VERSION ""

NS_ :

BS_:

BU_: ECM
VAL_TABLE_ EngAutoStrtEnVal 3 "Not Available" 2 "Error" 1 "On" 0 "Off" ;
VAL_TABLE_ OperatorInducementSeverity 7 "Not Available / Not Supported" 6 "Reserved" 5 "Inducement Level 5" 4 "Inducement Level 4" 3 "Inducement Level 3" 2 "Inducement Level 2" 1 "Inducement Level 1" 0 "No Inducement Active" ;
VAL_TABLE_ DEFTankLowlevelLamp 7 "not available" 6 "reserved for SAE assignment" 5 "reserved for SAE assignment" 4 "On – fast blink (1 HZ)" 3 "reserved for SAE assignment" 2 "reserved for SAE assignment" 1 "On – solid" 0 "Off" ;
VAL_TABLE_ MonitorFaultStatus 1 "Fault Condition present" 0 "Fault condition Absent" ;
VAL_TABLE_ MonitorEntryStatus 1 "Monitor Entry Conditions met" 0 "Monitor Entry Not Met" ;
VAL_TABLE_ Vt_YesNo_2bit 3 "Not Available" 2 "Error" 1 "Yes" 0 "No" ;
VAL_TABLE_ Vt_ProgShiftDis 3 "Take no action" 2 "Reserved" 1 "Progressive shift is disabled" 0 "Progressive shift not disabled" ;
VAL_TABLE_ Vt_EngMomOvrSpdEn 3 "Take no action" 2 "Reserved" 1 "Moment. eng. overspeed enabled" 0 "Moment. eng. overspeed disabled" ;
VAL_TABLE_ Vt_SPN_0911 255 "Component ID not available" 254 "Error" 253 "No action to be taken" 252 "Reset all components" 251 "Reserved" 250 "Reserved" 249 "Manufacturer specific" 248 "Manufacturer specific" 247 "Manufacturer specific" 246 "Manufacturer specific" 245 "Manufacturer specific" 244 "Manufacturer specific" 243 "Manufacturer specific" 242 "Manufacturer specific" 241 "Manufacturer specific" 240 "Manufacturer specific" 239 "Not defined" 238 "Not defined" 237 "Not defined" 236 "Not defined" 235 "Not defined" 234 "Not defined" 233 "Not defined" 232 "Not defined" 231 "Not defined" 230 "Not defined" 229 "Not defined" 228 "Not defined" 227 "Not defined" 226 "Not defined" 225 "Not defined" 224 "Not defined" 223 "Not defined" 222 "Not defined" 221 "Not defined" 220 "Not defined" 219 "Not defined" 218 "Not defined" 217 "Not defined" 216 "Not defined" 215 "Not defined" 214 "Not defined" 213 "Not defined" 212 "Not defined" 211 "Not defined" 210 "Not defined" 209 "Not defined" 208 "Not defined" 207 "Not defined" 206 "Not defined" 205 "Not defined" 204 "Not defined" 203 "Not defined" 202 "Not defined" 201 "Not defined" 200 "Not defined" 199 "Not defined" 198 "Not defined" 197 "Not defined" 196 "Not defined" 195 "Not defined" 194 "Not defined" 193 "Not defined" 192 "Not defined" 191 "Not defined" 190 "Not defined" 189 "Not defined" 188 "Not defined" 187 "Not defined" 186 "Not defined" 185 "Not defined" 184 "Not defined" 183 "Not defined" 182 "Not defined" 181 "Not defined" 180 "Not defined" 179 "Not defined" 178 "Not defined" 177 "Not defined" 176 "Not defined" 175 "Not defined" 174 "Not defined" 173 "Not defined" 172 "Not defined" 171 "Not defined" 170 "Not defined" 169 "Not defined" 168 "Not defined" 167 "Not defined" 166 "Not defined" 165 "Not defined" 164 "Not defined" 163 "Not defined" 162 "Not defined" 161 "Not defined" 160 "Not defined" 159 "Not defined" 158 "Not defined" 157 "Not defined" 156 "Not defined" 155 "Not defined" 154 "Not defined" 153 "Not defined" 152 "Not defined" 151 "Not defined" 150 "Not defined" 149 "Not defined" 148 "Not defined" 147 "Not defined" 146 "Not defined" 145 "Not defined" 144 "Not defined" 143 "Not defined" 142 "Not defined" 141 "Not defined" 140 "Not defined" 139 "Not defined" 138 "Not defined" 137 "Not defined" 136 "Not defined" 135 "Not defined" 134 "Not defined" 133 "Not defined" 132 "Not defined" 131 "Not defined" 130 "Not defined" 129 "Not defined" 128 "Not defined" 127 "Not defined" 126 "Not defined" 125 "Not defined" 124 "Not defined" 123 "Not defined" 122 "Not defined" 121 "Not defined" 120 "Not defined" 119 "Not defined" 118 "Not defined" 117 "Not defined" 116 "Not defined" 115 "Not defined" 114 "Not defined" 113 "Not defined" 112 "Not defined" 111 "Not defined" 110 "Not defined" 109 "Not defined" 108 "Not defined" 107 "Not defined" 106 "Not defined" 105 "Not defined" 104 "Not defined" 103 "Not defined" 102 "Not defined" 101 "Not defined" 100 "Not defined" 99 "Not defined" 98 "Not defined" 97 "Not defined" 96 "Not defined" 95 "Not defined" 94 "Not defined" 93 "Not defined" 92 "Not defined" 91 "Not defined" 90 "Not defined" 89 "Not defined" 88 "Not defined" 87 "Not defined" 86 "Not defined" 85 "Not defined" 84 "Not defined" 83 "Not defined" 82 "Not defined" 81 "Not defined" 80 "Not defined" 79 "Not defined" 78 "Not defined" 77 "Not defined" 76 "Not defined" 75 "Not defined" 74 "Not defined" 73 "Not defined" 72 "Not defined" 71 "Not defined" 70 "Not defined" 69 "Not defined" 68 "Not defined" 67 "Not defined" 66 "Not defined" 65 "Not defined" 64 "Not defined" 63 "Driver card #2" 62 "Driver card #1" 61 "Tachograph" 60 "Not defined" 59 "Not defined" 58 "Not defined" 57 "Not defined" 56 "Not defined" 55 "Not defined" 54 "Not defined" 53 "Not defined" 52 "Not defined" 51 "Engine fuel filter" 50 "Engine oil filter" 49 "Engine air filter" 48 "Tires" 47 "Not defined" 46 "Not defined" 45 "Not defined" 44 "Not defined" 43 "Rear axle oil" 42 "Front axle oil" 41 "Not defined" 40 "Intermediate transmission oil" 39 "Trans oil filter transmission #1" 38 "Trans oil transmission #2" 37 "Trans oil transmission #1" 36 "Not defined" 35 "Steering oil" 34 "Not defined" 33 "Engine oil engine #2" 32 "Engine oil engine #1" 31 "Engine coolant filter change" 30 "Engine coolant change" 29 "Not defined" 28 "Not defined" 27 "Not defined" 26 "Not defined" 25 "Not defined" 24 "Not defined" 23 "Not defined" 22 "Not defined" 21 "Check vehicle speed limiter" 20 "Check exhaust gas" 19 "Check trip recorder" 18 "In-between check" 17 "Brake system special check" 16 "Reg. gen. check for entire veh." 15 "Brake lining: general" 14 "Brake lining; right rear axle #3" 13 "Brake lining; left rear axle #3" 12 "Brake lining; right rear axle #2" 11 "Brake lining; left rear axle #2" 10 "Not defined" 9 "Not defined" 8 "Not defined" 7 "Not defined" 6 "Not defined" 5 "Clutch lining" 4 "Brake lining; right rear axle" 3 "Brake lining; left rear axle" 2 "Brake lining; right front axle" 1 "Brake lining; left front axle" 0 "Service check for entire vehicle" ;
VAL_TABLE_ AFT_Heater_Control 3 "Heater off" 2 "Preheat 1" 1 "Preheat 2" 0 "Automatic" ;
VAL_TABLE_ ASCiiPROD1 122 "z" 121 "y" 120 "x" 119 "w" 118 "v" 117 "u" 116 "t" 115 "s" 114 "r" 113 "q" 112 "p" 111 "o" 110 "n" 109 "m" 108 "l" 107 "k" 106 "j" 105 "i" 104 "h" 103 "g" 102 "f" 101 "e" 100 "d" 99 "c" 98 "b" 97 "a" 42 "*" 90 "Z" 89 "Y" 88 "X" 87 "W" 86 "V" 85 "U" 84 "T" 83 "S" 82 "R" 81 "Q" 80 "P" 79 "O" 78 "N" 77 "M" 76 "L" 75 "K" 74 "J" 73 "I" 72 "H" 71 "G" 70 "F" 69 "E" 68 "D" 67 "C" 66 "B" 65 "A" 57 "9" 56 "8" 55 "7" 54 "6" 53 "5" 52 "4" 51 "3" 50 "2" 49 "1" 48 "0" ;
VAL_TABLE_ SPN7121 2 "Exhaust Pressure Control" 1 "Torque Control" 0 "Brake Disabled" ;
VAL_TABLE_ SPN7334 1 "active" 0 "inactive" ;
VAL_TABLE_ SPN7022 3 "not available" 2 "error" 1 "active" 0 "inactive" ;
VAL_TABLE_ RetarderInhibitEBSSwitchStatus 2 "Error" 1 "Active" 0 "Inactive" ;
VAL_TABLE_ Disable_Enable_Error 3 "Not available" 2 "Error" 1 "Enabled" 0 "Disabled" ;
VAL_TABLE_ ResultStatusOfPressBuild 2 "MinimumTime Expired" 1 "Maximum Time Expired" 0 "Pressure Reached Within Time" ;
VAL_TABLE_ EGRcancleRequest 1 "EGR Off" 0 "EGR On" ;
VAL_TABLE_ LowIdleControlParamSet 1 "AutoTransLowIdleControl" 0 "ManualTransLowIdleControl" ;
VAL_TABLE_ IntermedSpeedContParamSet 5 "Speed Govenor" 4 "Transmission Override Control" 3 "High PTO" 2 "Medium PTO" 1 "Base PTO" 0 "default" ;
VAL_TABLE_ CurrentWorkingModeOfEngineSpeed 2 "Crank Sig Missing or Not Plaus" 1 "Cams Sig Missing or Not Plaus" 0 "Both Sensors Working Correctly" ;
VAL_TABLE_ Flag 1 "Fault" 0 "No Fault" ;
VAL_TABLE_ DiagnosticTestAssignments_ETR 64 "Cancel Current Test" ;
VAL_TABLE_ Override_control_mode 3 "Not used" 2 "Pressure Control" 1 "Torque control" 0 "Override disabled" ;
VAL_TABLE_ ParticulateTrapActive_Inhibit 3 "not available" 2 "reserved for SAE assignment" 1 "inhibited" 0 "not inhibited" ;
VAL_TABLE_ ParticulateTrapStatus 7 "not available" 6 "reserved for SAE assignment" 5 "reserved for SAE assignment" 4 "reserved for SAE assignment" 3 "Regen needed highest level" 2 "Regen needed moderate level" 1 "Regen needed lowest level" 0 "Regeneration not needed" ;
VAL_TABLE_ PartTrActiveRegenStatus 3 "not available" 2 "RegenNeeded_AutoRegenImminent" 1 "active" 0 "not active" ;
VAL_TABLE_ PartTrPassiveRegenStatus 3 "not available" 2 "reserved for SAE assignment" 1 "active" 0 "not active" ;
VAL_TABLE_ ExhSysHiTempLampCommand 7 "not available" 6 "reserved for SAE assignment" 5 "reserved for SAE assignment" 4 "On fast blink 1Hz" 3 "reserved for SAE assignment" 2 "reserved for SAE assignment" 1 "On Solid" 0 "Off" ;
VAL_TABLE_ PartTrAutoActRegenInitiatConfig 3 "not available" 2 "reserved for SAE assignment" 1 "Enabled" 0 "Not Enabled" ;
VAL_TABLE_ TransDriveEngaged 3 "NotAvailable" 2 "Error" 1 "DriveIsEngaged" 0 "DriveNotEngaged" ;
VAL_TABLE_ OverrideControlMode 3 "not defined error" 2 "Speed control" 1 "Torque control" 0 "Override disabled" ;
VAL_TABLE_ ReturnCodePPprogMode 16 "EngineOperatingModeNotNoStrtMode" 15 "DataBlockTooLongToTransmit" 14 "InvalidPasswordLevelProvided" 13 "ParameterHasNoAssociatedTatFiled" 12 "Reserved" 11 "InvalidParamtersWereRequested" 10 "LengthOfDataProvidedTooLong_Shrt" 9 "DataBlockTooLongToTransmitNotPro" 8 "ProgrammingModeTimeout" 7 "CannotWRITEaReadOnlyField" 6 "CannotREADaWriteOnlyField" 5 "CalibrationMemoryFailure" 4 "VehicleMoving" 3 "EngineRunninge" 2 "ProprietaryPasswordNotMatch" 1 "CustomerPasswordNotMatch" 0 "ProgramCommandSuccessful" ;
VAL_TABLE_ ReturnCodesEIMprogram 20 "Prog messg pack receiv out seque" 19 "reserved for future use" 18 "Flash ROM segment not erased" 17 "TP data crc mismatch" 16 "Eng Op Mode not in No_Start" 15 "reserved for future use" 14 "reserved for future use" 13 "Improper command sequence" 12 "reserved for future use" 11 "Invalid parameters" 10 "Length of data 2 long or invalid" 9 "Multiple faults detected" 8 "Programming mode timeout" 7 "reserved for future use" 6 "Invalid strat or cal ROMchecksum" 5 "Flash programming failure" 4 "Vehicle moving" 3 "Engine running" 2 "Transp param password not match" 1 "Undefined request command" 0 "Programming command successful" ;
VAL_TABLE_ DiagnosticTestAssignments 82 "High Pressure Service Test" 72 "DFSOV Leak Test" 71 "Injector Leak Test" 70 "Doser Flow Test" 66 "Test of Cylinder Cut Out Test" 65 "Test of Cylinder Cut Out Test" 64 "Test of Cylinder Cut Out Test" 57 "Test of Cylinder Cut Out Test" 56 "Test of Cylinder Cut Out Test" 55 "Test of Cylinder Cut Out Test" 54 "Run Up Test" 18 "Compression Test" 52 "Actuator Test" ;
VAL_TABLE_ EGRactive 3 "not available not installed" 2 "EGR system not valid" 1 "EGR valve oopen" 0 "EGR valve closed" ;
VAL_TABLE_ Hex2ASCii 90 "Z" 89 "Y" 88 "X" 87 "W" 86 "V" 85 "U" 84 "T" 83 "S" 82 "R" 81 "Q" 80 "P" 79 "O" 78 "N" 77 "M" 76 "L" 75 "K" 74 "J" 73 "I" 72 "H" 71 "G" 70 "F" 69 "E" 68 "D" 67 "C" 66 "B" 65 "A" 57 "9" 56 "8" 55 "7" 54 "6" 53 "5" 52 "4" 51 "3" 50 "2" 49 "1" 48 "0" ;
VAL_TABLE_ NoRequest_RequestActive 1 "Request Active" 0 "No Request" ;
VAL_TABLE_ Acitve_NotActive2 1 "Not Active" 0 "Active" ;
VAL_TABLE_ StateOfTerminal15 1 "ON" 0 "OFF" ;
VAL_TABLE_ EDCmode 7 "shutoff" 6 "EDC in standalone mode" 5 "Afterrun" 4 "Normal STRT_S_AFTER_DUC" 2 "Normal STRT_S_DURING_DUC" 1 "Normal STRT_S_BEFORE_DUC" ;
VAL_TABLE_ Active_NotActive 1 "Active" 0 "Not Active" ;
VAL_TABLE_ EDCStatus 3 "Invalid Operating Mode" 2 "Invalid Operating Mode" 1 "Invalid Operating Mode" 0 "EDC Ok" ;
VAL_TABLE_ HCIMFlags 1 "Fault" 0 "No Fault" ;
VAL_TABLE_ ATConfigurationID 15 "TBD" 14 "TBD" 13 "TBD" 12 "TBD" 11 "TBD" 10 "TBD" 9 "TBD" 8 "TBD" 7 "TBD" 6 "TBD" 5 "TBD" 4 "TBD" 3 "TBD" 2 "TBD" 1 "TBD" 0 "TBD" ;
VAL_TABLE_ ShutdownRequest 3 "NA" 2 "Error" 1 "True" 0 "False" ;
VAL_TABLE_ OperatingModes 31 "ITEC Reserved" 30 "ITEC Reserved" 29 "ITEC Reserved" 28 "ITEC Reserved" 27 "ITEC Reserved" 26 "ITEC Reserved" 25 "ITEC Reserved" 24 "ForceRegen" 23 "ITEC Reserved" 22 "ITEC Reserved" 21 "RegenUnavail" 20 "Oxid Boost" 19 "DeSoot" 18 "NOx Boost" 17 "Normal" 16 "ITEC Reserved" ;
VAL_TABLE_ unused_16_ones 65535 "Correct Message Structure" ;
VAL_TABLE_ PanelBacklightDimmer 15 "100%" 14 "95%" 13 "89%" 12 "83%" 11 "77%" 10 "71%" 9 "65%" 8 "59%" 7 "53%" 6 "47%" 5 "41%" 4 "35%" 3 "29%" 2 "23%" 1 "15%" 0 "OFF" ;
VAL_TABLE_ DigitalInput 1 "On" 0 "Off" ;
VAL_TABLE_ RightSideOptionalSwitch 3 "Error" 2 "Up Position" 1 "Down Position" 0 "Center Position" ;
VAL_TABLE_ LeftSideOptionalSwitch 1 "Switch Depressed" 0 "Not Depressed" ;
VAL_TABLE_ Header 2 "Command Message" ;
VAL_TABLE_ Alarm 7 "Repetative One Short Beep" 6 "One Time Three Long Beeps" 5 "One Time Ten Short Beeps " 4 "One Time Five Short Beeps" 3 "One Time Short Beep" 2 "One Time Long Beep" 1 "Continuous Single Tone" 0 "Off" ;
VAL_TABLE_ DoorSwitch 1 "Doors Open" 0 "Doors Closed" ;
VAL_TABLE_ DiagnosticRequest 1 "Diagnostic Mode Active" 0 "Diagnostic Mode Inactive" ;
VAL_TABLE_ Accessory 1 "Accessory On" 0 "Accessory Off" ;
VAL_TABLE_ SwitchedIgnition 1 "Ignition On" 0 "Ignition Off" ;
VAL_TABLE_ PTOhours 1 "Engaged" 0 "Not Engaged" ;
VAL_TABLE_ PanelLightRequest 1 "Request" 0 "Not Request" ;
VAL_TABLE_ TextMessage 1 "ON" 0 "OFF" ;
VAL_TABLE_ SmokeMapSelectionID 3 "Request not avail from EIM" 2 "Smoke map 2" 1 "Smoke map 1" 0 "Smoke map 0" ;
VAL_TABLE_ VehicleStop 1 "Vehicle stop" 0 "No vehicle stop" ;
VAL_TABLE_ EDCstandAloneModeRequest 3 "as 01+ failure memory entry" 2 "as 01+ failure memory entry" 1 "EDC stand alone, ignore EIM" 0 "Normal EDC mode, specs by EIM" ;
VAL_TABLE_ EngineStopRequest 3 "not valid, as 00, FailMemEntry" 2 "not valid, as 00, FailMemEntry" 1 "Engine Stop Request" 0 "Normal mode, no stop request" ;
VAL_TABLE_ EngineStartRequest 3 "not valid, as 00, FailMemEntry" 2 "Emergency Start Request" 1 "Normal start request" 0 "Normal Mode, no start request" ;
VAL_TABLE_ LowIdleControllerIDparamSet 3 "invalid, use ID 0, FailMemEntry" 2 "Param set 2 for LICO" 1 "Param set 1 for LICO" 0 "Param set 0 (deafult) for LICO" ;
VAL_TABLE_ DrivelineEngagedInformation 3 "Request not avail from FFR-EIM" 2 "Error!!!!" 1 "Driveline Engaged" 0 "Driveline Disengaged" ;
VAL_TABLE_ MasterSlaveBankShutOff 3 "Request not avail from FFR-EIM" 2 "Error!!" 1 "Bank Shutoff Disabled" 0 "Bank Shutoff Enabled" ;
VAL_TABLE_ RampOffSwitch 3 "not valid, as 00, FailMemEntry" 2 "not valid, as 00, FailMemEntry" 1 "rampoff, setpoint applied direct" 0 "EDC ramp transition active" ;
VAL_TABLE_ StatusOfEngineBraking 3 "not valid, set 00, FailMemEntry" 2 "not valid, set 00, FailMemEntry" 1 "MBR active" 0 "MBR not active" ;
VAL_TABLE_ IDparamSet4HighIdleController 7 "invalid, use ID 0, FailMemEntry" 6 "invalid, use ID 0, FailMemEntry" 5 "Param set 5 for HICO" 4 "Param set 4 for HICO" 3 "Param set 3 for HICO" 2 "Param set 2 for HICO" 1 "Param set 1 for HICO" 0 "Param set 0 (default) for HICO" ;
VAL_TABLE_ IDparamForIntrmdtSpdCntrllr 7 "Param set 7 for ISCT" 6 "Param set 6 for ISCT" 5 "Param set 5 for ISCT" 4 "Param set 4 for ISCT" 3 "Param set 3 for ISCT" 2 "Param set 2 for ISCT" 1 "Param set 1 for ISCT" 0 "Param set 0 (default) for ISCT" ;
VAL_TABLE_ momentaryEngineOverspeedEnable 3 "invalid, meos disabled + failmem" 2 "invalid, meos disabled + failmem" 1 "meos enabled" 0 "meos disabled" ;
VAL_TABLE_ HCIM_fault_flag 1 "Fault" 0 "No fault" ;

BO_ 2365440512 EEC14: 8 Vector__XXX
 SG_ FuelType : 56|8@1+ (1,0) [0|255] "" Vector__XXX

BO_ 2560818944 DM32: 40 Vector__XXX
 SG_ DTC_Total_PrevActive_Time_5 : 296|16@1+ (0.2,0) [0|13107] "hr" Vector__XXX
 SG_ DTC_Total_Active_Time_5 : 280|16@1+ (0.2,0) [0|13107] "hr" Vector__XXX
 SG_ DTC_Time_Until_Derate_5 : 312|8@1+ (0.25,0) [0|63.75] "hr" Vector__XXX
 SG_ DTC_Total_PrevActive_Time_4 : 232|16@1+ (0.2,0) [0|13107] "hr" Vector__XXX
 SG_ DTC_Total_Active_Time_4 : 216|16@1+ (0.2,0) [0|13107] "hr" Vector__XXX
 SG_ DTC_Time_Until_Derate_4 : 248|8@1+ (0.25,0) [0|63.75] "hr" Vector__XXX
 SG_ DTC_Total_PrevActive_Time_3 : 168|16@1+ (0.2,0) [0|13107] "hr" Vector__XXX
 SG_ DTC_Total_Active_Time_3 : 152|16@1+ (0.2,0) [0|13107] "hr" Vector__XXX
 SG_ DTC_Time_Until_Derate_3 : 184|8@1+ (0.25,0) [0|63.75] "hr" Vector__XXX
 SG_ DTC_Total_PrevActive_Time_2 : 104|16@1+ (0.2,0) [0|13107] "hr" Vector__XXX
 SG_ DTC_Total_Active_Time_2 : 88|16@1+ (0.2,0) [0|13107] "hr" Vector__XXX
 SG_ DTC_Time_Until_Derate_2 : 120|8@1+ (0.25,0) [0|63.75] "hr" Vector__XXX
 SG_ DTC_Total_PrevActive_Time_1 : 40|16@1+ (0.2,0) [0|13107] "hr" Vector__XXX
 SG_ DTC_Total_Active_Time_1 : 24|16@1+ (0.2,0) [0|13107] "hr" Vector__XXX
 SG_ DTC_Time_Until_Derate_1 : 56|8@1+ (0.25,0) [0|63.75] "hr" Vector__XXX
 SG_ SPN5 : 256|16@1+ (1,0) [0|65536] "" Vector__XXX
 SG_ SPN4 : 192|16@1+ (1,0) [0|65536] "" Vector__XXX
 SG_ SPN3 : 128|16@1+ (1,0) [0|65536] "" Vector__XXX
 SG_ SPN2 : 64|16@1+ (1,0) [0|65536] "" Vector__XXX
 SG_ FailureModeIdentifier1 : 16|5@1+ (1,0) [0|0] "" Vector__XXX
 SG_ SPN1 : 0|16@1+ (1,0) [0|65536] "" Vector__XXX
 SG_ FailureModeIdentifier2 : 80|5@1+ (1,0) [0|0] "" Vector__XXX
 SG_ SPN5High : 277|3@1+ (1,0) [0|7] "" Vector__XXX
 SG_ SPN4High : 213|3@1+ (1,0) [0|7] "" Vector__XXX
 SG_ SPN3High : 149|3@1+ (1,0) [0|7] "" Vector__XXX
 SG_ SPN2High : 85|3@1+ (1,0) [0|7] "" Vector__XXX
 SG_ SPN1High : 21|3@1+ (1,0) [0|7] "" Vector__XXX

BO_ 2633926400 IT6: 8 Vector__XXX
 SG_ EngActualIgnTiming : 48|16@1- (0.0078125,-200) [-200|301.99] "Deg" Vector__XXX

BO_ 2365484270 TCO1: 8 Vector__XXX
 SG_ TachographVehicleSpeed : 48|16@1+ (0.00390625,0) [0|250.996] "km/h" Vector__XXX

BO_ 2566892544 EDR4: 8 Vector__XXX

BO_ 2566892288 EDR3: 8 Vector__XXX

BO_ 2566892032 EDR2: 8 Vector__XXX

BO_ 2566891776 EDR1: 8 Vector__XXX

BO_ 2566831399 FD_s39: 8 Vector__XXX
 SG_ FanSpeed_Rx : 16|16@1+ (0.125,0) [0|8031.875] "rpm" Vector__XXX

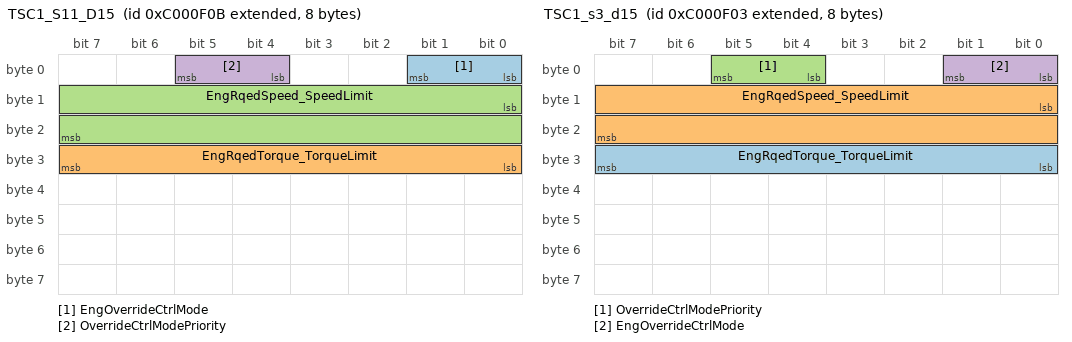
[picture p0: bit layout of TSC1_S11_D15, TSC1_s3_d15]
BO_ 2348814091 TSC1_S11_D15: 8 Vector__XXX
 SG_ EngOverrideCtrlMode : 0|2@1+ (1,0) [0|3] "" Vector__XXX
 SG_ EngRqedTorque_TorqueLimit : 24|8@1+ (1,-125) [-125|125] "%" Vector__XXX
 SG_ EngRqedSpeed_SpeedLimit : 8|16@1+ (0.125,0) [0|8031.875] "rpm" Vector__XXX
 SG_ OverrideCtrlModePriority : 4|2@1+ (1,0) [0|3] "" Vector__XXX

BO_ 2348814083 TSC1_s3_d15: 8 Vector__XXX
 SG_ EngRqedTorque_TorqueLimit : 24|8@1+ (1,-125) [-125|125] "%" Vector__XXX
 SG_ EngRqedSpeed_SpeedLimit : 8|16@1+ (0.125,0) [0|8031.875] "rpm" Vector__XXX
 SG_ OverrideCtrlModePriority : 4|2@1+ (1,0) [0|3] "" Vector__XXX
 SG_ EngOverrideCtrlMode : 0|2@1+ (1,0) [0|3] "" Vector__XXX

BO_ 2566820864 EAC: 8 Vector__XXX
 SG_ EngExRangeCoolantPres : 24|8@1+ (4,0) [0|1020] "kPa" Vector__XXX

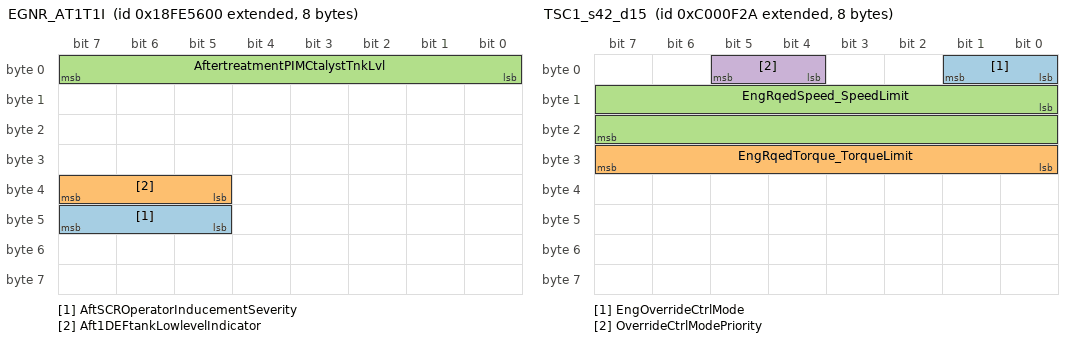
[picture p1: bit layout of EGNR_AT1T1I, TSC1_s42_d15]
BO_ 2566804992 EGNR_AT1T1I: 8 Vector__XXX
 SG_ AftSCROperatorInducementSeverity : 45|3@1- (1,0) [0|7] "" Vector__XXX
 SG_ Aft1DEFtankLowlevelIndicator : 37|3@1- (1,0) [0|7] "" Vector__XXX
 SG_ AftertreatmentPIMCtalystTnkLvl : 0|8@1+ (0.4,0) [0|100] "%" Vector__XXX

BO_ 2564816899 CM1_s03: 8 Vector__XXX
 SG_ Req_Pct_Fan_Speed_Trans : 0|8@1+ (0.4,0) [0|100] "%" Vector__XXX

BO_ 2633974265 PROP_RESET: 8 Vector__XXX
 SG_ PropResetInfo : 0|8@1+ (1,0) [0|255] "" Vector__XXX

BO_ 2364539392 ETC1_s0: 8 Vector__XXX
 SG_ TransOutputShaftSpeed_Tx : 8|16@1+ (0.125,0) [0|8031.875] "rpm" Vector__XXX

BO_ 2348814122 TSC1_s42_d15: 8 Vector__XXX
 SG_ EngOverrideCtrlMode : 0|2@1+ (1,0) [0|3] "" Vector__XXX
 SG_ EngRqedTorque_TorqueLimit : 24|8@1+ (1,-125) [-125|125] "%" Vector__XXX
 SG_ EngRqedSpeed_SpeedLimit : 8|16@1+ (0.125,0) [0|8031.875] "rpm" Vector__XXX
 SG_ OverrideCtrlModePriority : 4|2@1+ (1,0) [0|3] "" Vector__XXX

BO_ 2566803754 ACC2_s42: 8 Vector__XXX
 SG_ ReqACCDistMode : 5|3@1+ (1,0) [0|7] "" Vector__XXX

BO_ 2564882176 CM1_s0: 8 Vector__XXX
 SG_ Req_Pct_Fan_Speed_ECM : 0|8@1+ (0.4,0) [0|100] "%" Vector__XXX

BO_ 2631859961 RESET_s249: 8 Vector__XXX
 SG_ EST_Trip_Reset : 2|2@1+ (1,0) [0|3] "" Vector__XXX

BO_ 2561081377 AUXIO2_s33: 8 Vector__XXX
 SG_ GovSelSwitch : 4|2@1+ (1,0) [0|3] "" Vector__XXX
 SG_ DataLogSwitch : 6|2@1+ (1,0) [0|3] "" Vector__XXX

BO_ 2566844683 CCVS_s11: 8 Vector__XXX
 SG_ WheelBasedVehicleSpeed : 8|16@1+ (0.00390625,0) [0|250.996] "km/h" Vector__XXX

BO_ 2566844714 CCVS_s42: 8 Vector__XXX
 SG_ CruiseCtrlResumeSwitch : 36|2@1+ (1,0) [0|3] "" Vector__XXX
 SG_ CruiseCtrlPauseSwitch : 4|2@1+ (1,0) [0|3] "" Vector__XXX

BO_ 2566847009 BRAKES: 8 Vector__XXX
 SG_ Brake_Primary_Pressure : 8|8@1+ (4,0) [0|1020] "kPa" Vector__XXX

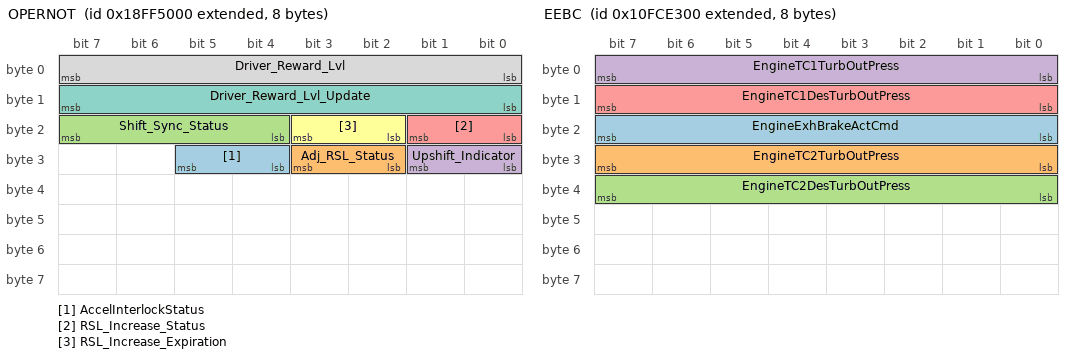
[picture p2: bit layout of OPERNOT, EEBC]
BO_ 2566868992 OPERNOT: 8 Vector__XXX
 SG_ AccelInterlockStatus : 28|2@1+ (1,0) [0|3] "" Vector__XXX
 SG_ Adj_RSL_Status : 26|2@1+ (1,0) [0|3] "" Vector__XXX
 SG_ Shift_Sync_Status : 20|4@1+ (1,0) [0|15] "" Vector__XXX
 SG_ Upshift_Indicator : 24|2@1+ (1,0) [0|3] "" Vector__XXX
 SG_ RSL_Increase_Status : 16|2@1+ (1,0) [0|3] "" Vector__XXX
 SG_ RSL_Increase_Expiration : 18|2@1+ (1,0) [0|3] "" Vector__XXX
 SG_ Driver_Reward_Lvl_Update : 8|8@1+ (1,0) [0|255] "" Vector__XXX
 SG_ Driver_Reward_Lvl : 0|8@1+ (1,0) [0|255] "" Vector__XXX

BO_ 2432498944 EEC9: 8 Vector__XXX
 SG_ EngCmdFuelRailPress : 32|16@1+ (0.00390625,0) [0|251] "MPa" Vector__XXX

BO_ 2565865470 PROMODE1_sxx: 8 Vector__XXX
 SG_ OpModeReq : 0|32@1+ (1,0) [0|4294967295] "" Vector__XXX

BO_ 2565865216 PROMODE1_s0: 8 Vector__XXX
 SG_ OpModeCur : 32|32@1+ (1,0) [0|4294967295] "" Vector__XXX

BO_ 2633936896 TTI2: 20 Vector__XXX
 SG_ TripEngRunTime : 64|32@1+ (0.05,0) [0|214748364.75] "hr" Vector__XXX
 SG_ TripIdleTime : 96|32@1+ (0.05,0) [0|214748364.75] "hr" Vector__XXX

BO_ 2633939200 LTFI: 22 Vector__XXX
 SG_ TripPTOStaFuelUsed : 64|32@1+ (0.5,0) [0|2147483647.5] "L" Vector__XXX
 SG_ TripPTOMovingFuelUsed : 32|32@1+ (0.5,0) [0|2147483647.5] "L" Vector__XXX
 SG_ TripIdleFuelUsed : 96|32@1+ (0.5,0) [0|2147483647.5] "L" Vector__XXX

BO_ 2432520704 ECCVC: 8 Vector__XXX
 SG_ EngAuxCoolerSupValve2 : 32|8@1+ (0.4,0) [0|102] "%" Vector__XXX
 SG_ EngAuxCoolerSupValve1 : 24|8@1+ (0.4,0) [0|102] "%" Vector__XXX

BO_ 2432492288 EEBC: 8 Vector__XXX
 SG_ EngineExhBrakeActCmd : 16|8@1+ (0.4,0) [0|102] "%" Vector__XXX
 SG_ EngineTC2TurbOutPress : 24|8@1+ (2,0) [0|510] "kPa" Vector__XXX
 SG_ EngineTC2DesTurbOutPress : 32|8@1+ (2,0) [0|510] "kPa" Vector__XXX
 SG_ EngineTC1TurbOutPress : 0|8@1+ (2,0) [0|510] "kPa" Vector__XXX
 SG_ EngineTC1DesTurbOutPress : 8|8@1+ (2,0) [0|510] "kPa" Vector__XXX

BO_ 2633927680 AAI: 8 Vector__XXX
 SG_ Relative_Humidity : 48|8@1+ (0.4,0) [0|102] "%" Vector__XXX

BO_ 2566861857 EWE_s33: 8 Vector__XXX
 SG_ EngineWarmupEnable : 16|2@1+ (1,0) [0|3] "" Vector__XXX

BO_ 2566848256 WIF: 8 Vector__XXX
 SG_ WIF : 0|2@1+ (1,0) [0|3] "" Vector__XXX

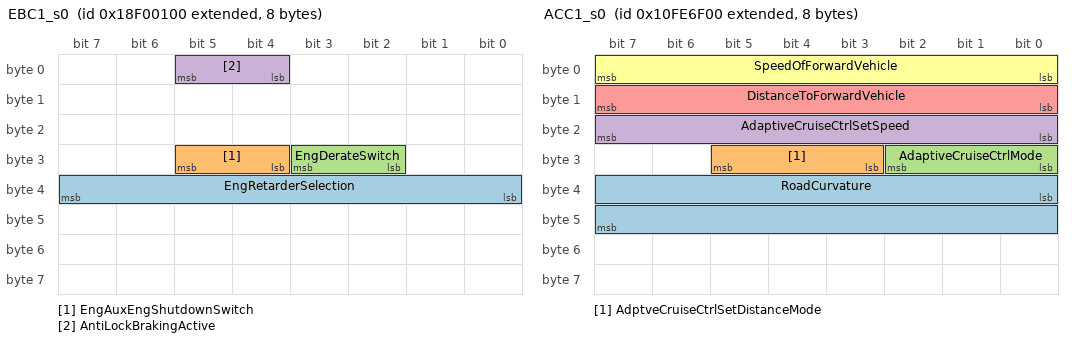
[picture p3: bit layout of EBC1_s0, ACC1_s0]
BO_ 2565865728 EBC1_s0: 8 Vector__XXX
 SG_ EngRetarderSelection : 32|8@1+ (0.4,0) [0|100] "%" Vector__XXX
 SG_ EngAuxEngShutdownSwitch : 28|2@1+ (1,0) [0|3] "" Vector__XXX
 SG_ EngDerateSwitch : 26|2@1+ (1,0) [0|3] "" Vector__XXX
 SG_ AntiLockBrakingActive : 4|2@1+ (1,0) [0|3] "" Vector__XXX

BO_ 2566854656 AETP: 8 Vector__XXX
 SG_ ActualEngineTorque : 0|8@1+ (30,0) [0|7500] "N.m" Vector__XXX

BO_ 2432593664 ACC1_s0: 8 Vector__XXX
 SG_ RoadCurvature : 32|16@1+ (0.0078125,-250) [-250|251.992] "1/km" Vector__XXX
 SG_ AdptveCruiseCtrlSetDistanceMode : 27|3@1+ (1,0) [0|7] "" Vector__XXX
 SG_ AdaptiveCruiseCtrlMode : 24|3@1+ (1,0) [0|7] "" Vector__XXX
 SG_ AdaptiveCruiseCtrlSetSpeed : 16|8@1+ (1,0) [0|250] "km/h" Vector__XXX
 SG_ DistanceToForwardVehicle : 8|8@1+ (1,0) [0|250] "m" Vector__XXX
 SG_ SpeedOfForwardVehicle : 0|8@1+ (1,0) [0|250] "km/h" Vector__XXX

BO_ 2364539681 EEC2_s21: 8 Vector__XXX
 SG_ RemoteAccelPedalPos : 24|8@1+ (0.4,0) [0|100] "%" Vector__XXX

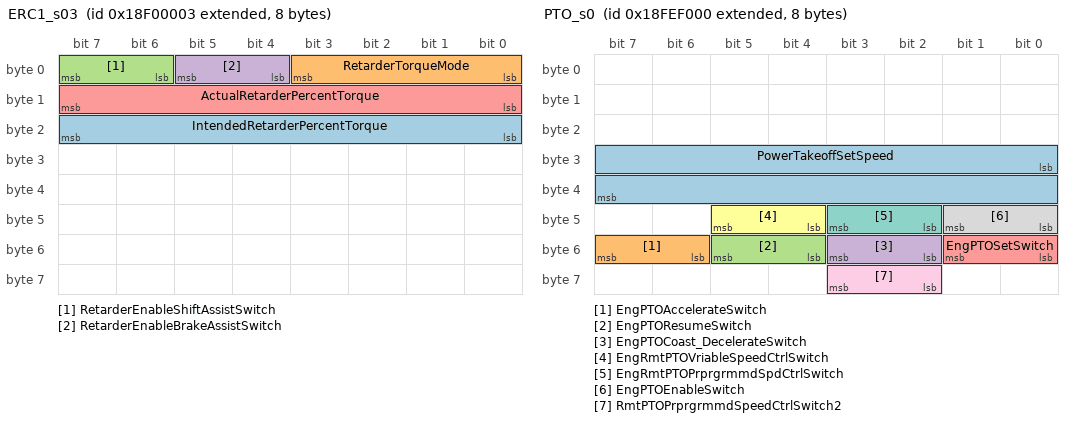
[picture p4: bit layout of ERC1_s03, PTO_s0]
BO_ 2565865475 ERC1_s03: 8 Vector__XXX
 SG_ IntendedRetarderPercentTorque : 16|8@1- (1,-125) [-125|125] "" Vector__XXX
 SG_ RetarderTorqueMode : 0|4@1- (1,0) [0|15] "" Vector__XXX
 SG_ RetarderEnableShiftAssistSwitch : 6|2@1+ (1,0) [0|3] "" Vector__XXX
 SG_ RetarderEnableBrakeAssistSwitch : 4|2@1+ (1,0) [0|3] "" Vector__XXX
 SG_ ActualRetarderPercentTorque : 8|8@1+ (1,-125) [-125|125] "%" Vector__XXX

BO_ 2566844416 PTO_s0: 8 Vector__XXX
 SG_ PowerTakeoffSetSpeed : 24|16@1+ (0.125,0) [0|8031.875] "rpm" Vector__XXX
 SG_ EngPTOAccelerateSwitch : 54|2@1+ (1,0) [0|3] "" Vector__XXX
 SG_ EngPTOResumeSwitch : 52|2@1+ (1,0) [0|3] "" Vector__XXX
 SG_ EngPTOCoast_DecelerateSwitch : 50|2@1+ (1,0) [0|3] "" Vector__XXX
 SG_ EngPTOSetSwitch : 48|2@1+ (1,0) [0|3] "" Vector__XXX
 SG_ EngRmtPTOVriableSpeedCtrlSwitch : 44|2@1+ (1,0) [0|3] "" Vector__XXX
 SG_ EngRmtPTOPrprgrmmdSpdCtrlSwitch : 42|2@1+ (1,0) [0|3] "" Vector__XXX
 SG_ EngPTOEnableSwitch : 40|2@1+ (1,0) [0|3] "" Vector__XXX
 SG_ RmtPTOPrprgrmmdSpeedCtrlSwitch2 : 58|2@1+ (1,0) [0|3] "" Vector__XXX

BO_ 2633935104 EO1: 8 Vector__XXX
 SG_ DesiredExhaustO2 : 16|16@1+ (0.0025,0) [0|160.6375] "%" Vector__XXX

BO_ 2566743296 AT1FC2: 8 Vector__XXX
 SG_ AT1HCDoserInFuelTemp : 40|8@1+ (1,-40) [-40|210] "°C" Vector__XXX
 SG_ Aftertreatment1FuelPress2 : 0|16@1+ (0.1,0) [0|6425.5] "kPa" Vector__XXX

BO_ 2566725632 A1DOC: 8 Vector__XXX
 SG_ Aftertreatment1DOCOutTemp : 16|16@1- (0.03125,-273) [-273|1734.96875] "deg C" Vector__XXX
 SG_ Aftertreatment1DOCInTemp : 0|16@1- (0.03125,-273) [-273|1734.96875] "deg C" Vector__XXX

BO_ 2633925376 IT2: 8 Vector__XXX
 SG_ EngCylinderIgnTiming6 : 16|16@1- (0.0078125,-200) [-200|301.99] "Deg" Vector__XXX
 SG_ EngCylinderIgnTiming5 : 0|16@1- (0.0078125,-200) [-200|301.99] "Deg" Vector__XXX

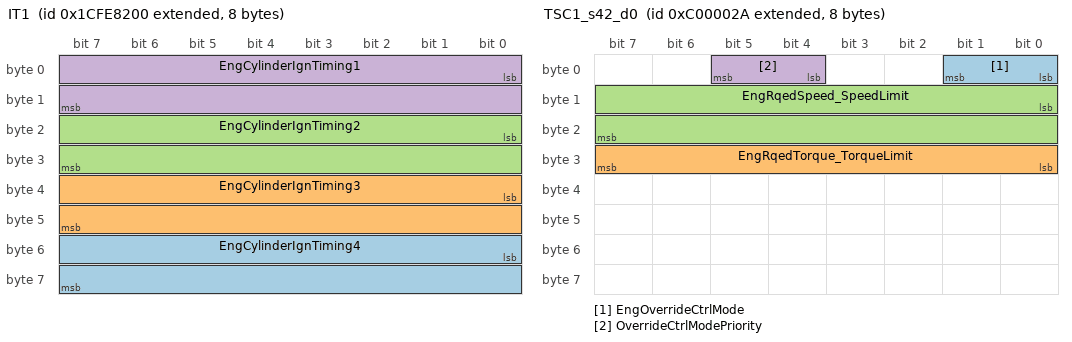
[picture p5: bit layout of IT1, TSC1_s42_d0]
BO_ 2633925120 IT1: 8 Vector__XXX
 SG_ EngCylinderIgnTiming4 : 48|16@1- (0.0078125,-200) [-200|301.99] "Deg" Vector__XXX
 SG_ EngCylinderIgnTiming3 : 32|16@1- (0.0078125,-200) [-200|301.99] "Deg" Vector__XXX
 SG_ EngCylinderIgnTiming2 : 16|16@1- (0.0078125,-200) [-200|301.99] "Deg" Vector__XXX
 SG_ EngCylinderIgnTiming1 : 0|16@1- (0.0078125,-200) [-200|301.99] "Deg" Vector__XXX

BO_ 2566886649 RQST_STR_S249_dall: 8 Vector__XXX
 SG_ Test_ID : 0|8@1- (1,0) [0|255] "" Vector__XXX

BO_ 2348810282 TSC1_s42_d0: 8 Vector__XXX
 SG_ EngOverrideCtrlMode : 0|2@1+ (1,0) [0|3] "" Vector__XXX
 SG_ EngRqedTorque_TorqueLimit : 24|8@1+ (1,-125) [-125|125] "%" Vector__XXX
 SG_ EngRqedSpeed_SpeedLimit : 8|16@1+ (0.125,0) [0|8031.875] "rpm" Vector__XXX
 SG_ OverrideCtrlModePriority : 4|2@1+ (1,0) [0|3] "" Vector__XXX

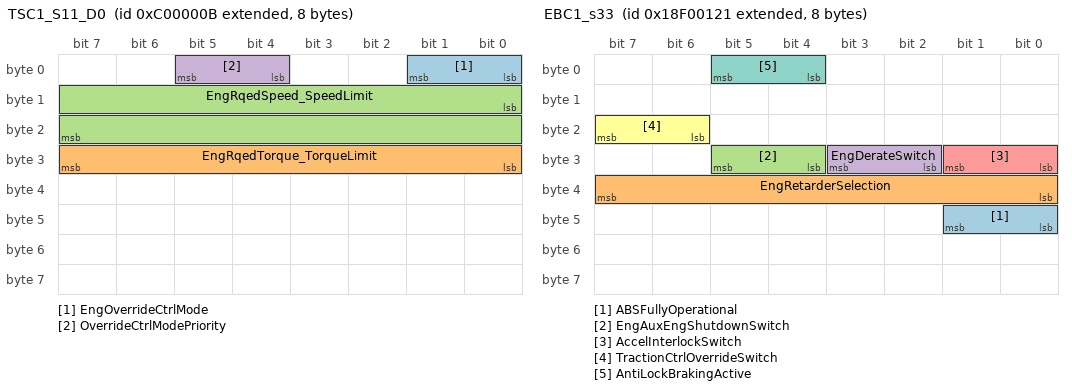
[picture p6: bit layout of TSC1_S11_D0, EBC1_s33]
BO_ 2348810251 TSC1_S11_D0: 8 Vector__XXX
 SG_ EngOverrideCtrlMode : 0|2@1+ (1,0) [0|3] "" Vector__XXX
 SG_ EngRqedTorque_TorqueLimit : 24|8@1+ (1,-125) [-125|125] "%" Vector__XXX
 SG_ EngRqedSpeed_SpeedLimit : 8|16@1+ (0.125,0) [0|8031.875] "rpm" Vector__XXX
 SG_ OverrideCtrlModePriority : 4|2@1+ (1,0) [0|3] "" Vector__XXX

BO_ 2565603105 TPDT_s33: 8 Vector__XXX
 SG_ SequenceNumber : 0|8@1+ (1,0) [0|252] "" Vector__XXX

BO_ 2565668641 TPCM_s33_dall: 8 Vector__XXX
 SG_ TotalNumberOfPacketsEoMA m19 : 24|8@1+ (1,0) [0|255] "" Vector__XXX
 SG_ TotalMessageSizeEoMA m19 : 8|16@1+ (1,0) [0|64255] "counts" Vector__XXX
 SG_ TotalMessageSizeBAM m32 : 8|16@1+ (1,0) [0|64255] "counts" Vector__XXX
 SG_ TotalNumberOfPacketsBAM m32 : 24|8@1+ (1,0) [0|255] "" Vector__XXX
 SG_ ConnectionAbortReason m255 : 8|8@1+ (1,0) [0|255] "" Vector__XXX
 SG_ NextPacketNumberToBeSent m17 : 16|8@1+ (1,0) [0|255] "" Vector__XXX
 SG_ NumberOfPacketsThatCanBeSent m17 : 8|8@1+ (1,0) [0|255] "" Vector__XXX
 SG_ PGNumber : 40|24@1+ (1,0) [0|16777200] "" Vector__XXX
 SG_ MaximumNumberOfPackets m16 : 32|8@1+ (1,0) [0|255] "" Vector__XXX
 SG_ TotalNumberOfPackets m16 : 24|8@1+ (1,0) [0|255] "" Vector__XXX
 SG_ TotalMessageSize m16 : 8|16@1+ (1,0) [0|64255] "counts" Vector__XXX
 SG_ ControlByte M : 0|8@1+ (1,0) [0|255] "" Vector__XXX

BO_ 2565611799 TPCM_s23_d33: 8 Vector__XXX
 SG_ TotalNumberOfPacketsEoMA m19 : 24|8@1+ (1,0) [0|255] "" Vector__XXX
 SG_ TotalMessageSizeEoMA m19 : 8|16@1+ (1,0) [0|64255] "counts" Vector__XXX
 SG_ TotalMessageSizeBAM m32 : 8|16@1+ (1,0) [0|64255] "counts" Vector__XXX
 SG_ TotalNumberOfPacketsBAM m32 : 24|8@1+ (1,0) [0|255] "" Vector__XXX
 SG_ ConnectionAbortReason m255 : 8|8@1+ (1,0) [0|255] "" Vector__XXX
 SG_ NextPacketNumberToBeSent m17 : 16|8@1+ (1,0) [0|255] "" Vector__XXX
 SG_ NumberOfPacketsThatCanBeSent m17 : 8|8@1+ (1,0) [0|255] "" Vector__XXX
 SG_ PGNumber : 40|24@1+ (1,0) [0|16777200] "" Vector__XXX
 SG_ MaximumNumberOfPackets m16 : 32|8@1+ (1,0) [0|255] "" Vector__XXX
 SG_ TotalNumberOfPackets m16 : 24|8@1+ (1,0) [0|255] "" Vector__XXX
 SG_ TotalMessageSize m16 : 8|16@1+ (1,0) [0|64255] "counts" Vector__XXX
 SG_ ControlByte M : 0|8@1+ (1,0) [0|255] "" Vector__XXX

BO_ 2565603351 TPCM_s23_d0: 8 Vector__XXX
 SG_ TotalNumberOfPacketsEoMA m19 : 24|8@1+ (1,0) [0|255] "" Vector__XXX
 SG_ TotalMessageSizeEoMA m19 : 8|16@1+ (1,0) [0|64255] "counts" Vector__XXX
 SG_ TotalMessageSizeBAM m32 : 8|16@1+ (1,0) [0|64255] "counts" Vector__XXX
 SG_ TotalNumberOfPacketsBAM m32 : 24|8@1+ (1,0) [0|255] "" Vector__XXX
 SG_ ConnectionAbortReason m255 : 8|8@1+ (1,0) [0|255] "" Vector__XXX
 SG_ NextPacketNumberToBeSent m17 : 16|8@1+ (1,0) [0|255] "" Vector__XXX
 SG_ NumberOfPacketsThatCanBeSent m17 : 8|8@1+ (1,0) [0|255] "" Vector__XXX
 SG_ PGNumber : 40|24@1+ (1,0) [0|16777200] "" Vector__XXX
 SG_ MaximumNumberOfPackets m16 : 32|8@1+ (1,0) [0|255] "" Vector__XXX
 SG_ TotalNumberOfPackets m16 : 24|8@1+ (1,0) [0|255] "" Vector__XXX
 SG_ TotalMessageSize m16 : 8|16@1+ (1,0) [0|64255] "counts" Vector__XXX
 SG_ ControlByte M : 0|8@1+ (1,0) [0|255] "" Vector__XXX

BO_ 2565668631 TPCM_s23: 8 Vector__XXX
 SG_ TotalNumberOfPacketsEoMA m19 : 24|8@1+ (1,0) [0|255] "" Vector__XXX
 SG_ TotalMessageSizeEoMA m19 : 8|16@1+ (1,0) [0|64255] "counts" Vector__XXX
 SG_ TotalMessageSizeBAM m32 : 8|16@1+ (1,0) [0|64255] "counts" Vector__XXX
 SG_ TotalNumberOfPacketsBAM m32 : 24|8@1+ (1,0) [0|255] "" Vector__XXX
 SG_ ConnectionAbortReason m255 : 8|8@1+ (1,0) [0|255] "" Vector__XXX
 SG_ NextPacketNumberToBeSent m17 : 16|8@1+ (1,0) [0|255] "" Vector__XXX
 SG_ NumberOfPacketsThatCanBeSent m17 : 8|8@1+ (1,0) [0|255] "" Vector__XXX
 SG_ PGNumber : 40|24@1+ (1,0) [0|16777200] "" Vector__XXX
 SG_ MaximumNumberOfPackets m16 : 32|8@1+ (1,0) [0|255] "" Vector__XXX
 SG_ TotalNumberOfPackets m16 : 24|8@1+ (1,0) [0|255] "" Vector__XXX
 SG_ TotalMessageSize m16 : 8|16@1+ (1,0) [0|64255] "counts" Vector__XXX
 SG_ ControlByte M : 0|8@1+ (1,0) [0|255] "" Vector__XXX

BO_ 2565479447 RQST_d28: 3 Vector__XXX
 SG_ ParameterGroupNumber : 0|24@1+ (1,0) [0|16777215] "" Vector__XXX

BO_ 2566841600 HOURS: 8 Vector__XXX
 SG_ EngTotalRevolutions : 32|32@1+ (1000,0) [0|4.211081215E+012] "r" Vector__XXX
 SG_ EngTotalHoursOfOperation : 0|32@1+ (0.05,0) [0|210554060.75] "hr" Vector__XXX

BO_ 2565865761 EBC1_s33: 8 Vector__XXX
 SG_ ABSFullyOperational : 40|2@1+ (1,0) [0|3] "" Vector__XXX
 SG_ EngRetarderSelection : 32|8@1+ (0.4,0) [0|100] "%" Vector__XXX
 SG_ EngAuxEngShutdownSwitch : 28|2@1+ (1,0) [0|3] "" Vector__XXX
 SG_ EngDerateSwitch : 26|2@1+ (1,0) [0|3] "" Vector__XXX
 SG_ AccelInterlockSwitch : 24|2@1+ (1,0) [0|3] "" Vector__XXX
 SG_ TractionCtrlOverrideSwitch : 22|2@1+ (1,0) [0|3] "" Vector__XXX
 SG_ AntiLockBrakingActive : 4|2@1+ (1,0) [0|3] "" Vector__XXX

BO_ 2566834977 DM2_s33: 22 Vector__XXX
 SG_ FailureModeIdentifier5 : 160|5@1+ (1,0) [0|0] "" Vector__XXX
 SG_ FailureModeIdentifier4 : 128|5@1+ (1,0) [0|0] "" Vector__XXX
 SG_ FailureModeIdentifier3 : 96|5@1+ (1,0) [0|0] "" Vector__XXX
 SG_ FailureModeIdentifier2 : 64|5@1+ (1,0) [0|0] "" Vector__XXX
 SG_ FailureModeIdentifier1 : 32|5@1+ (1,0) [0|0] "" Vector__XXX
 SG_ FlashRedStopLamp : 12|2@1+ (1,0) [0|3] "" Vector__XXX
 SG_ FlashProtectLamp : 8|2@1+ (1,0) [0|3] "" Vector__XXX
 SG_ FlashMalfuncIndicatorLamp : 14|2@1+ (1,0) [0|3] "" Vector__XXX
 SG_ FlashAmberWarningLamp : 10|2@1+ (1,0) [0|3] "" Vector__XXX
 SG_ SPN5 : 144|16@1+ (1,0) [0|65536] "" Vector__XXX
 SG_ SPN4 : 112|16@1+ (1,0) [0|65536] "" Vector__XXX
 SG_ SPN3 : 80|16@1+ (1,0) [0|65536] "" Vector__XXX
 SG_ SPN2 : 48|16@1+ (1,0) [0|65536] "" Vector__XXX
 SG_ SPN1 : 16|16@1+ (1,0) [0|65536] "" Vector__XXX
 SG_ RedStopLampStatus : 4|2@1+ (1,0) [0|3] "" Vector__XXX
 SG_ ProtectLampStatus : 0|2@1+ (1,0) [0|3] "" Vector__XXX
 SG_ AmberWarningLampStatus : 2|2@1+ (1,0) [0|3] "" Vector__XXX
 SG_ MalfunctionIndicatorLampStatus : 6|2@1+ (1,0) [0|3] "" Vector__XXX
 SG_ OccurenceCount1 : 40|7@1+ (1,0) [0|126] "" Vector__XXX
 SG_ SPNConversionMethod1 : 47|1@1+ (1,0) [0|1] "" Vector__XXX
 SG_ SPNConversionMethod5 : 175|1@1+ (1,0) [0|1] "" Vector__XXX
 SG_ SPNConversionMethod4 : 143|1@1+ (1,0) [0|1] "" Vector__XXX
 SG_ SPNConversionMethod3 : 111|1@1+ (1,0) [0|1] "" Vector__XXX
 SG_ SPNConversionMethod2 : 79|1@1+ (1,0) [0|1] "" Vector__XXX
 SG_ OccurenceCount5 : 168|7@1+ (1,0) [0|126] "" Vector__XXX
 SG_ OccurenceCount4 : 136|7@1+ (1,0) [0|126] "" Vector__XXX
 SG_ OccurenceCount3 : 104|7@1+ (1,0) [0|126] "" Vector__XXX
 SG_ OccurenceCount2 : 72|7@1+ (1,0) [0|126] "" Vector__XXX
 SG_ SPN5High : 165|3@1+ (1,0) [0|7] "" Vector__XXX
 SG_ SPN4High : 133|3@1+ (1,0) [0|7] "" Vector__XXX
 SG_ SPN3High : 101|3@1+ (1,0) [0|7] "" Vector__XXX
 SG_ SPN2High : 69|3@1+ (1,0) [0|7] "" Vector__XXX
 SG_ SPN1High : 37|3@1+ (1,0) [0|7] "" Vector__XXX

BO_ 2566834967 DM2_s23: 22 Vector__XXX
 SG_ FailureModeIdentifier5 : 160|5@1+ (1,0) [0|0] "" Vector__XXX
 SG_ FailureModeIdentifier4 : 128|5@1+ (1,0) [0|0] "" Vector__XXX
 SG_ FailureModeIdentifier3 : 96|5@1+ (1,0) [0|0] "" Vector__XXX
 SG_ FailureModeIdentifier2 : 64|5@1+ (1,0) [0|0] "" Vector__XXX
 SG_ FailureModeIdentifier1 : 32|5@1+ (1,0) [0|0] "" Vector__XXX
 SG_ FlashRedStopLamp : 12|2@1+ (1,0) [0|3] "" Vector__XXX
 SG_ FlashProtectLamp : 8|2@1+ (1,0) [0|3] "" Vector__XXX
 SG_ FlashMalfuncIndicatorLamp : 14|2@1+ (1,0) [0|3] "" Vector__XXX
 SG_ FlashAmberWarningLamp : 10|2@1+ (1,0) [0|3] "" Vector__XXX
 SG_ SPN5 : 144|16@1+ (1,0) [0|65536] "" Vector__XXX
 SG_ SPN4 : 112|16@1+ (1,0) [0|65536] "" Vector__XXX
 SG_ SPN3 : 80|16@1+ (1,0) [0|65536] "" Vector__XXX
 SG_ SPN2 : 48|16@1+ (1,0) [0|65536] "" Vector__XXX
 SG_ SPN1 : 16|16@1+ (1,0) [0|65536] "" Vector__XXX
 SG_ RedStopLampStatus : 4|2@1+ (1,0) [0|3] "" Vector__XXX
 SG_ ProtectLampStatus : 0|2@1+ (1,0) [0|3] "" Vector__XXX
 SG_ AmberWarningLampStatus : 2|2@1+ (1,0) [0|3] "" Vector__XXX
 SG_ MalfunctionIndicatorLampStatus : 6|2@1+ (1,0) [0|3] "" Vector__XXX
 SG_ OccurenceCount1 : 40|7@1+ (1,0) [0|126] "" Vector__XXX
 SG_ SPNConversionMethod1 : 47|1@1+ (1,0) [0|1] "" Vector__XXX
 SG_ SPNConversionMethod5 : 175|1@1+ (1,0) [0|1] "" Vector__XXX
 SG_ SPNConversionMethod4 : 143|1@1+ (1,0) [0|1] "" Vector__XXX
 SG_ SPNConversionMethod3 : 111|1@1+ (1,0) [0|1] "" Vector__XXX
 SG_ SPNConversionMethod2 : 79|1@1+ (1,0) [0|1] "" Vector__XXX
 SG_ OccurenceCount5 : 168|7@1+ (1,0) [0|126] "" Vector__XXX
 SG_ OccurenceCount4 : 136|7@1+ (1,0) [0|126] "" Vector__XXX
 SG_ OccurenceCount3 : 104|7@1+ (1,0) [0|126] "" Vector__XXX
 SG_ OccurenceCount2 : 72|7@1+ (1,0) [0|126] "" Vector__XXX
 SG_ SPN5High : 165|3@1+ (1,0) [0|7] "" Vector__XXX
 SG_ SPN4High : 133|3@1+ (1,0) [0|7] "" Vector__XXX
 SG_ SPN3High : 101|3@1+ (1,0) [0|7] "" Vector__XXX
 SG_ SPN2High : 69|3@1+ (1,0) [0|7] "" Vector__XXX
 SG_ SPN1High : 37|3@1+ (1,0) [0|7] "" Vector__XXX

BO_ 2566834721 DM1_s33: 22 Vector__XXX
 SG_ FailureModeIdentifier5 : 160|5@1+ (1,0) [0|0] "" Vector__XXX
 SG_ FailureModeIdentifier4 : 128|5@1+ (1,0) [0|0] "" Vector__XXX
 SG_ FailureModeIdentifier3 : 96|5@1+ (1,0) [0|0] "" Vector__XXX
 SG_ FailureModeIdentifier2 : 64|5@1+ (1,0) [0|0] "" Vector__XXX
 SG_ FailureModeIdentifier1 : 32|5@1+ (1,0) [0|0] "" Vector__XXX
 SG_ SPN5 : 144|16@1+ (1,0) [0|65536] "" Vector__XXX
 SG_ SPN4 : 112|16@1+ (1,0) [0|65536] "" Vector__XXX
 SG_ SPN3 : 80|16@1+ (1,0) [0|65536] "" Vector__XXX
 SG_ SPN2 : 48|16@1+ (1,0) [0|65536] "" Vector__XXX
 SG_ SPN1 : 16|16@1+ (1,0) [0|65536] "" Vector__XXX
 SG_ RedStopLampStatus : 4|2@1+ (1,0) [0|3] "" Vector__XXX
 SG_ ProtectLampStatus : 0|2@1+ (1,0) [0|3] "" Vector__XXX
 SG_ AmberWarningLampStatus : 2|2@1+ (1,0) [0|3] "" Vector__XXX
 SG_ MalfunctionIndicatorLampStatus : 6|2@1+ (1,0) [0|3] "" Vector__XXX
 SG_ FlashRedStopLamp : 12|2@1+ (1,0) [0|3] "" Vector__XXX
 SG_ FlashProtectLamp : 8|2@1+ (1,0) [0|3] "" Vector__XXX
 SG_ FlashMalfuncIndicatorLamp : 14|2@1+ (1,0) [0|3] "" Vector__XXX
 SG_ FlashAmberWarningLamp : 10|2@1+ (1,0) [0|3] "" Vector__XXX
 SG_ OccurenceCount1 : 40|7@1+ (1,0) [0|126] "" Vector__XXX
 SG_ SPNConversionMethod1 : 47|1@1+ (1,0) [0|1] "" Vector__XXX
 SG_ SPNConversionMethod5 : 175|1@1+ (1,0) [0|1] "" Vector__XXX
 SG_ SPNConversionMethod4 : 143|1@1+ (1,0) [0|1] "" Vector__XXX
 SG_ SPNConversionMethod3 : 111|1@1+ (1,0) [0|1] "" Vector__XXX
 SG_ SPNConversionMethod2 : 79|1@1+ (1,0) [0|1] "" Vector__XXX
 SG_ OccurenceCount5 : 168|7@1+ (1,0) [0|126] "" Vector__XXX
 SG_ OccurenceCount4 : 136|7@1+ (1,0) [0|126] "" Vector__XXX
 SG_ OccurenceCount3 : 104|7@1+ (1,0) [0|126] "" Vector__XXX
 SG_ OccurenceCount2 : 72|7@1+ (1,0) [0|126] "" Vector__XXX
 SG_ SPN5High : 165|3@1+ (1,0) [0|7] "" Vector__XXX
 SG_ SPN4High : 133|3@1+ (1,0) [0|7] "" Vector__XXX
 SG_ SPN3High : 101|3@1+ (1,0) [0|7] "" Vector__XXX
 SG_ SPN2High : 69|3@1+ (1,0) [0|7] "" Vector__XXX
 SG_ SPN1High : 37|3@1+ (1,0) [0|7] "" Vector__XXX

CM_ BO_ 2365440512 "Electronic Engine Controller 14";
CM_ BO_ 2560818944 "Regulated Exhaust Emission Level Exceedance";
CM_ SG_ 2560818944 DTC_Total_PrevActive_Time_5 "The number of hours the NOx malfunction has been confirmed and previously active.";
CM_ SG_ 2560818944 DTC_Total_Active_Time_5 "The total number of hours the DTCx has been confirmed and active.";
CM_ SG_ 2560818944 DTC_Time_Until_Derate_5 "The total number of hours the malfunction has until the OBD required derate will occur.";
CM_ SG_ 2560818944 DTC_Total_PrevActive_Time_4 "The number of hours the NOx malfunction has been confirmed and previously active.";
CM_ SG_ 2560818944 DTC_Total_Active_Time_4 "The total number of hours the DTCx has been confirmed and active.";
CM_ SG_ 2560818944 DTC_Time_Until_Derate_4 "The total number of hours the malfunction has until the OBD required derate will occur.";
CM_ SG_ 2560818944 DTC_Total_PrevActive_Time_3 "The number of hours the NOx malfunction has been confirmed and previously active.";
CM_ SG_ 2560818944 DTC_Total_Active_Time_3 "The total number of hours the DTCx has been confirmed and active.";
CM_ SG_ 2560818944 DTC_Time_Until_Derate_3 "The total number of hours the malfunction has until the OBD required derate will occur.";
CM_ SG_ 2560818944 DTC_Total_PrevActive_Time_2 "The number of hours the NOx malfunction has been confirmed and previously active.";
CM_ SG_ 2560818944 DTC_Total_Active_Time_2 "The total number of hours the DTCx has been confirmed and active.";
CM_ SG_ 2560818944 DTC_Time_Until_Derate_2 "The total number of hours the malfunction has until the OBD required derate will occur.";
CM_ SG_ 2560818944 DTC_Total_PrevActive_Time_1 "The number of hours the NOx malfunction has been confirmed and previously active.";
CM_ SG_ 2560818944 DTC_Total_Active_Time_1 "The total number of hours the DTCx has been confirmed and active.";
CM_ SG_ 2560818944 DTC_Time_Until_Derate_1 "The total number of hours the malfunction has until the OBD required derate will occur.";
CM_ SG_ 2560818944 SPN5 "SPN #5 (Conversion Version 4)";
CM_ SG_ 2560818944 SPN4 "SPN #4 (Conversion Version 4)";
CM_ SG_ 2560818944 SPN3 "SPN #3 (Conversion Version 4)";
CM_ SG_ 2560818944 SPN2 "SPN #2 (Conversion Version 4)";
CM_ SG_ 2560818944 FailureModeIdentifier1 "The FMI defines the type of failure detected in the subsystem identified by an SPN.";
CM_ SG_ 2560818944 SPN1 "SPN #1 (Conversion Version 4)";
CM_ SG_ 2560818944 FailureModeIdentifier2 "The FMI defines the type of failure detected in the subsystem identified by an SPN.";
CM_ SG_ 2560818944 SPN5High "SPN #5 (Conversion Version 4)";
CM_ SG_ 2560818944 SPN4High "SPN #4 (Conversion Version 4)";
CM_ SG_ 2560818944 SPN3High "SPN #3 (Conversion Version 4)";
CM_ SG_ 2560818944 SPN2High "SPN #2 (Conversion Version 4)";
CM_ SG_ 2560818944 SPN1High "SPN #1 (Conversion Version 4)";
CM_ BO_ 2633926400 "Ignition Timing 6";
CM_ SG_ 2633926400 EngActualIgnTiming "The actual ignition timing at the current engine conditions.";
CM_ BO_ 2365484270 "
";
CM_ SG_ 2365484270 TachographVehicleSpeed "Speed of the vehicle as registered by the tachograph.";
CM_ BO_ 2566892544 "Event Data Recorder 4";
CM_ BO_ 2566892288 "Event Data Recorder 3";
CM_ BO_ 2566892032 "Event Data Recorder 2";
CM_ BO_ 2566891776 "Event Data Recorder 1";
CM_ BO_ 2566831399 "Fan Drive
";
CM_ SG_ 2566831399 FanSpeed_Rx "The speed of the fan associated with engine coolant system.";
CM_ BO_ 2348814091 "Torque/Speed Control 1
added the message newly to include the sa and da in the db version 2";
CM_ SG_ 2348814091 EngRqedTorque_TorqueLimit "Parameter provided to the engine or retarder in the torque/speed control message for controlling or limiting the output torque.";
CM_ SG_ 2348814091 EngRqedSpeed_SpeedLimit "Parameter provided to the engine from external sources in the torque/speed control message.";
CM_ BO_ 2348814083 "Torque/Speed Control 1";
CM_ SG_ 2348814083 EngRqedTorque_TorqueLimit "Parameter provided to the engine or retarder in the torque/speed control message for controlling or limiting the output torque.";
CM_ SG_ 2348814083 EngRqedSpeed_SpeedLimit "Parameter provided to the engine from external sources in the torque/speed control message.";
CM_ BO_ 2566820864 "Engine Auxiliary Coolant";
CM_ SG_ 2566820864 EngExRangeCoolantPres "Engine extended range coolant pressure.";
CM_ BO_ 2566804992 "Electronic Engine Controller 1";
CM_ SG_ 2566804992 AftertreatmentPIMCtalystTnkLvl "SPN 1761 Aftertreatment 1 SCR Catalyst Tank Level A special catalyst uses a chemical reagent to reach legal requirement for NOX emissions. This parameter indicates the
level within the catalyst tank.

0 % = Empty
100% = Full";
CM_ BO_ 2564816899 "Cab Message 1";
CM_ BO_ 2633974265 "Proprietary reset message - sent when needed.";
CM_ BO_ 2364539392 "Electronic Transmission Controller 1";
CM_ SG_ 2364539392 TransOutputShaftSpeed_Tx "Calculated speed of the transmission output shaft.";
CM_ BO_ 2348814122 "Torque/Speed Control 1
added the message with a new sa/da in the db version2";
CM_ SG_ 2348814122 EngRqedTorque_TorqueLimit "Parameter provided to the engine or retarder in the torque/speed control message for controlling or limiting the output torque.";
CM_ SG_ 2348814122 EngRqedSpeed_SpeedLimit "Parameter provided to the engine from external sources in the torque/speed control message.";
CM_ BO_ 2566803754 "The operator requested characteristics for the ACC systems operation.
";
CM_ SG_ 2566803754 ReqACCDistMode "The Requested Distance Control Mode to the ACC system from the operators interface.";
CM_ BO_ 2564882176 "Cab Message 1";
CM_ BO_ 2631859961 "Reset sent by service tool";
CM_ SG_ 2631859961 EST_Trip_Reset "Command signal used to reset proprietary parameters associated with a trip but not defined within J1939-71.
";
CM_ BO_ 2561081377 "Auxiliary Input/Output Status 1
";
CM_ SG_ 2561081377 GovSelSwitch "SPN 3841: Auxiliary I/O channel being used for governor selection switch.
";
CM_ SG_ 2561081377 DataLogSwitch "SPN 3840: Auxiliary I/O channel being used for data logger switch.
";
CM_ BO_ 2566844683 "Cruise Control/Vehicle Speed
";
CM_ SG_ 2566844683 WheelBasedVehicleSpeed "Speed of the vehicle as calculated from wheel or tailshaft speed.";
CM_ BO_ 2566844714 "Cruise Control/Vehicle Speed";
CM_ SG_ 2566844714 CruiseCtrlResumeSwitch "Switch signal of the cruise control activator which indicates that the activator is in the position “resume.";
CM_ SG_ 2566844714 CruiseCtrlPauseSwitch "Switch signal which indicates the position of the Cruise Control Pause Switch used on Remote Cruise Control applications.";
CM_ SG_ 2566847009 Brake_Primary_Pressure "Gage pressure in primary side of air brake system.";
CM_ BO_ 2566868992 "Proprietary operator notification message
";
CM_ BO_ 2432498944 "Engine Related Parameters 
";
CM_ SG_ 2432498944 EngCmdFuelRailPress "Provides the commanded set point value for the engine fuel rail pressure.";
CM_ BO_ 2565865470 "Proprietary mode message
";
CM_ SG_ 2565865470 OpModeReq "Requested operating mode.";
CM_ BO_ 2565865216 "Proprietary mode message
";
CM_ SG_ 2565865216 OpModeCur "Current operating mode.";
CM_ SG_ 2633936896 TripEngRunTime "Total time accumulated while the engine speed is greater than zero since the last trip reset.";
CM_ SG_ 2633936896 TripIdleTime "Total idle time accumulated since the last trip reset.";
CM_ BO_ 2633939200 "Trip Fuel Information (Liquid)";
CM_ SG_ 2633939200 TripPTOStaFuelUsed "Total fuel consumed since the last trip reset with PTO active and vehicle stationary.";
CM_ SG_ 2633939200 TripPTOMovingFuelUsed "Total fuel consumed since the last trip reset with PTO active and vehicle moving.";
CM_ SG_ 2633939200 TripIdleFuelUsed "Total idle fuel consumed since the last trip reset.";
CM_ BO_ 2432520704 "Transmit status information from the Master ECU to an electronic thermostat";
CM_ SG_ 2432520704 EngAuxCoolerSupValve2 "Engine auxiliary cooler supply valve 2 control command";
CM_ SG_ 2432520704 EngAuxCoolerSupValve1 "Engine auxiliary cooler supply valve 1 control command";
CM_ BO_ 2432492288 "Engine Exhaust Brake Control";
CM_ SG_ 2432492288 EngineExhBrakeActCmd "Exhaust brake actuator control command";
CM_ SG_ 2432492288 EngineTC2TurbOutPress "Gage pressure at the turbine 2 outlet";
CM_ SG_ 2432492288 EngineTC2DesTurbOutPress "Desired gage pressure at the turbine 2 outlet";
CM_ SG_ 2432492288 EngineTC1TurbOutPress "Gage pressure at the turbine 1 outlet";
CM_ SG_ 2432492288 EngineTC1DesTurbOutPress "Desired gage pressure at the turbine 1 outlet";
CM_ BO_ 2633927680 "Auxiliary Analog Information";
CM_ SG_ 2633927680 Relative_Humidity "Measures humidity of combustion air prior to entry into turbocharger.";
CM_ BO_ 2566861857 "Engine Warmup Enable
Proprietary message from dash controller; only specified in DRD
";
CM_ SG_ 2566861857 EngineWarmupEnable "Engine warmup enable.";
CM_ BO_ 2566848256 "Water in Fuel Indicator
";
CM_ BO_ 2565865728 "Electronic Brake Controller 1";
CM_ SG_ 2565865728 EngAuxEngShutdownSwitch "Switch signal which requests that all engine fueling stop.";
CM_ SG_ 2565865728 EngDerateSwitch "Switch signal used to activate the torque limiting feature of the engine.";
CM_ SG_ 2565865728 AntiLockBrakingActive "State signal which indicates that the ABS is active.";
CM_ BO_ 2566854656 "Actual engine torque proprietary message used for emssions testing";
CM_ BO_ 2432593664 "Adaptive Cruise Control";
CM_ SG_ 2432593664 RoadCurvature "Estimated value of the current road curvature for use by the adaptive cruise control system.";
CM_ SG_ 2432593664 AdptveCruiseCtrlSetDistanceMode "Selected distance mode for adaptive cruise control.";
CM_ SG_ 2432593664 AdaptiveCruiseCtrlMode "This parameter is used to indicate the current state, or mode, of operation by the Adaptive Cruise Control (ACC) device.";
CM_ SG_ 2432593664 AdaptiveCruiseCtrlSetSpeed "Value of the desired (chosen) velocity of the adaptive cruise control system.";
CM_ SG_ 2432593664 DistanceToForwardVehicle "Distance to the preceding vehicle situated within 250 m in the same lane and moving in the same direction.";
CM_ SG_ 2432593664 SpeedOfForwardVehicle "Absolute velocity of the preceding vehicle situated within 250 m in the same lane and moving in the same direction.";
CM_ BO_ 2364539681 "Electronic Engine Controller 2";
CM_ BO_ 2565865475 "Electronic Retarder Controller 1";
CM_ SG_ 2565865475 RetarderTorqueMode "State signal which indicates which retarder torque mode is currently generating,limiting or controlling the torque.
New message added the db ver1";
CM_ SG_ 2565865475 RetarderEnableShiftAssistSwitch "Newly added to the db ver1
";
CM_ SG_ 2565865475 RetarderEnableBrakeAssistSwitch "00 Retarder Brake Assist Disabled
01 Retarder Brake Assist Enabled
10 Error
11 Not Available.";
CM_ SG_ 2565865475 ActualRetarderPercentTorque "Actual braking torque of the retarder as a percent of retarder configuration reference torque SPN 556.";
CM_ BO_ 2566844416 "Power Takeoff Information";
CM_ SG_ 2566844416 PowerTakeoffSetSpeed "Rotational Velocity selected by operator for device used to transmit engine power to auxillary equipment.
Newly added to the db version1";
CM_ SG_ 2566844416 EngPTOAccelerateSwitch "Switch signal of the PTO control activator which indicates that the activator is in the position \"accelerate\".";
CM_ SG_ 2566844416 EngPTOResumeSwitch "Switch signal of the PTO control activator which indicates that the activator is in the position \"resume\".";
CM_ SG_ 2566844416 EngPTOCoast_DecelerateSwitch "Switch signal of the PTO control activator which indicates that the activator is in the position \"coast/decelerate\".";
CM_ SG_ 2566844416 EngPTOSetSwitch "Switch signal of the PTO control activator which indicates that the activator is in the position \"set\".";
CM_ SG_ 2566844416 EngRmtPTOVriableSpeedCtrlSwitch "Switch signal which indicates that the remote PTO toggle switch is in the enabled (ON) position.";
CM_ SG_ 2566844416 EngRmtPTOPrprgrmmdSpdCtrlSwitch "Switch signal which indicates that the remote PTO toggle switch is in the enabled (ON) position.";
CM_ SG_ 2566844416 RmtPTOPrprgrmmdSpeedCtrlSwitch2 "Switch signal which indicates that the remote PTO toggle switch #2 is in the enabled (ON) position.";
CM_ BO_ 2633935104 "Exhaust Oxygen 1
";
CM_ SG_ 2633935104 DesiredExhaustO2 "Engine Desired Exhaust Oxygen
";
CM_ BO_ 2566743296 "Aftertreatment 1 Fuel Control 2
";
CM_ SG_ 2566743296 AT1HCDoserInFuelTemp "Measured temperature of the intake fuel to the hydrocarbon dosing device.";
CM_ SG_ 2566743296 Aftertreatment1FuelPress2 "Aftertreatment 1 Fuel Pressure 2";
CM_ BO_ 2566725632 "Aftertreatment 1 Diesel Oxidation Catalyst";
CM_ SG_ 2566725632 Aftertreatment1DOCOutTemp "Aftertreatment 1 Diesel Oxidation Catalyst Outlet Gas Temperature";
CM_ SG_ 2566725632 Aftertreatment1DOCInTemp "Aftertreatment 1 Diesel Oxidation Catalyst Intake Gas Temperature
";
CM_ BO_ 2633925376 "Ignition Timing 2
added to the db version6";
CM_ SG_ 2633925376 EngCylinderIgnTiming6 "newly added to the db6";
CM_ SG_ 2633925376 EngCylinderIgnTiming5 "newly added to the db6";
CM_ BO_ 2633925120 "Ignition Timing 1
added to the db version6";
CM_ SG_ 2633925120 EngCylinderIgnTiming4 "newly added to the db6";
CM_ SG_ 2633925120 EngCylinderIgnTiming3 "newly added to the db6";
CM_ SG_ 2633925120 EngCylinderIgnTiming2 "newly added to the db6";
CM_ SG_ 2633925120 EngCylinderIgnTiming1 "newly added to the db6";
CM_ BO_ 2566886649 "

Added newly to the db vers3 to accomodate the service test results.
Corrected the number from 65248 to 65428 in db ver4";
CM_ BO_ 2348810282 "Torque/Speed Control 1
added the message with a new sa/da in the db version2";
CM_ SG_ 2348810282 EngRqedTorque_TorqueLimit "Parameter provided to the engine or retarder in the torque/speed control message for controlling or limiting the output torque.";
CM_ SG_ 2348810282 EngRqedSpeed_SpeedLimit "Parameter provided to the engine from external sources in the torque/speed control message.";
CM_ BO_ 2348810251 "Torque/Speed Control 1
added the message newly to include the sa and da in the db version 2";
CM_ SG_ 2348810251 EngRqedTorque_TorqueLimit "Parameter provided to the engine or retarder in the torque/speed control message for controlling or limiting the output torque.";
CM_ SG_ 2348810251 EngRqedSpeed_SpeedLimit "Parameter provided to the engine from external sources in the torque/speed control message.";
CM_ BO_ 2565603105 "Transport Protocol - Data Transfer
added the message with the new sa/da in the db ver2";
CM_ BO_ 2565668641 "Transport Protocol - Connection Management
added the tpcm message with a new sa/da in the db ver2";
CM_ SG_ 2565668641 TotalNumberOfPacketsEoMA "Total number of packets for BAM message.Total number of packets received for RTS/CTS message.Total number of packets for RTS/CTS message.";
CM_ SG_ 2565668641 TotalMessageSizeEoMA "Total message size (in bytes) for BAM message.Total message size (in bytes) for RTS/CTS message.Total message size (in bytes) for RTS/CTS message.";
CM_ SG_ 2565668641 TotalMessageSizeBAM "Total message size (in bytes) for BAM message.Total message size (in bytes) for RTS/CTS message.Total message size (in bytes) for RTS/CTS message.";
CM_ SG_ 2565668641 TotalNumberOfPacketsBAM "Total number of packets for BAM message.Total number of packets received for RTS/CTS message.Total number of packets for RTS/CTS message.";
CM_ SG_ 2565668641 ConnectionAbortReason "Reason for connection abort message.";
CM_ SG_ 2565668641 NextPacketNumberToBeSent "Next Packet Number to be sent (TP.CM_CTS)";
CM_ SG_ 2565668641 NumberOfPacketsThatCanBeSent "Number of Packets that can be sent (TP.CM_CTS)";
CM_ SG_ 2565668641 MaximumNumberOfPackets "Maximum number of packets for RTS/CTS message.";
CM_ SG_ 2565668641 TotalNumberOfPackets "Total number of packets for BAM message.Total number of packets received for RTS/CTS message.Total number of packets for RTS/CTS message.";
CM_ SG_ 2565668641 TotalMessageSize "Total message size (in bytes) for BAM message.Total message size (in bytes) for RTS/CTS message.Total message size (in bytes) for RTS/CTS message.";
CM_ BO_ 2565611799 "Transport Protocol - Connection Management
added the tpcm message with a new sa/da in the db ver2";
CM_ SG_ 2565611799 TotalNumberOfPacketsEoMA "Total number of packets for BAM message.Total number of packets received for RTS/CTS message.Total number of packets for RTS/CTS message.";
CM_ SG_ 2565611799 TotalMessageSizeEoMA "Total message size (in bytes) for BAM message.Total message size (in bytes) for RTS/CTS message.Total message size (in bytes) for RTS/CTS message.";
CM_ SG_ 2565611799 TotalMessageSizeBAM "Total message size (in bytes) for BAM message.Total message size (in bytes) for RTS/CTS message.Total message size (in bytes) for RTS/CTS message.";
CM_ SG_ 2565611799 TotalNumberOfPacketsBAM "Total number of packets for BAM message.Total number of packets received for RTS/CTS message.Total number of packets for RTS/CTS message.";
CM_ SG_ 2565611799 ConnectionAbortReason "Reason for connection abort message.";
CM_ SG_ 2565611799 NextPacketNumberToBeSent "Next Packet Number to be sent (TP.CM_CTS)";
CM_ SG_ 2565611799 NumberOfPacketsThatCanBeSent "Number of Packets that can be sent (TP.CM_CTS)";
CM_ SG_ 2565611799 MaximumNumberOfPackets "Maximum number of packets for RTS/CTS message.";
CM_ SG_ 2565611799 TotalNumberOfPackets "Total number of packets for BAM message.Total number of packets received for RTS/CTS message.Total number of packets for RTS/CTS message.";
CM_ SG_ 2565611799 TotalMessageSize "Total message size (in bytes) for BAM message.Total message size (in bytes) for RTS/CTS message.Total message size (in bytes) for RTS/CTS message.";
CM_ BO_ 2565603351 "Transport Protocol - Connection Management
added the tpcm message with a new sa/da in the db ver2";
CM_ SG_ 2565603351 TotalNumberOfPacketsEoMA "Total number of packets for BAM message.Total number of packets received for RTS/CTS message.Total number of packets for RTS/CTS message.";
CM_ SG_ 2565603351 TotalMessageSizeEoMA "Total message size (in bytes) for BAM message.Total message size (in bytes) for RTS/CTS message.Total message size (in bytes) for RTS/CTS message.";
CM_ SG_ 2565603351 TotalMessageSizeBAM "Total message size (in bytes) for BAM message.Total message size (in bytes) for RTS/CTS message.Total message size (in bytes) for RTS/CTS message.";
CM_ SG_ 2565603351 TotalNumberOfPacketsBAM "Total number of packets for BAM message.Total number of packets received for RTS/CTS message.Total number of packets for RTS/CTS message.";
CM_ SG_ 2565603351 ConnectionAbortReason "Reason for connection abort message.";
CM_ SG_ 2565603351 NextPacketNumberToBeSent "Next Packet Number to be sent (TP.CM_CTS)";
CM_ SG_ 2565603351 NumberOfPacketsThatCanBeSent "Number of Packets that can be sent (TP.CM_CTS)";
CM_ SG_ 2565603351 MaximumNumberOfPackets "Maximum number of packets for RTS/CTS message.";
CM_ SG_ 2565603351 TotalNumberOfPackets "Total number of packets for BAM message.Total number of packets received for RTS/CTS message.Total number of packets for RTS/CTS message.";
CM_ SG_ 2565603351 TotalMessageSize "Total message size (in bytes) for BAM message.Total message size (in bytes) for RTS/CTS message.Total message size (in bytes) for RTS/CTS message.";
CM_ BO_ 2565668631 "Transport Protocol - Connection Management";
CM_ SG_ 2565668631 TotalNumberOfPacketsEoMA "Total number of packets for BAM message.Total number of packets received for RTS/CTS message.Total number of packets for RTS/CTS message.";
CM_ SG_ 2565668631 TotalMessageSizeEoMA "Total message size (in bytes) for BAM message.Total message size (in bytes) for RTS/CTS message.Total message size (in bytes) for RTS/CTS message.";
CM_ SG_ 2565668631 TotalMessageSizeBAM "Total message size (in bytes) for BAM message.Total message size (in bytes) for RTS/CTS message.Total message size (in bytes) for RTS/CTS message.";
CM_ SG_ 2565668631 TotalNumberOfPacketsBAM "Total number of packets for BAM message.Total number of packets received for RTS/CTS message.Total number of packets for RTS/CTS message.";
CM_ SG_ 2565668631 ConnectionAbortReason "Reason for connection abort message.";
CM_ SG_ 2565668631 NextPacketNumberToBeSent "Next Packet Number to be sent (TP.CM_CTS)";
CM_ SG_ 2565668631 NumberOfPacketsThatCanBeSent "Number of Packets that can be sent (TP.CM_CTS)";
CM_ SG_ 2565668631 MaximumNumberOfPackets "Maximum number of packets for RTS/CTS message.";
CM_ SG_ 2565668631 TotalNumberOfPackets "Total number of packets for BAM message.Total number of packets received for RTS/CTS message.Total number of packets for RTS/CTS message.";
CM_ SG_ 2565668631 TotalMessageSize "Total message size (in bytes) for BAM message.Total message size (in bytes) for RTS/CTS message.Total message size (in bytes) for RTS/CTS message.";
CM_ BO_ 2565479447 "Request
added the message to the db version2";
CM_ SG_ 2565479447 ParameterGroupNumber "PGN which is requested by RQST
changed the spn from 2547 to 2540 in db vers2
";
CM_ BO_ 2566841600 "Engine Hours, Revolutions
added the SA to the db version2";
CM_ SG_ 2566841600 EngTotalRevolutions "Accumulated number of revolutions of engine crankshaft during its operation.";
CM_ SG_ 2566841600 EngTotalHoursOfOperation "Accumulated time of operation of engine.";
CM_ BO_ 2565865761 "Electronic Brake Controller 1
added the pgn for a new SA in the db version2";
CM_ SG_ 2565865761 EngAuxEngShutdownSwitch "Switch signal which requests that all engine fueling stop.";
CM_ SG_ 2565865761 EngDerateSwitch "Switch signal used to activate the torque limiting feature of the engine.";
CM_ SG_ 2565865761 AccelInterlockSwitch "Switch signal used to disable the accelerator and remote accelerator inputs, causing the engine to return to idle.";
CM_ SG_ 2565865761 TractionCtrlOverrideSwitch "Switch signal which indicates the position of the traction control override switch.";
CM_ SG_ 2565865761 AntiLockBrakingActive "State signal which indicates that the ABS is active.";
CM_ BO_ 2566834977 "Previously active diagnostic trouble codes
added the message with a new SA in the db version2";
CM_ SG_ 2566834977 FailureModeIdentifier5 "The FMI defines the type of failure detected in the subsystem identified by an SPN.";
CM_ SG_ 2566834977 FailureModeIdentifier4 "The FMI defines the type of failure detected in the subsystem identified by an SPN.";
CM_ SG_ 2566834977 FailureModeIdentifier3 "The FMI defines the type of failure detected in the subsystem identified by an SPN.";
CM_ SG_ 2566834977 FailureModeIdentifier2 "The FMI defines the type of failure detected in the subsystem identified by an SPN.";
CM_ SG_ 2566834977 FailureModeIdentifier1 "The FMI defines the type of failure detected in the subsystem identified by an SPN.";
CM_ SG_ 2566834977 FlashRedStopLamp "This parameter provides the capability to flash the RSL (SPN 3039).";
CM_ SG_ 2566834977 FlashProtectLamp "This parameter provides the capability to flash the engine protect lamp (SPN 3041).";
CM_ SG_ 2566834977 FlashMalfuncIndicatorLamp "This parameter provides the capability to flash the MIL (SPN 3038).";
CM_ SG_ 2566834977 FlashAmberWarningLamp "This parameter provides the capability to flash the AWL (SPN 3040). ";
CM_ SG_ 2566834977 SPN5 "SPN #5 (Conversion Version 4)";
CM_ SG_ 2566834977 SPN4 "SPN #4 (Conversion Version 4)";
CM_ SG_ 2566834977 SPN3 "SPN #3 (Conversion Version 4)";
CM_ SG_ 2566834977 SPN2 "SPN #2 (Conversion Version 4)";
CM_ SG_ 2566834977 SPN1 "SPN #1 (Conversion Version 4)";
CM_ SG_ 2566834977 RedStopLampStatus "This lamp is uesed to relay trouble code information that is of a severe enought condition that it warrants stopping the vehicle.";
CM_ SG_ 2566834977 ProtectLampStatus "This lamp is used to relay trouble code informatio that is reporting a problem with a vehicle system that is most
probably not electronic subsystem related.";
CM_ SG_ 2566834977 AmberWarningLampStatus "This lamp is used to relay trouble code information that is reporting a problem with the vehicle system but the vehicle need
not be immediately stopped.";
CM_ SG_ 2566834977 MalfunctionIndicatorLampStatus "A lamp used to relay only emissions-related trouble code information.";
CM_ SG_ 2566834977 OccurenceCount1 "The 7 bit occurence count field contains the number of times a fault has gone from active to previously active.";
CM_ SG_ 2566834977 OccurenceCount5 "The 7 bit occurence count field contains the number of times a fault has gone from active to previously active.";
CM_ SG_ 2566834977 OccurenceCount4 "The 7 bit occurence count field contains the number of times a fault has gone from active to previously active.";
CM_ SG_ 2566834977 OccurenceCount3 "The 7 bit occurence count field contains the number of times a fault has gone from active to previously active.";
CM_ SG_ 2566834977 OccurenceCount2 "The 7 bit occurence count field contains the number of times a fault has gone from active to previously active.";
CM_ SG_ 2566834977 SPN5High "SPN #5 (Conversion Version 4)";
CM_ SG_ 2566834977 SPN4High "SPN #4 (Conversion Version 4)";
CM_ SG_ 2566834977 SPN3High "SPN #3 (Conversion Version 4)";
CM_ SG_ 2566834977 SPN2High "SPN #2 (Conversion Version 4)";
CM_ SG_ 2566834977 SPN1High "SPN #1 (Conversion Version 4)";
CM_ BO_ 2566834967 "Previously active diagnostic trouble codes
added the pgn with a new SA in the db ver2";
CM_ SG_ 2566834967 FailureModeIdentifier5 "The FMI defines the type of failure detected in the subsystem identified by an SPN.";
CM_ SG_ 2566834967 FailureModeIdentifier4 "The FMI defines the type of failure detected in the subsystem identified by an SPN.";
CM_ SG_ 2566834967 FailureModeIdentifier3 "The FMI defines the type of failure detected in the subsystem identified by an SPN.";
CM_ SG_ 2566834967 FailureModeIdentifier2 "The FMI defines the type of failure detected in the subsystem identified by an SPN.";
CM_ SG_ 2566834967 FailureModeIdentifier1 "The FMI defines the type of failure detected in the subsystem identified by an SPN.";
CM_ SG_ 2566834967 FlashRedStopLamp "This parameter provides the capability to flash the RSL (SPN 3039).";
CM_ SG_ 2566834967 FlashProtectLamp "This parameter provides the capability to flash the engine protect lamp (SPN 3041).";
CM_ SG_ 2566834967 FlashMalfuncIndicatorLamp "This parameter provides the capability to flash the MIL (SPN 3038).";
CM_ SG_ 2566834967 FlashAmberWarningLamp "This parameter provides the capability to flash the AWL (SPN 3040). ";
CM_ SG_ 2566834967 SPN5 "SPN #5 (Conversion Version 4)";
CM_ SG_ 2566834967 SPN4 "SPN #4 (Conversion Version 4)";
CM_ SG_ 2566834967 SPN3 "SPN #3 (Conversion Version 4)";
CM_ SG_ 2566834967 SPN2 "SPN #2 (Conversion Version 4)";
CM_ SG_ 2566834967 SPN1 "SPN #1 (Conversion Version 4)";
CM_ SG_ 2566834967 RedStopLampStatus "This lamp is uesed to relay trouble code information that is of a severe enought condition that it warrants stopping the vehicle.";
CM_ SG_ 2566834967 ProtectLampStatus "This lamp is used to relay trouble code informatio that is reporting a problem with a vehicle system that is most
probably not electronic subsystem related.";
CM_ SG_ 2566834967 AmberWarningLampStatus "This lamp is used to relay trouble code information that is reporting a problem with the vehicle system but the vehicle need
not be immediately stopped.";
CM_ SG_ 2566834967 MalfunctionIndicatorLampStatus "A lamp used to relay only emissions-related trouble code information.";
CM_ SG_ 2566834967 OccurenceCount1 "The 7 bit occurence count field contains the number of times a fault has gone from active to previously active.";
CM_ SG_ 2566834967 OccurenceCount5 "The 7 bit occurence count field contains the number of times a fault has gone from active to previously active.";
CM_ SG_ 2566834967 OccurenceCount4 "The 7 bit occurence count field contains the number of times a fault has gone from active to previously active.";
CM_ SG_ 2566834967 OccurenceCount3 "The 7 bit occurence count field contains the number of times a fault has gone from active to previously active.";
CM_ SG_ 2566834967 OccurenceCount2 "The 7 bit occurence count field contains the number of times a fault has gone from active to previously active.";
CM_ SG_ 2566834967 SPN5High "SPN #5 (Conversion Version 4)";
CM_ SG_ 2566834967 SPN4High "SPN #4 (Conversion Version 4)";
CM_ SG_ 2566834967 SPN3High "SPN #3 (Conversion Version 4)";
CM_ SG_ 2566834967 SPN2High "SPN #2 (Conversion Version 4)";
CM_ SG_ 2566834967 SPN1High "SPN #1 (Conversion Version 4)";
CM_ BO_ 2566834721 "Active diagnostic trouble codes";
CM_ SG_ 2566834721 FailureModeIdentifier5 "The FMI defines the type of failure detected in the subsystem identified by an SPN.";
CM_ SG_ 2566834721 FailureModeIdentifier4 "The FMI defines the type of failure detected in the subsystem identified by an SPN.";
CM_ SG_ 2566834721 FailureModeIdentifier3 "The FMI defines the type of failure detected in the subsystem identified by an SPN.";
CM_ SG_ 2566834721 FailureModeIdentifier2 "The FMI defines the type of failure detected in the subsystem identified by an SPN.";
CM_ SG_ 2566834721 FailureModeIdentifier1 "The FMI defines the type of failure detected in the subsystem identified by an SPN.";
CM_ SG_ 2566834721 SPN5 "SPN #5 (Conversion Version 4)";
CM_ SG_ 2566834721 SPN4 "SPN #4 (Conversion Version 4)";
CM_ SG_ 2566834721 SPN3 "SPN #3 (Conversion Version 4)";
CM_ SG_ 2566834721 SPN2 "SPN #2 (Conversion Version 4)";
CM_ SG_ 2566834721 SPN1 "SPN #1 (Conversion Version 4)";
CM_ SG_ 2566834721 RedStopLampStatus "This lamp is uesed to relay trouble code information that is of a severe enought condition that it warrants stopping the vehicle.";
CM_ SG_ 2566834721 ProtectLampStatus "This lamp is used to relay trouble code informatio that is reporting a problem with a vehicle system that is most
probably not electronic subsystem related.";
CM_ SG_ 2566834721 AmberWarningLampStatus "This lamp is used to relay trouble code information that is reporting a problem with the vehicle system but the vehicle need
not be immediately stopped.";
CM_ SG_ 2566834721 MalfunctionIndicatorLampStatus "A lamp used to relay only emissions-related trouble code information.";
CM_ SG_ 2566834721 FlashRedStopLamp "This parameter provides the capability to flash the RSL (SPN 3039).";
CM_ SG_ 2566834721 FlashProtectLamp "This parameter provides the capability to flash the engine protect lamp (SPN 3041).";
CM_ SG_ 2566834721 FlashMalfuncIndicatorLamp "This parameter provides the capability to flash the MIL (SPN 3038).";
CM_ SG_ 2566834721 FlashAmberWarningLamp "This parameter provides the capability to flash the AWL (SPN 3040). ";
CM_ SG_ 2566834721 OccurenceCount1 "The 7 bit occurence count field contains the number of times a fault has gone from active to previously active.";
CM_ SG_ 2566834721 OccurenceCount5 "The 7 bit occurence count field contains the number of times a fault has gone from active to previously active.";
CM_ SG_ 2566834721 OccurenceCount4 "The 7 bit occurence count field contains the number of times a fault has gone from active to previously active.";
CM_ SG_ 2566834721 OccurenceCount3 "The 7 bit occurence count field contains the number of times a fault has gone from active to previously active.";
CM_ SG_ 2566834721 OccurenceCount2 "The 7 bit occurence count field contains the number of times a fault has gone from active to previously active.";
CM_ SG_ 2566834721 SPN5High "SPN #5 (Conversion Version 4)";
CM_ SG_ 2566834721 SPN4High "SPN #4 (Conversion Version 4)";
CM_ SG_ 2566834721 SPN3High "SPN #3 (Conversion Version 4)";
CM_ SG_ 2566834721 SPN2High "SPN #2 (Conversion Version 4)";
CM_ SG_ 2566834721 SPN1High "SPN #1 (Conversion Version 4)";
BA_DEF_ SG_  "Status" STRING ;
BA_DEF_ SG_  "Variable" STRING ;
BA_DEF_ SG_  "SigType" STRING ;
BA_DEF_ SG_  "SPN" INT 0 524287;
BA_DEF_ SG_  "DDI" INT 0 65535;
BA_DEF_ SG_  "SAEDocument" STRING ;
BA_DEF_ BO_  "GenMsgRequestable" INT 0 1;
BA_DEF_ BO_  "GenMsgSendType" ENUM  "cyclic","reserved","cyclicIfActive","reserved","reserved","reserved","reserved","On Request","noMsgSendType";
BA_DEF_ BO_  "VFrameFormat" ENUM  "StandardCAN","ExtendedCAN","reserved","J1939PG";
BA_DEF_ BO_  "SingleFrame" INT 0 1;
BA_DEF_ BO_  "GenMsgCycleTime" INT 0 3600000;
BA_DEF_ BO_  "SAE_Document" STRING ;
BA_DEF_ BU_  "NmStationAddress" INT 0 255;
BA_DEF_  "DatabaseVersion" STRING ;
BA_DEF_  "BusType" STRING ;
BA_DEF_  "SAE_J1939-75_SpecVersion" STRING ;
BA_DEF_  "SAE_J1939-21_SpecVersion" STRING ;
BA_DEF_  "SAE_J1939-73_SpecVersion" STRING ;
BA_DEF_  "SAE_J1939-71_SpecVersion" STRING ;
BA_DEF_DEF_  "Status" "";
BA_DEF_DEF_  "Variable" "";
BA_DEF_DEF_  "SigType" "";
BA_DEF_DEF_  "SPN" 0;
BA_DEF_DEF_  "DDI" 0;
BA_DEF_DEF_  "SAEDocument" "";
BA_DEF_DEF_  "GenMsgRequestable" 1;
BA_DEF_DEF_  "GenMsgSendType" "noMsgSendType";
BA_DEF_DEF_  "VFrameFormat" "J1939PG";
BA_DEF_DEF_  "SingleFrame" 1;
BA_DEF_DEF_  "GenMsgCycleTime" 0;
BA_DEF_DEF_  "SAE_Document" "";
BA_DEF_DEF_  "NmStationAddress" 254;
BA_DEF_DEF_  "DatabaseVersion" "";
BA_DEF_DEF_  "BusType" "";
BA_DEF_DEF_  "SAE_J1939-75_SpecVersion" "";
BA_DEF_DEF_  "SAE_J1939-21_SpecVersion" "";
BA_DEF_DEF_  "SAE_J1939-73_SpecVersion" "";
BA_DEF_DEF_  "SAE_J1939-71_SpecVersion" "";
BA_ "DatabaseVersion" "5.2";
BA_ "BusType" "CAN";
BA_ "SAE_J1939-75_SpecVersion" "2005-01-21";
BA_ "SAE_J1939-21_SpecVersion" "2004-10-21";
BA_ "SAE_J1939-73_SpecVersion" "2004-09-17";
BA_ "SAE_J1939-71_SpecVersion" "2005-06-01";
BA_ "NmStationAddress" BU_ ECM 0;
BA_ "GenMsgSendType" BO_ 2365440512 7;
BA_ "SAE_Document" BO_ 2365440512 "J1939-71";
BA_ "SAE_Document" BO_ 2560818944 "J1939-73";
BA_ "GenMsgSendType" BO_ 2633926400 7;
BA_ "GenMsgSendType" BO_ 2365484270 0;
BA_ "GenMsgCycleTime" BO_ 2365484270 50;
BA_ "SAE_Document" BO_ 2365484270 "J1939-71";
BA_ "GenMsgSendType" BO_ 2566892544 7;
BA_ "GenMsgSendType" BO_ 2566892288 7;
BA_ "GenMsgSendType" BO_ 2566892032 7;
BA_ "GenMsgSendType" BO_ 2566891776 7;
BA_ "SAE_Document" BO_ 2566831399 "J1939-71";
BA_ "GenMsgCycleTime" BO_ 2566831399 1000;
BA_ "GenMsgSendType" BO_ 2566831399 0;
BA_ "SAE_Document" BO_ 2348814091 "J1939-71";
BA_ "SAE_Document" BO_ 2348814083 "J1939-71";
BA_ "SAE_Document" BO_ 2566820864 "J1939-71";
BA_ "GenMsgCycleTime" BO_ 2566820864 500;
BA_ "GenMsgSendType" BO_ 2566820864 0;
BA_ "GenMsgSendType" BO_ 2566804992 0;
BA_ "GenMsgCycleTime" BO_ 2566804992 1000;
BA_ "SAE_Document" BO_ 2566804992 "J1939-71";
BA_ "SAE_Document" BO_ 2564816899 "J1939-71";
BA_ "GenMsgCycleTime" BO_ 2564816899 1000;
BA_ "GenMsgSendType" BO_ 2564816899 0;
BA_ "SAE_Document" BO_ 2364539392 "J1939-71";
BA_ "GenMsgCycleTime" BO_ 2364539392 10;
BA_ "GenMsgSendType" BO_ 2364539392 0;
BA_ "SAE_Document" BO_ 2348814122 "J1939-71";
BA_ "GenMsgSendType" BO_ 2566803754 0;
BA_ "GenMsgCycleTime" BO_ 2566803754 250;
BA_ "SAE_Document" BO_ 2566803754 "J1939-71";
BA_ "GenMsgSendType" BO_ 2564882176 0;
BA_ "GenMsgCycleTime" BO_ 2564882176 1000;
BA_ "SAE_Document" BO_ 2564882176 "J1939-71";
BA_ "SAE_Document" BO_ 2631859961 "J1939-71";
BA_ "GenMsgSendType" BO_ 2561081377 0;
BA_ "GenMsgCycleTime" BO_ 2561081377 100;
BA_ "SAE_Document" BO_ 2561081377 "J1939-71";
BA_ "SAE_Document" BO_ 2566844683 "J1939-71";
BA_ "GenMsgCycleTime" BO_ 2566844683 100;
BA_ "GenMsgSendType" BO_ 2566844683 0;
BA_ "GenMsgSendType" BO_ 2566844714 0;
BA_ "GenMsgCycleTime" BO_ 2566844714 100;
BA_ "SAE_Document" BO_ 2566844714 "J1939-71";
BA_ "SAE_Document" BO_ 2566847009 "J1939-71";
BA_ "GenMsgCycleTime" BO_ 2566847009 1000;
BA_ "GenMsgSendType" BO_ 2566847009 0;
BA_ "GenMsgCycleTime" BO_ 2566868992 1000;
BA_ "GenMsgSendType" BO_ 2566868992 0;
BA_ "SAE_Document" BO_ 2432498944 "J1939-71";
BA_ "GenMsgCycleTime" BO_ 2432498944 100;
BA_ "GenMsgSendType" BO_ 2432498944 0;
BA_ "GenMsgCycleTime" BO_ 2565865470 50;
BA_ "GenMsgSendType" BO_ 2565865470 0;
BA_ "GenMsgCycleTime" BO_ 2565865216 50;
BA_ "GenMsgSendType" BO_ 2565865216 0;
BA_ "SAE_Document" BO_ 2633936896 "J1939-71";
BA_ "GenMsgSendType" BO_ 2633936896 7;
BA_ "SAE_Document" BO_ 2633939200 "J1939-71";
BA_ "GenMsgSendType" BO_ 2633939200 7;
BA_ "GenMsgSendType" BO_ 2432520704 0;
BA_ "GenMsgCycleTime" BO_ 2432520704 1000;
BA_ "SAE_Document" BO_ 2432520704 "J1939-71";
BA_ "GenMsgSendType" BO_ 2432492288 0;
BA_ "GenMsgCycleTime" BO_ 2432492288 100;
BA_ "SAE_Document" BO_ 2432492288 "J1939-71";
BA_ "GenMsgSendType" BO_ 2633927680 7;
BA_ "SAE_Document" BO_ 2633927680 "J1939-71";
BA_ "GenMsgSendType" BO_ 2566861857 0;
BA_ "GenMsgCycleTime" BO_ 2566861857 100;
BA_ "GenMsgSendType" BO_ 2566848256 0;
BA_ "GenMsgCycleTime" BO_ 2566848256 10000;
BA_ "SAE_Document" BO_ 2566848256 "J1939-71";
BA_ "GenMsgSendType" BO_ 2565865728 0;
BA_ "GenMsgCycleTime" BO_ 2565865728 100;
BA_ "SAE_Document" BO_ 2565865728 "J1939-71";
BA_ "GenMsgCycleTime" BO_ 2566854656 100;
BA_ "GenMsgSendType" BO_ 2566854656 0;
BA_ "SAE_Document" BO_ 2432593664 "J1939-71";
BA_ "GenMsgCycleTime" BO_ 2432593664 100;
BA_ "GenMsgSendType" BO_ 2432593664 0;
BA_ "SAE_Document" BO_ 2364539681 "J1939-71";
BA_ "GenMsgCycleTime" BO_ 2364539681 50;
BA_ "GenMsgSendType" BO_ 2364539681 0;
BA_ "SAE_Document" BO_ 2565865475 "J1939-71";
BA_ "GenMsgCycleTime" BO_ 2565865475 100;
BA_ "GenMsgSendType" BO_ 2565865475 0;
BA_ "SAE_Document" BO_ 2566844416 "J1939-71";
BA_ "GenMsgCycleTime" BO_ 2566844416 100;
BA_ "GenMsgSendType" BO_ 2566844416 0;
BA_ "GenMsgSendType" BO_ 2633935104 7;
BA_ "SAE_Document" BO_ 2633935104 "J1939-71";
BA_ "GenMsgSendType" BO_ 2566743296 0;
BA_ "GenMsgCycleTime" BO_ 2566743296 500;
BA_ "SAE_Document" BO_ 2566743296 "J1939-71";
BA_ "SAE_Document" BO_ 2566725632 "J1939-71";
BA_ "GenMsgSendType" BO_ 2566725632 0;
BA_ "GenMsgCycleTime" BO_ 2566725632 500;
BA_ "GenMsgSendType" BO_ 2633925376 7;
BA_ "GenMsgSendType" BO_ 2633925120 7;
BA_ "SAE_Document" BO_ 2566886649 "Prop";
BA_ "SAE_Document" BO_ 2348810282 "J1939-71";
BA_ "SAE_Document" BO_ 2348810251 "J1939-71";
BA_ "SAE_Document" BO_ 2565603105 "J1939-21";
BA_ "SAE_Document" BO_ 2565668641 "J1939-21";
BA_ "SAE_Document" BO_ 2565611799 "J1939-21";
BA_ "SAE_Document" BO_ 2565603351 "J1939-21";
BA_ "SAE_Document" BO_ 2565668631 "J1939-21";
BA_ "SAE_Document" BO_ 2565479447 "J1939-21";
BA_ "SAE_Document" BO_ 2566841600 "J1939-71";
BA_ "GenMsgSendType" BO_ 2566841600 7;
BA_ "SAE_Document" BO_ 2565865761 "J1939-71";
BA_ "GenMsgCycleTime" BO_ 2565865761 100;
BA_ "GenMsgSendType" BO_ 2565865761 0;
BA_ "SAE_Document" BO_ 2566834977 "J1939-73";
BA_ "SAE_Document" BO_ 2566834967 "J1939-73";
BA_ "SAE_Document" BO_ 2566834721 "J1939-73";
BA_ "SPN" SG_ 2365440512 FuelType 5837;
BA_ "SAEDocument" SG_ 2365440512 FuelType "J1939-71";
BA_ "Status" SG_ 2365440512 FuelType "3.10.0";
BA_ "SAEDocument" SG_ 2560818944 DTC_Total_PrevActive_Time_5 "J1939-73";
BA_ "SPN" SG_ 2560818944 DTC_Total_PrevActive_Time_5 4122;
BA_ "SigType" SG_ 2560818944 DTC_Total_PrevActive_Time_5 "RANGE";
BA_ "Status" SG_ 2560818944 DTC_Total_PrevActive_Time_5 "Requested 3.8.0";
BA_ "SAEDocument" SG_ 2560818944 DTC_Total_Active_Time_5 "J1939-73";
BA_ "SPN" SG_ 2560818944 DTC_Total_Active_Time_5 4121;
BA_ "SigType" SG_ 2560818944 DTC_Total_Active_Time_5 "RANGE";
BA_ "Status" SG_ 2560818944 DTC_Total_Active_Time_5 "Requested 3.8.0";
BA_ "SAEDocument" SG_ 2560818944 DTC_Time_Until_Derate_5 "J1939-73";
BA_ "SPN" SG_ 2560818944 DTC_Time_Until_Derate_5 4123;
BA_ "SigType" SG_ 2560818944 DTC_Time_Until_Derate_5 "RANGE";
BA_ "Status" SG_ 2560818944 DTC_Time_Until_Derate_5 "Requested 3.8.0";
BA_ "SAEDocument" SG_ 2560818944 DTC_Total_PrevActive_Time_4 "J1939-73";
BA_ "SPN" SG_ 2560818944 DTC_Total_PrevActive_Time_4 4122;
BA_ "SigType" SG_ 2560818944 DTC_Total_PrevActive_Time_4 "RANGE";
BA_ "Status" SG_ 2560818944 DTC_Total_PrevActive_Time_4 "Requested 3.8.0";
BA_ "SAEDocument" SG_ 2560818944 DTC_Total_Active_Time_4 "J1939-73";
BA_ "SPN" SG_ 2560818944 DTC_Total_Active_Time_4 4121;
BA_ "SigType" SG_ 2560818944 DTC_Total_Active_Time_4 "RANGE";
BA_ "Status" SG_ 2560818944 DTC_Total_Active_Time_4 "Requested 3.8.0";
BA_ "SAEDocument" SG_ 2560818944 DTC_Time_Until_Derate_4 "J1939-73";
BA_ "SPN" SG_ 2560818944 DTC_Time_Until_Derate_4 4123;
BA_ "SigType" SG_ 2560818944 DTC_Time_Until_Derate_4 "RANGE";
BA_ "Status" SG_ 2560818944 DTC_Time_Until_Derate_4 "Requested 3.8.0";
BA_ "SAEDocument" SG_ 2560818944 DTC_Total_PrevActive_Time_3 "J1939-73";
BA_ "SPN" SG_ 2560818944 DTC_Total_PrevActive_Time_3 4122;
BA_ "SigType" SG_ 2560818944 DTC_Total_PrevActive_Time_3 "RANGE";
BA_ "Status" SG_ 2560818944 DTC_Total_PrevActive_Time_3 "Requested 3.8.0";
BA_ "SAEDocument" SG_ 2560818944 DTC_Total_Active_Time_3 "J1939-73";
BA_ "SPN" SG_ 2560818944 DTC_Total_Active_Time_3 4121;
BA_ "SigType" SG_ 2560818944 DTC_Total_Active_Time_3 "RANGE";
BA_ "Status" SG_ 2560818944 DTC_Total_Active_Time_3 "Requested 3.8.0";
BA_ "SAEDocument" SG_ 2560818944 DTC_Time_Until_Derate_3 "J1939-73";
BA_ "SPN" SG_ 2560818944 DTC_Time_Until_Derate_3 4123;
BA_ "SigType" SG_ 2560818944 DTC_Time_Until_Derate_3 "RANGE";
BA_ "Status" SG_ 2560818944 DTC_Time_Until_Derate_3 "Requested 3.8.0";
BA_ "SAEDocument" SG_ 2560818944 DTC_Total_PrevActive_Time_2 "J1939-73";
BA_ "SPN" SG_ 2560818944 DTC_Total_PrevActive_Time_2 4122;
BA_ "SigType" SG_ 2560818944 DTC_Total_PrevActive_Time_2 "RANGE";
BA_ "Status" SG_ 2560818944 DTC_Total_PrevActive_Time_2 "Requested 3.8.0";
BA_ "SAEDocument" SG_ 2560818944 DTC_Total_Active_Time_2 "J1939-73";
BA_ "SPN" SG_ 2560818944 DTC_Total_Active_Time_2 4121;
BA_ "SigType" SG_ 2560818944 DTC_Total_Active_Time_2 "RANGE";
BA_ "Status" SG_ 2560818944 DTC_Total_Active_Time_2 "Requested 3.8.0";
BA_ "SAEDocument" SG_ 2560818944 DTC_Time_Until_Derate_2 "J1939-73";
BA_ "SPN" SG_ 2560818944 DTC_Time_Until_Derate_2 4123;
BA_ "SigType" SG_ 2560818944 DTC_Time_Until_Derate_2 "RANGE";
BA_ "Status" SG_ 2560818944 DTC_Time_Until_Derate_2 "Requested 3.8.0";
BA_ "SAEDocument" SG_ 2560818944 DTC_Total_PrevActive_Time_1 "J1939-73";
BA_ "SPN" SG_ 2560818944 DTC_Total_PrevActive_Time_1 4122;
BA_ "SigType" SG_ 2560818944 DTC_Total_PrevActive_Time_1 "RANGE";
BA_ "Status" SG_ 2560818944 DTC_Total_PrevActive_Time_1 "Requested 3.8.0";
BA_ "SAEDocument" SG_ 2560818944 DTC_Total_Active_Time_1 "J1939-73";
BA_ "SPN" SG_ 2560818944 DTC_Total_Active_Time_1 4121;
BA_ "SigType" SG_ 2560818944 DTC_Total_Active_Time_1 "RANGE";
BA_ "Status" SG_ 2560818944 DTC_Total_Active_Time_1 "Requested 3.8.0";
BA_ "SAEDocument" SG_ 2560818944 DTC_Time_Until_Derate_1 "J1939-73";
BA_ "SPN" SG_ 2560818944 DTC_Time_Until_Derate_1 4123;
BA_ "SigType" SG_ 2560818944 DTC_Time_Until_Derate_1 "RANGE";
BA_ "Status" SG_ 2560818944 DTC_Time_Until_Derate_1 "Requested 3.8.0";
BA_ "Status" SG_ 2560818944 SPN5 "2.1.0";
BA_ "SAEDocument" SG_ 2560818944 SPN5 "J1939-73";
BA_ "Variable" SG_ 2560818944 SPN5 "N/A";
BA_ "SPN" SG_ 2560818944 SPN5 1214;
BA_ "Status" SG_ 2560818944 SPN4 "2.1.0";
BA_ "SAEDocument" SG_ 2560818944 SPN4 "J1939-73";
BA_ "Variable" SG_ 2560818944 SPN4 "N/A";
BA_ "SPN" SG_ 2560818944 SPN4 1214;
BA_ "Status" SG_ 2560818944 SPN3 "2.1.0";
BA_ "SAEDocument" SG_ 2560818944 SPN3 "J1939-73";
BA_ "Variable" SG_ 2560818944 SPN3 "N/A";
BA_ "SPN" SG_ 2560818944 SPN3 1214;
BA_ "Status" SG_ 2560818944 SPN2 "2.1.0";
BA_ "SAEDocument" SG_ 2560818944 SPN2 "J1939-73";
BA_ "Variable" SG_ 2560818944 SPN2 "N/A";
BA_ "SPN" SG_ 2560818944 SPN2 1214;
BA_ "Status" SG_ 2560818944 FailureModeIdentifier1 "2.1.0";
BA_ "SPN" SG_ 2560818944 FailureModeIdentifier1 1215;
BA_ "SAEDocument" SG_ 2560818944 FailureModeIdentifier1 "J1939-73";
BA_ "Variable" SG_ 2560818944 FailureModeIdentifier1 "N/A";
BA_ "Status" SG_ 2560818944 SPN1 "2.1.0";
BA_ "SPN" SG_ 2560818944 SPN1 1214;
BA_ "SAEDocument" SG_ 2560818944 SPN1 "J1939-73";
BA_ "Variable" SG_ 2560818944 SPN1 "N/A";
BA_ "Status" SG_ 2560818944 FailureModeIdentifier2 "2.1.0";
BA_ "SAEDocument" SG_ 2560818944 FailureModeIdentifier2 "J1939-73";
BA_ "Variable" SG_ 2560818944 FailureModeIdentifier2 "N/A";
BA_ "SPN" SG_ 2560818944 FailureModeIdentifier2 1215;
BA_ "Status" SG_ 2560818944 SPN5High "2.1.0";
BA_ "SAEDocument" SG_ 2560818944 SPN5High "J1939-73";
BA_ "Variable" SG_ 2560818944 SPN5High "N/A";
BA_ "SPN" SG_ 2560818944 SPN5High 1214;
BA_ "Status" SG_ 2560818944 SPN4High "2.1.0";
BA_ "SAEDocument" SG_ 2560818944 SPN4High "J1939-73";
BA_ "Variable" SG_ 2560818944 SPN4High "N/A";
BA_ "SPN" SG_ 2560818944 SPN4High 1214;
BA_ "Status" SG_ 2560818944 SPN3High "2.1.0";
BA_ "SAEDocument" SG_ 2560818944 SPN3High "J1939-73";
BA_ "Variable" SG_ 2560818944 SPN3High "N/A";
BA_ "SPN" SG_ 2560818944 SPN3High 1214;
BA_ "Status" SG_ 2560818944 SPN2High "2.1.0";
BA_ "SAEDocument" SG_ 2560818944 SPN2High "J1939-73";
BA_ "Variable" SG_ 2560818944 SPN2High "N/A";
BA_ "SPN" SG_ 2560818944 SPN2High 1214;
BA_ "Status" SG_ 2560818944 SPN1High "2.1.0";
BA_ "SPN" SG_ 2560818944 SPN1High 1214;
BA_ "SAEDocument" SG_ 2560818944 SPN1High "J1939-73";
BA_ "Variable" SG_ 2560818944 SPN1High "N/A";
BA_ "SAEDocument" SG_ 2633926400 EngActualIgnTiming "J1939_71";
BA_ "SPN" SG_ 2633926400 EngActualIgnTiming 1436;
BA_ "SigType" SG_ 2633926400 EngActualIgnTiming "RANGE";
BA_ "Variable" SG_ 2633926400 EngActualIgnTiming "InjCrv_phiMI1Des";
BA_ "Status" SG_ 2633926400 EngActualIgnTiming "Requested 3.8.0";
BA_ "Status" SG_ 2365484270 TachographVehicleSpeed "Requested 3.7.0";
BA_ "Variable" SG_ 2365484270 TachographVehicleSpeed "Com_vTCO1Spd";
BA_ "SigType" SG_ 2365484270 TachographVehicleSpeed "RANGE";
BA_ "SPN" SG_ 2365484270 TachographVehicleSpeed 1624;
BA_ "SAEDocument" SG_ 2365484270 TachographVehicleSpeed "J1939-71";
BA_ "SAEDocument" SG_ 2566831399 FanSpeed_Rx "J1939-71";
BA_ "SPN" SG_ 2566831399 FanSpeed_Rx 1639;
BA_ "SigType" SG_ 2566831399 FanSpeed_Rx "RANGE";
BA_ "Variable" SG_ 2566831399 FanSpeed_Rx "Com_nFDFanSpd";
BA_ "Status" SG_ 2566831399 FanSpeed_Rx "3.5.2";
BA_ "SigType" SG_ 2348814091 EngOverrideCtrlMode "DISCRETE";
BA_ "SPN" SG_ 2348814091 EngOverrideCtrlMode 695;
BA_ "SAEDocument" SG_ 2348814091 EngOverrideCtrlMode "J1939-71";
BA_ "Variable" SG_ 2348814091 EngOverrideCtrlMode "Com_stTSC1*Mode";
BA_ "Status" SG_ 2348814091 EngOverrideCtrlMode "2.1.0";
BA_ "SigType" SG_ 2348814091 EngRqedTorque_TorqueLimit "RANGE";
BA_ "SPN" SG_ 2348814091 EngRqedTorque_TorqueLimit 518;
BA_ "SAEDocument" SG_ 2348814091 EngRqedTorque_TorqueLimit "J1939-71";
BA_ "Variable" SG_ 2348814091 EngRqedTorque_TorqueLimit "Com_dTSC1*Trq";
BA_ "Status" SG_ 2348814091 EngRqedTorque_TorqueLimit "2.1.0";
BA_ "SigType" SG_ 2348814091 EngRqedSpeed_SpeedLimit "RANGE";
BA_ "SPN" SG_ 2348814091 EngRqedSpeed_SpeedLimit 898;
BA_ "SAEDocument" SG_ 2348814091 EngRqedSpeed_SpeedLimit "J1939-71";
BA_ "Variable" SG_ 2348814091 EngRqedSpeed_SpeedLimit "Com_nTSC1*";
BA_ "Status" SG_ 2348814091 EngRqedSpeed_SpeedLimit "2.1.0";
BA_ "SigType" SG_ 2348814091 OverrideCtrlModePriority "DISCRETE";
BA_ "SPN" SG_ 2348814091 OverrideCtrlModePriority 897;
BA_ "SAEDocument" SG_ 2348814091 OverrideCtrlModePriority "J1939-71";
BA_ "Variable" SG_ 2348814091 OverrideCtrlModePriority "Com_stTSC1*Prio";
BA_ "Status" SG_ 2348814091 OverrideCtrlModePriority "2.1.0";
BA_ "SigType" SG_ 2348814083 EngRqedTorque_TorqueLimit "RANGE";
BA_ "SPN" SG_ 2348814083 EngRqedTorque_TorqueLimit 518;
BA_ "SAEDocument" SG_ 2348814083 EngRqedTorque_TorqueLimit "J1939-71";
BA_ "Status" SG_ 2348814083 EngRqedTorque_TorqueLimit "2.1.0";
BA_ "Variable" SG_ 2348814083 EngRqedTorque_TorqueLimit "Com_dTSC1*Trq";
BA_ "SigType" SG_ 2348814083 EngRqedSpeed_SpeedLimit "RANGE";
BA_ "SPN" SG_ 2348814083 EngRqedSpeed_SpeedLimit 898;
BA_ "SAEDocument" SG_ 2348814083 EngRqedSpeed_SpeedLimit "J1939-71";
BA_ "Status" SG_ 2348814083 EngRqedSpeed_SpeedLimit "2.1.0";
BA_ "Variable" SG_ 2348814083 EngRqedSpeed_SpeedLimit "Com_nTSC1*";
BA_ "SigType" SG_ 2348814083 OverrideCtrlModePriority "DISCRETE";
BA_ "SPN" SG_ 2348814083 OverrideCtrlModePriority 897;
BA_ "SAEDocument" SG_ 2348814083 OverrideCtrlModePriority "J1939-71";
BA_ "Status" SG_ 2348814083 OverrideCtrlModePriority "2.1.0";
BA_ "Variable" SG_ 2348814083 OverrideCtrlModePriority "Com_stTSC1*Prio";
BA_ "SigType" SG_ 2348814083 EngOverrideCtrlMode "DISCRETE";
BA_ "SPN" SG_ 2348814083 EngOverrideCtrlMode 695;
BA_ "SAEDocument" SG_ 2348814083 EngOverrideCtrlMode "J1939-71";
BA_ "Variable" SG_ 2348814083 EngOverrideCtrlMode "Com_stTSC1*Mode";
BA_ "Status" SG_ 2348814083 EngOverrideCtrlMode "2.1.0";
BA_ "Variable" SG_ 2566820864 EngExRangeCoolantPres "(CEngP_pSens-EnvP_pSens)";
BA_ "SAEDocument" SG_ 2566820864 EngExRangeCoolantPres "J1939-71";
BA_ "SPN" SG_ 2566820864 EngExRangeCoolantPres 20;
BA_ "SigType" SG_ 2566820864 EngExRangeCoolantPres "RANGE";
BA_ "Status" SG_ 2566820864 EngExRangeCoolantPres "Requested 3.7.0";
BA_ "SPN" SG_ 2566804992 AftSCROperatorInducementSeverity 5246;
BA_ "SAEDocument" SG_ 2566804992 AftSCROperatorInducementSeverity "SAE_J1939_71";
BA_ "SPN" SG_ 2566804992 Aft1DEFtankLowlevelIndicator 5245;
BA_ "SAEDocument" SG_ 2566804992 Aft1DEFtankLowlevelIndicator "SAEJ1939_71";
BA_ "SPN" SG_ 2566804992 AftertreatmentPIMCtalystTnkLvl 1761;
BA_ "SAEDocument" SG_ 2566804992 AftertreatmentPIMCtalystTnkLvl "SAE 1939_71";
BA_ "Variable" SG_ 2564816899 Req_Pct_Fan_Speed_Trans "Com_rFanPrcECM";
BA_ "Status" SG_ 2564816899 Req_Pct_Fan_Speed_Trans "3.5.0";
BA_ "SigType" SG_ 2564816899 Req_Pct_Fan_Speed_Trans "RANGE";
BA_ "SPN" SG_ 2564816899 Req_Pct_Fan_Speed_Trans 986;
BA_ "SAEDocument" SG_ 2564816899 Req_Pct_Fan_Speed_Trans "J1939-71";
BA_ "Status" SG_ 2633974265 PropResetInfo "3.4.9";
BA_ "SPN" SG_ 2633974265 PropResetInfo 522284;
BA_ "SAEDocument" SG_ 2364539392 TransOutputShaftSpeed_Tx "J1939-71";
BA_ "SPN" SG_ 2364539392 TransOutputShaftSpeed_Tx 191;
BA_ "SigType" SG_ 2364539392 TransOutputShaftSpeed_Tx "RANGE";
BA_ "Variable" SG_ 2364539392 TransOutputShaftSpeed_Tx "Vehv_nRawCrdSh";
BA_ "Status" SG_ 2364539392 TransOutputShaftSpeed_Tx "3.4.6";
BA_ "SigType" SG_ 2348814122 EngOverrideCtrlMode "DISCRETE";
BA_ "SPN" SG_ 2348814122 EngOverrideCtrlMode 695;
BA_ "SAEDocument" SG_ 2348814122 EngOverrideCtrlMode "J1939-71";
BA_ "Variable" SG_ 2348814122 EngOverrideCtrlMode "Com_stTSC1*Mode";
BA_ "Status" SG_ 2348814122 EngOverrideCtrlMode "3.4.x";
BA_ "SigType" SG_ 2348814122 EngRqedTorque_TorqueLimit "RANGE";
BA_ "SPN" SG_ 2348814122 EngRqedTorque_TorqueLimit 518;
BA_ "SAEDocument" SG_ 2348814122 EngRqedTorque_TorqueLimit "J1939-71";
BA_ "Variable" SG_ 2348814122 EngRqedTorque_TorqueLimit "Com_dTSC1*Trq";
BA_ "Status" SG_ 2348814122 EngRqedTorque_TorqueLimit "3.4.x";
BA_ "SigType" SG_ 2348814122 EngRqedSpeed_SpeedLimit "RANGE";
BA_ "SPN" SG_ 2348814122 EngRqedSpeed_SpeedLimit 898;
BA_ "SAEDocument" SG_ 2348814122 EngRqedSpeed_SpeedLimit "J1939-71";
BA_ "Variable" SG_ 2348814122 EngRqedSpeed_SpeedLimit "Com_nTSC1*";
BA_ "Status" SG_ 2348814122 EngRqedSpeed_SpeedLimit "3.4.x";
BA_ "SigType" SG_ 2348814122 OverrideCtrlModePriority "DISCRETE";
BA_ "SPN" SG_ 2348814122 OverrideCtrlModePriority 897;
BA_ "SAEDocument" SG_ 2348814122 OverrideCtrlModePriority "J1939-71";
BA_ "Variable" SG_ 2348814122 OverrideCtrlModePriority "Com_stTSC1*Prio";
BA_ "Status" SG_ 2348814122 OverrideCtrlModePriority "3.4.0";
BA_ "Status" SG_ 2566803754 ReqACCDistMode "3.4.0";
BA_ "Variable" SG_ 2566803754 ReqACCDistMode "Com_stACC2ReqDstMdFrm";
BA_ "SigType" SG_ 2566803754 ReqACCDistMode "RANGE";
BA_ "SPN" SG_ 2566803754 ReqACCDistMode 1799;
BA_ "SAEDocument" SG_ 2566803754 ReqACCDistMode "J1939-71";
BA_ "Status" SG_ 2564882176 Req_Pct_Fan_Speed_ECM "3.4.0";
BA_ "Variable" SG_ 2564882176 Req_Pct_Fan_Speed_ECM "Fans_nEnvLimSetP/Fans_nMax*100";
BA_ "SigType" SG_ 2564882176 Req_Pct_Fan_Speed_ECM "RANGE";
BA_ "SPN" SG_ 2564882176 Req_Pct_Fan_Speed_ECM 986;
BA_ "SAEDocument" SG_ 2564882176 Req_Pct_Fan_Speed_ECM "J1939-71";
BA_ "Status" SG_ 2631859961 EST_Trip_Reset "3.4.0";
BA_ "Variable" SG_ 2631859961 EST_Trip_Reset "Com_stTripSrvRst";
BA_ "SigType" SG_ 2631859961 EST_Trip_Reset "DISCRETE";
BA_ "SPN" SG_ 2631859961 EST_Trip_Reset 989;
BA_ "SAEDocument" SG_ 2631859961 EST_Trip_Reset "J1939-71";
BA_ "SAEDocument" SG_ 2561081377 GovSelSwitch "J1939-71";
BA_ "SPN" SG_ 2561081377 GovSelSwitch 3841;
BA_ "SigType" SG_ 2561081377 GovSelSwitch "DISCRETE";
BA_ "Variable" SG_ 2561081377 GovSelSwitch "Com_stSpdGov";
BA_ "Status" SG_ 2561081377 GovSelSwitch "3.4.0";
BA_ "Status" SG_ 2561081377 DataLogSwitch "3.4.0";
BA_ "SigType" SG_ 2561081377 DataLogSwitch "DISCRETE";
BA_ "SAEDocument" SG_ 2561081377 DataLogSwitch "J1939-71";
BA_ "Variable" SG_ 2561081377 DataLogSwitch "Com_stDatMeas";
BA_ "SPN" SG_ 2561081377 DataLogSwitch 3840;
BA_ "Variable" SG_ 2566844683 WheelBasedVehicleSpeed "Com_vVehSpd";
BA_ "SigType" SG_ 2566844683 WheelBasedVehicleSpeed "RANGE";
BA_ "SPN" SG_ 2566844683 WheelBasedVehicleSpeed 84;
BA_ "SAEDocument" SG_ 2566844683 WheelBasedVehicleSpeed "J1939-71";
BA_ "Status" SG_ 2566844683 WheelBasedVehicleSpeed "3.4.0";
BA_ "Status" SG_ 2566844714 CruiseCtrlResumeSwitch "3.4.x";
BA_ "SigType" SG_ 2566844714 CruiseCtrlResumeSwitch "DISCRETE";
BA_ "SPN" SG_ 2566844714 CruiseCtrlResumeSwitch 601;
BA_ "SAEDocument" SG_ 2566844714 CruiseCtrlResumeSwitch "J1939-71";
BA_ "Variable" SG_ 2566844714 CruiseCtrlResumeSwitch "Com_stResuSwt";
BA_ "Status" SG_ 2566844714 CruiseCtrlPauseSwitch "3.4.x";
BA_ "SigType" SG_ 2566844714 CruiseCtrlPauseSwitch "DISCRETE";
BA_ "SPN" SG_ 2566844714 CruiseCtrlPauseSwitch 1633;
BA_ "SAEDocument" SG_ 2566844714 CruiseCtrlPauseSwitch "J1939-71";
BA_ "Variable" SG_ 2566844714 CruiseCtrlPauseSwitch "Com_stPauseSwt";
BA_ "SAEDocument" SG_ 2566847009 Brake_Primary_Pressure "J1939-71";
BA_ "SPN" SG_ 2566847009 Brake_Primary_Pressure 117;
BA_ "SigType" SG_ 2566847009 Brake_Primary_Pressure "RANGE";
BA_ "Variable" SG_ 2566847009 Brake_Primary_Pressure "Com_pVehAirSys";
BA_ "Status" SG_ 2566847009 Brake_Primary_Pressure "3.4.x";
BA_ "SPN" SG_ 2566868992 AccelInterlockStatus 522261;
BA_ "Status" SG_ 2566868992 AccelInterlockStatus "3.5.0";
BA_ "SigType" SG_ 2566868992 AccelInterlockStatus "DISCRETE";
BA_ "SAEDocument" SG_ 2566868992 AccelInterlockStatus "J1939-71";
BA_ "Variable" SG_ 2566868992 AccelInterlockStatus "Com_stAccelIntrlckActv";
BA_ "Status" SG_ 2566868992 Adj_RSL_Status "3.4.0";
BA_ "Variable" SG_ 2566868992 Adj_RSL_Status "LLim_stVslAdjActv";
BA_ "SPN" SG_ 2566868992 Adj_RSL_Status 522258;
BA_ "SPN" SG_ 2566868992 Shift_Sync_Status 522255;
BA_ "Status" SG_ 2566868992 Shift_Sync_Status "3.3.0";
BA_ "Variable" SG_ 2566868992 Shift_Sync_Status "Based on USI_swtHiGearSync and VMD_swtLoGearSyncUSI";
BA_ "SPN" SG_ 2566868992 Upshift_Indicator 522256;
BA_ "Status" SG_ 2566868992 Upshift_Indicator "3.4.9";
BA_ "Variable" SG_ 2566868992 Upshift_Indicator "Com_stEnblUSI";
BA_ "SPN" SG_ 2566868992 RSL_Increase_Status 522253;
BA_ "Status" SG_ 2566868992 RSL_Increase_Status "3.3.0";
BA_ "Variable" SG_ 2566868992 RSL_Increase_Status "LLim_stIncSpdLim";
BA_ "SPN" SG_ 2566868992 RSL_Increase_Expiration 522254;
BA_ "Status" SG_ 2566868992 RSL_Increase_Expiration "3.3.0";
BA_ "Variable" SG_ 2566868992 RSL_Increase_Expiration "LLim_stFeatDeactvWarn";
BA_ "SPN" SG_ 2566868992 Driver_Reward_Lvl_Update 522252;
BA_ "Status" SG_ 2566868992 Driver_Reward_Lvl_Update "3.3.0";
BA_ "Variable" SG_ 2566868992 Driver_Reward_Lvl_Update "LLim_stDrvRwdUpdt";
BA_ "SPN" SG_ 2566868992 Driver_Reward_Lvl 522251;
BA_ "Status" SG_ 2566868992 Driver_Reward_Lvl "3.3.0";
BA_ "Variable" SG_ 2566868992 Driver_Reward_Lvl "LLim_numDrvRwdLvl";
BA_ "Variable" SG_ 2432498944 EngCmdFuelRailPress "Rail_pSetPoint";
BA_ "Status" SG_ 2432498944 EngCmdFuelRailPress "3.4.x";
BA_ "SAEDocument" SG_ 2432498944 EngCmdFuelRailPress "J1939-71";
BA_ "SPN" SG_ 2432498944 EngCmdFuelRailPress 5313;
BA_ "SigType" SG_ 2432498944 EngCmdFuelRailPress "RANGE";
BA_ "SAEDocument" SG_ 2565865470 OpModeReq "J1939-71";
BA_ "SigType" SG_ 2565865470 OpModeReq "DISCRETE";
BA_ "Variable" SG_ 2565865470 OpModeReq "Com_stOpModeReq";
BA_ "Status" SG_ 2565865470 OpModeReq "3.2.0";
BA_ "SPN" SG_ 2565865470 OpModeReq 520204;
BA_ "SAEDocument" SG_ 2565865216 OpModeCur "J1939-71";
BA_ "SigType" SG_ 2565865216 OpModeCur "DISCRETE";
BA_ "Variable" SG_ 2565865216 OpModeCur "CoEOM_stOpModeAct";
BA_ "Status" SG_ 2565865216 OpModeCur "3.2.0";
BA_ "SPN" SG_ 2565865216 OpModeCur 520203;
BA_ "SAEDocument" SG_ 2633936896 TripEngRunTime "J1939-71";
BA_ "SPN" SG_ 2633936896 TripEngRunTime 1036;
BA_ "SigType" SG_ 2633936896 TripEngRunTime "RANGE";
BA_ "Variable" SG_ 2633936896 TripEngRunTime "EngDa_tiEngOnTrip";
BA_ "Status" SG_ 2633936896 TripEngRunTime "3.2.0";
BA_ "SAEDocument" SG_ 2633936896 TripIdleTime "J1939-71";
BA_ "SPN" SG_ 2633936896 TripIdleTime 1037;
BA_ "SigType" SG_ 2633936896 TripIdleTime "RANGE";
BA_ "Variable" SG_ 2633936896 TripIdleTime "EngDa_ti_RTId_EngDaTripIdlRT";
BA_ "Status" SG_ 2633936896 TripIdleTime "3.2.0";
BA_ "SAEDocument" SG_ 2633939200 TripPTOStaFuelUsed "J1939-71";
BA_ "SPN" SG_ 2633939200 TripPTOStaFuelUsed 1003;
BA_ "SigType" SG_ 2633939200 TripPTOStaFuelUsed "RANGE";
BA_ "Variable" SG_ 2633939200 TripPTOStaFuelUsed "FlSys_volStatPTOConTrip";
BA_ "Status" SG_ 2633939200 TripPTOStaFuelUsed "3.2.0";
BA_ "SAEDocument" SG_ 2633939200 TripPTOMovingFuelUsed "J1939-71";
BA_ "SPN" SG_ 2633939200 TripPTOMovingFuelUsed 1002;
BA_ "SigType" SG_ 2633939200 TripPTOMovingFuelUsed "RANGE";
BA_ "Variable" SG_ 2633939200 TripPTOMovingFuelUsed "FlSys_volMobPTOConsTrip";
BA_ "Status" SG_ 2633939200 TripPTOMovingFuelUsed "3.2.0";
BA_ "SAEDocument" SG_ 2633939200 TripIdleFuelUsed "J1939-71";
BA_ "SPN" SG_ 2633939200 TripIdleFuelUsed 1004;
BA_ "SigType" SG_ 2633939200 TripIdleFuelUsed "RANGE";
BA_ "Variable" SG_ 2633939200 TripIdleFuelUsed "FlSys_volIdlFlConsTrip";
BA_ "Status" SG_ 2633939200 TripIdleFuelUsed "3.2.0";
BA_ "Variable" SG_ 2432520704 EngAuxCoolerSupValve2 "CThrVlv_rPs";
BA_ "Status" SG_ 2432520704 EngAuxCoolerSupValve2 "3.4.6";
BA_ "SigType" SG_ 2432520704 EngAuxCoolerSupValve2 "RANGE";
BA_ "SPN" SG_ 2432520704 EngAuxCoolerSupValve2 5547;
BA_ "SAEDocument" SG_ 2432520704 EngAuxCoolerSupValve2 "J1939-71";
BA_ "Status" SG_ 2432520704 EngAuxCoolerSupValve1 "3.2.0";
BA_ "SigType" SG_ 2432520704 EngAuxCoolerSupValve1 "RANGE";
BA_ "SPN" SG_ 2432520704 EngAuxCoolerSupValve1 5546;
BA_ "SAEDocument" SG_ 2432520704 EngAuxCoolerSupValve1 "J1939-71";
BA_ "Variable" SG_ 2432520704 EngAuxCoolerSupValve1 "CThmst_rPs";
BA_ "Status" SG_ 2432492288 EngineExhBrakeActCmd "3.2.0";
BA_ "SigType" SG_ 2432492288 EngineExhBrakeActCmd "RANGE";
BA_ "SPN" SG_ 2432492288 EngineExhBrakeActCmd 5543;
BA_ "SAEDocument" SG_ 2432492288 EngineExhBrakeActCmd "J1939-71";
BA_ "Variable" SG_ 2432492288 EngineExhBrakeActCmd "ExhFlpLP_rPs";
BA_ "Status" SG_ 2432492288 EngineTC2TurbOutPress "Not needed";
BA_ "SigType" SG_ 2432492288 EngineTC2TurbOutPress "RANGE";
BA_ "SPN" SG_ 2432492288 EngineTC2TurbOutPress 5544;
BA_ "SAEDocument" SG_ 2432492288 EngineTC2TurbOutPress "J1939-71";
BA_ "Status" SG_ 2432492288 EngineTC2DesTurbOutPress "Not needed";
BA_ "SigType" SG_ 2432492288 EngineTC2DesTurbOutPress "RANGE";
BA_ "SPN" SG_ 2432492288 EngineTC2DesTurbOutPress 5545;
BA_ "SAEDocument" SG_ 2432492288 EngineTC2DesTurbOutPress "J1939-71";
BA_ "Status" SG_ 2432492288 EngineTC1TurbOutPress "3.5.0";
BA_ "SigType" SG_ 2432492288 EngineTC1TurbOutPress "RANGE";
BA_ "SPN" SG_ 2432492288 EngineTC1TurbOutPress 5541;
BA_ "SAEDocument" SG_ 2432492288 EngineTC1TurbOutPress "J1939-71";
BA_ "Variable" SG_ 2432492288 EngineTC1TurbOutPress "Exh_pSensPTrbnDs - EnvP_pSens";
BA_ "Status" SG_ 2432492288 EngineTC1DesTurbOutPress "3.2.0";
BA_ "SigType" SG_ 2432492288 EngineTC1DesTurbOutPress "RANGE";
BA_ "SPN" SG_ 2432492288 EngineTC1DesTurbOutPress 5542;
BA_ "SAEDocument" SG_ 2432492288 EngineTC1DesTurbOutPress "J1939-71";
BA_ "Variable" SG_ 2432492288 EngineTC1DesTurbOutPress "EngBrk_pPresDes";
BA_ "Status" SG_ 2633927680 Relative_Humidity "3.2.0";
BA_ "SigType" SG_ 2633927680 Relative_Humidity "RANGE";
BA_ "SPN" SG_ 2633927680 Relative_Humidity 354;
BA_ "SAEDocument" SG_ 2633927680 Relative_Humidity "J1939-71";
BA_ "Variable" SG_ 2633927680 Relative_Humidity "ATHEval_rHmdLin";
BA_ "Variable" SG_ 2566861857 EngineWarmupEnable "Com_stHLSDemWrmEna";
BA_ "Status" SG_ 2566861857 EngineWarmupEnable "3.1.0";
BA_ "SigType" SG_ 2566861857 EngineWarmupEnable "DISCRETE";
BA_ "SPN" SG_ 2566848256 WIF 97;
BA_ "SAEDocument" SG_ 2566848256 WIF "J1939-71";
BA_ "Variable" SG_ 2566848256 WIF "Based on Fl_stWLvlSensDebVal";
BA_ "Status" SG_ 2566848256 WIF "3.2.0";
BA_ "SigType" SG_ 2565865728 EngRetarderSelection "RANGE";
BA_ "SPN" SG_ 2565865728 EngRetarderSelection 973;
BA_ "SAEDocument" SG_ 2565865728 EngRetarderSelection "J1939-71";
BA_ "Status" SG_ 2565865728 EngRetarderSelection "Not needed";
BA_ "Variable" SG_ 2565865728 EngAuxEngShutdownSwitch "ECBtn_stStopDebVal";
BA_ "Status" SG_ 2565865728 EngAuxEngShutdownSwitch "3.4.x";
BA_ "SigType" SG_ 2565865728 EngAuxEngShutdownSwitch "DISCRETE";
BA_ "SPN" SG_ 2565865728 EngAuxEngShutdownSwitch 970;
BA_ "SAEDocument" SG_ 2565865728 EngAuxEngShutdownSwitch "J1939-71";
BA_ "SigType" SG_ 2565865728 EngDerateSwitch "DISCRETE";
BA_ "SPN" SG_ 2565865728 EngDerateSwitch 971;
BA_ "SAEDocument" SG_ 2565865728 EngDerateSwitch "J1939-71";
BA_ "Status" SG_ 2565865728 EngDerateSwitch "Not needed";
BA_ "SigType" SG_ 2565865728 AntiLockBrakingActive "DISCRETE";
BA_ "SPN" SG_ 2565865728 AntiLockBrakingActive 563;
BA_ "SAEDocument" SG_ 2565865728 AntiLockBrakingActive "J1939-71";
BA_ "Status" SG_ 2565865728 AntiLockBrakingActive "Not needed";
BA_ "Status" SG_ 2566854656 ActualEngineTorque "2.3.0";
BA_ "Variable" SG_ 2566854656 ActualEngineTorque "ActMod_trqInr";
BA_ "SPN" SG_ 2566854656 ActualEngineTorque 522257;
BA_ "SigType" SG_ 2432593664 RoadCurvature "RANGE";
BA_ "SPN" SG_ 2432593664 RoadCurvature 1591;
BA_ "SAEDocument" SG_ 2432593664 RoadCurvature "J1939-71";
BA_ "Status" SG_ 2432593664 RoadCurvature "Not needed";
BA_ "SigType" SG_ 2432593664 AdptveCruiseCtrlSetDistanceMode "DISCRETE";
BA_ "SPN" SG_ 2432593664 AdptveCruiseCtrlSetDistanceMode 1589;
BA_ "SAEDocument" SG_ 2432593664 AdptveCruiseCtrlSetDistanceMode "J1939-71";
BA_ "Status" SG_ 2432593664 AdptveCruiseCtrlSetDistanceMode "Not needed";
BA_ "Variable" SG_ 2432593664 AdaptiveCruiseCtrlMode "Com_stCrCtlReq";
BA_ "SigType" SG_ 2432593664 AdaptiveCruiseCtrlMode "DISCRETE";
BA_ "SPN" SG_ 2432593664 AdaptiveCruiseCtrlMode 1590;
BA_ "SAEDocument" SG_ 2432593664 AdaptiveCruiseCtrlMode "J1939-71";
BA_ "Status" SG_ 2432593664 AdaptiveCruiseCtrlMode "3.4.9";
BA_ "SigType" SG_ 2432593664 AdaptiveCruiseCtrlSetSpeed "RANGE";
BA_ "SPN" SG_ 2432593664 AdaptiveCruiseCtrlSetSpeed 1588;
BA_ "SAEDocument" SG_ 2432593664 AdaptiveCruiseCtrlSetSpeed "J1939-71";
BA_ "Status" SG_ 2432593664 AdaptiveCruiseCtrlSetSpeed "Not needed";
BA_ "SigType" SG_ 2432593664 DistanceToForwardVehicle "RANGE";
BA_ "SPN" SG_ 2432593664 DistanceToForwardVehicle 1587;
BA_ "SAEDocument" SG_ 2432593664 DistanceToForwardVehicle "J1939-71";
BA_ "Status" SG_ 2432593664 DistanceToForwardVehicle "Not needed";
BA_ "SigType" SG_ 2432593664 SpeedOfForwardVehicle "RANGE";
BA_ "SPN" SG_ 2432593664 SpeedOfForwardVehicle 1586;
BA_ "SAEDocument" SG_ 2432593664 SpeedOfForwardVehicle "J1939-71";
BA_ "Status" SG_ 2432593664 SpeedOfForwardVehicle "Not needed";
BA_ "Variable" SG_ 2364539681 RemoteAccelPedalPos "Com_rAPP2";
BA_ "Status" SG_ 2364539681 RemoteAccelPedalPos "3.1.0";
BA_ "SigType" SG_ 2364539681 RemoteAccelPedalPos "RANGE";
BA_ "SPN" SG_ 2364539681 RemoteAccelPedalPos 974;
BA_ "SAEDocument" SG_ 2364539681 RemoteAccelPedalPos "J1939-71";
BA_ "SAEDocument" SG_ 2565865475 IntendedRetarderPercentTorque "J1939_71";
BA_ "SPN" SG_ 2565865475 IntendedRetarderPercentTorque 1085;
BA_ "SigType" SG_ 2565865475 IntendedRetarderPercentTorque "RANGE";
BA_ "Status" SG_ 2565865475 IntendedRetarderPercentTorque "Not needed";
BA_ "SigType" SG_ 2565865475 RetarderTorqueMode "DISCREET";
BA_ "SPN" SG_ 2565865475 RetarderTorqueMode 900;
BA_ "SAEDocument" SG_ 2565865475 RetarderTorqueMode "SAE J1939_71";
BA_ "Status" SG_ 2565865475 RetarderTorqueMode "Not needed";
BA_ "SAEDocument" SG_ 2565865475 RetarderEnableShiftAssistSwitch "SAE J1971";
BA_ "SPN" SG_ 2565865475 RetarderEnableShiftAssistSwitch 572;
BA_ "SigType" SG_ 2565865475 RetarderEnableShiftAssistSwitch "DISCREET";
BA_ "Status" SG_ 2565865475 RetarderEnableShiftAssistSwitch "Not needed";
BA_ "SigType" SG_ 2565865475 RetarderEnableBrakeAssistSwitch "DISCREET";
BA_ "SPN" SG_ 2565865475 RetarderEnableBrakeAssistSwitch 571;
BA_ "SAEDocument" SG_ 2565865475 RetarderEnableBrakeAssistSwitch "SAE J1939_71";
BA_ "Status" SG_ 2565865475 RetarderEnableBrakeAssistSwitch "Not needed";
BA_ "SigType" SG_ 2565865475 ActualRetarderPercentTorque "RANGE";
BA_ "SPN" SG_ 2565865475 ActualRetarderPercentTorque 520;
BA_ "SAEDocument" SG_ 2565865475 ActualRetarderPercentTorque "J1939-71";
BA_ "Status" SG_ 2565865475 ActualRetarderPercentTorque "Not needed";
BA_ "SAEDocument" SG_ 2566844416 PowerTakeoffSetSpeed "J1939-71";
BA_ "SPN" SG_ 2566844416 PowerTakeoffSetSpeed 187;
BA_ "SigType" SG_ 2566844416 PowerTakeoffSetSpeed "RANGE";
BA_ "Status" SG_ 2566844416 PowerTakeoffSetSpeed "3.4.0";
BA_ "Variable" SG_ 2566844416 PowerTakeoffSetSpeed "WESDem_nPrelimSetP";
BA_ "SigType" SG_ 2566844416 EngPTOAccelerateSwitch "DISCRETE";
BA_ "SPN" SG_ 2566844416 EngPTOAccelerateSwitch 981;
BA_ "SAEDocument" SG_ 2566844416 EngPTOAccelerateSwitch "J1939-71";
BA_ "Status" SG_ 2566844416 EngPTOAccelerateSwitch "Not needed";
BA_ "SigType" SG_ 2566844416 EngPTOResumeSwitch "DISCRETE";
BA_ "SPN" SG_ 2566844416 EngPTOResumeSwitch 982;
BA_ "SAEDocument" SG_ 2566844416 EngPTOResumeSwitch "J1939-71";
BA_ "Status" SG_ 2566844416 EngPTOResumeSwitch "Not needed";
BA_ "SigType" SG_ 2566844416 EngPTOCoast_DecelerateSwitch "DISCRETE";
BA_ "SPN" SG_ 2566844416 EngPTOCoast_DecelerateSwitch 983;
BA_ "SAEDocument" SG_ 2566844416 EngPTOCoast_DecelerateSwitch "J1939-71";
BA_ "Status" SG_ 2566844416 EngPTOCoast_DecelerateSwitch "Not needed";
BA_ "SigType" SG_ 2566844416 EngPTOSetSwitch "DISCRETE";
BA_ "SPN" SG_ 2566844416 EngPTOSetSwitch 984;
BA_ "SAEDocument" SG_ 2566844416 EngPTOSetSwitch "J1939-71";
BA_ "Status" SG_ 2566844416 EngPTOSetSwitch "Not needed";
BA_ "SigType" SG_ 2566844416 EngRmtPTOVriableSpeedCtrlSwitch "DISCRETE";
BA_ "SPN" SG_ 2566844416 EngRmtPTOVriableSpeedCtrlSwitch 978;
BA_ "SAEDocument" SG_ 2566844416 EngRmtPTOVriableSpeedCtrlSwitch "J1939-71";
BA_ "Status" SG_ 2566844416 EngRmtPTOVriableSpeedCtrlSwitch "3.4.0";
BA_ "Variable" SG_ 2566844416 EngRmtPTOVriableSpeedCtrlSwitch "PTOVSwt_st";
BA_ "SigType" SG_ 2566844416 EngRmtPTOPrprgrmmdSpdCtrlSwitch "DISCRETE";
BA_ "SPN" SG_ 2566844416 EngRmtPTOPrprgrmmdSpdCtrlSwitch 979;
BA_ "SAEDocument" SG_ 2566844416 EngRmtPTOPrprgrmmdSpdCtrlSwitch "J1939-71";
BA_ "Status" SG_ 2566844416 EngRmtPTOPrprgrmmdSpdCtrlSwitch "3.4.0";
BA_ "Variable" SG_ 2566844416 EngRmtPTOPrprgrmmdSpdCtrlSwitch "PTOPSwt_st";
BA_ "SigType" SG_ 2566844416 EngPTOEnableSwitch "DISCRETE";
BA_ "SPN" SG_ 2566844416 EngPTOEnableSwitch 980;
BA_ "SAEDocument" SG_ 2566844416 EngPTOEnableSwitch "J1939-71";
BA_ "Status" SG_ 2566844416 EngPTOEnableSwitch "Requested 3.6.0";
BA_ "SigType" SG_ 2566844416 RmtPTOPrprgrmmdSpeedCtrlSwitch2 "DISCRETE";
BA_ "SPN" SG_ 2566844416 RmtPTOPrprgrmmdSpeedCtrlSwitch2 3447;
BA_ "SAEDocument" SG_ 2566844416 RmtPTOPrprgrmmdSpeedCtrlSwitch2 "J1939-71";
BA_ "Status" SG_ 2566844416 RmtPTOPrprgrmmdSpeedCtrlSwitch2 "Not needed";
BA_ "Status" SG_ 2633935104 DesiredExhaustO2 "2.5.0";
BA_ "SAEDocument" SG_ 2633935104 DesiredExhaustO2 "J1939-71";
BA_ "SPN" SG_ 2633935104 DesiredExhaustO2 1118;
BA_ "Variable" SG_ 2633935104 DesiredExhaustO2 "EGRRgl_rLamNom";
BA_ "Variable" SG_ 2566743296 AT1HCDoserInFuelTemp "DPM_tSensHDVUsT";
BA_ "Status" SG_ 2566743296 AT1HCDoserInFuelTemp "3.1.0";
BA_ "SigType" SG_ 2566743296 AT1HCDoserInFuelTemp "RANGE";
BA_ "SPN" SG_ 2566743296 AT1HCDoserInFuelTemp 5456;
BA_ "SAEDocument" SG_ 2566743296 AT1HCDoserInFuelTemp "J1939-71";
BA_ "Status" SG_ 2566743296 Aftertreatment1FuelPress2 "2.2.0";
BA_ "Variable" SG_ 2566743296 Aftertreatment1FuelPress2 "DPM_pSensHDVDsP";
BA_ "SPN" SG_ 2566743296 Aftertreatment1FuelPress2 4077;
BA_ "SAEDocument" SG_ 2566743296 Aftertreatment1FuelPress2 "J1939-71";
BA_ "Variable" SG_ 2566725632 Aftertreatment1DOCOutTemp "Exh_tSensOxiCatDs";
BA_ "Status" SG_ 2566725632 Aftertreatment1DOCOutTemp "2.5.0";
BA_ "SPN" SG_ 2566725632 Aftertreatment1DOCOutTemp 4766;
BA_ "SAEDocument" SG_ 2566725632 Aftertreatment1DOCOutTemp "J1939-71";
BA_ "Variable" SG_ 2566725632 Aftertreatment1DOCInTemp "Exh_tSensOxiCatUs";
BA_ "Status" SG_ 2566725632 Aftertreatment1DOCInTemp "2.5.0";
BA_ "SPN" SG_ 2566725632 Aftertreatment1DOCInTemp 4765;
BA_ "SAEDocument" SG_ 2566725632 Aftertreatment1DOCInTemp "J1939-71";
BA_ "Status" SG_ 2633925376 EngCylinderIgnTiming6 "3.2.0";
BA_ "SAEDocument" SG_ 2633925376 EngCylinderIgnTiming6 "J1939_71";
BA_ "SPN" SG_ 2633925376 EngCylinderIgnTiming6 1418;
BA_ "SigType" SG_ 2633925376 EngCylinderIgnTiming6 "RANGE";
BA_ "Variable" SG_ 2633925376 EngCylinderIgnTiming6 "InjCrv_phiMI1Des";
BA_ "Status" SG_ 2633925376 EngCylinderIgnTiming5 "3.2.0";
BA_ "SAEDocument" SG_ 2633925376 EngCylinderIgnTiming5 "J1939_71";
BA_ "SPN" SG_ 2633925376 EngCylinderIgnTiming5 1417;
BA_ "SigType" SG_ 2633925376 EngCylinderIgnTiming5 "RANGE";
BA_ "Variable" SG_ 2633925376 EngCylinderIgnTiming5 "InjCrv_phiMI1Des";
BA_ "Status" SG_ 2633925120 EngCylinderIgnTiming4 "3.2.0";
BA_ "SAEDocument" SG_ 2633925120 EngCylinderIgnTiming4 "J1939_71";
BA_ "SPN" SG_ 2633925120 EngCylinderIgnTiming4 1416;
BA_ "SigType" SG_ 2633925120 EngCylinderIgnTiming4 "RANGE";
BA_ "Variable" SG_ 2633925120 EngCylinderIgnTiming4 "InjCrv_phiMI1Des";
BA_ "Status" SG_ 2633925120 EngCylinderIgnTiming3 "3.2.0";
BA_ "SAEDocument" SG_ 2633925120 EngCylinderIgnTiming3 "J1939_71";
BA_ "SPN" SG_ 2633925120 EngCylinderIgnTiming3 1415;
BA_ "SigType" SG_ 2633925120 EngCylinderIgnTiming3 "RANGE";
BA_ "Variable" SG_ 2633925120 EngCylinderIgnTiming3 "InjCrv_phiMI1Des";
BA_ "Status" SG_ 2633925120 EngCylinderIgnTiming2 "3.2.0";
BA_ "SAEDocument" SG_ 2633925120 EngCylinderIgnTiming2 "J1939_71";
BA_ "SPN" SG_ 2633925120 EngCylinderIgnTiming2 1414;
BA_ "SigType" SG_ 2633925120 EngCylinderIgnTiming2 "RANGE";
BA_ "Variable" SG_ 2633925120 EngCylinderIgnTiming2 "InjCrv_phiMI1Des";
BA_ "Status" SG_ 2633925120 EngCylinderIgnTiming1 "3.2.0";
BA_ "SAEDocument" SG_ 2633925120 EngCylinderIgnTiming1 "J1939_71";
BA_ "SPN" SG_ 2633925120 EngCylinderIgnTiming1 1413;
BA_ "SigType" SG_ 2633925120 EngCylinderIgnTiming1 "RANGE";
BA_ "Variable" SG_ 2633925120 EngCylinderIgnTiming1 "InjCrv_phiMI1Des";
BA_ "Status" SG_ 2566886649 Test_ID "Ok";
BA_ "Variable" SG_ 2566886649 Test_ID "N/A";
BA_ "SAEDocument" SG_ 2566886649 Test_ID "CDRIF";
BA_ "SigType" SG_ 2348810282 EngOverrideCtrlMode "DISCRETE";
BA_ "SPN" SG_ 2348810282 EngOverrideCtrlMode 695;
BA_ "SAEDocument" SG_ 2348810282 EngOverrideCtrlMode "J1939-71";
BA_ "Variable" SG_ 2348810282 EngOverrideCtrlMode "Com_stTSC1*Mode";
BA_ "Status" SG_ 2348810282 EngOverrideCtrlMode "3.4.x";
BA_ "SigType" SG_ 2348810282 EngRqedTorque_TorqueLimit "RANGE";
BA_ "SPN" SG_ 2348810282 EngRqedTorque_TorqueLimit 518;
BA_ "SAEDocument" SG_ 2348810282 EngRqedTorque_TorqueLimit "J1939-71";
BA_ "Variable" SG_ 2348810282 EngRqedTorque_TorqueLimit "Com_dTSC1*Trq";
BA_ "Status" SG_ 2348810282 EngRqedTorque_TorqueLimit "3.4.x";
BA_ "SigType" SG_ 2348810282 EngRqedSpeed_SpeedLimit "RANGE";
BA_ "SPN" SG_ 2348810282 EngRqedSpeed_SpeedLimit 898;
BA_ "SAEDocument" SG_ 2348810282 EngRqedSpeed_SpeedLimit "J1939-71";
BA_ "Variable" SG_ 2348810282 EngRqedSpeed_SpeedLimit "Com_nTSC1*";
BA_ "Status" SG_ 2348810282 EngRqedSpeed_SpeedLimit "3.4.x";
BA_ "SigType" SG_ 2348810282 OverrideCtrlModePriority "DISCRETE";
BA_ "SPN" SG_ 2348810282 OverrideCtrlModePriority 897;
BA_ "SAEDocument" SG_ 2348810282 OverrideCtrlModePriority "J1939-71";
BA_ "Variable" SG_ 2348810282 OverrideCtrlModePriority "Com_stTSC1*Prio";
BA_ "Status" SG_ 2348810282 OverrideCtrlModePriority "3.4.0";
BA_ "SigType" SG_ 2348810251 EngOverrideCtrlMode "DISCRETE";
BA_ "SPN" SG_ 2348810251 EngOverrideCtrlMode 695;
BA_ "SAEDocument" SG_ 2348810251 EngOverrideCtrlMode "J1939-71";
BA_ "Variable" SG_ 2348810251 EngOverrideCtrlMode "Com_stTSC1*Mode";
BA_ "Status" SG_ 2348810251 EngOverrideCtrlMode "2.1.0";
BA_ "SigType" SG_ 2348810251 EngRqedTorque_TorqueLimit "RANGE";
BA_ "SPN" SG_ 2348810251 EngRqedTorque_TorqueLimit 518;
BA_ "SAEDocument" SG_ 2348810251 EngRqedTorque_TorqueLimit "J1939-71";
BA_ "Variable" SG_ 2348810251 EngRqedTorque_TorqueLimit "Com_dTSC1*Trq";
BA_ "Status" SG_ 2348810251 EngRqedTorque_TorqueLimit "2.1.0";
BA_ "SigType" SG_ 2348810251 EngRqedSpeed_SpeedLimit "RANGE";
BA_ "SPN" SG_ 2348810251 EngRqedSpeed_SpeedLimit 898;
BA_ "SAEDocument" SG_ 2348810251 EngRqedSpeed_SpeedLimit "J1939-71";
BA_ "Variable" SG_ 2348810251 EngRqedSpeed_SpeedLimit "Com_nTSC1*";
BA_ "Status" SG_ 2348810251 EngRqedSpeed_SpeedLimit "2.1.0";
BA_ "SigType" SG_ 2348810251 OverrideCtrlModePriority "DISCRETE";
BA_ "SPN" SG_ 2348810251 OverrideCtrlModePriority 897;
BA_ "SAEDocument" SG_ 2348810251 OverrideCtrlModePriority "J1939-71";
BA_ "Variable" SG_ 2348810251 OverrideCtrlModePriority "Com_stTSC1*Prio";
BA_ "Status" SG_ 2348810251 OverrideCtrlModePriority "2.1.0";
BA_ "Status" SG_ 2565603105 SequenceNumber "Ok";
BA_ "Variable" SG_ 2565603105 SequenceNumber "N/A";
BA_ "SigType" SG_ 2565603105 SequenceNumber "RANGE";
BA_ "SPN" SG_ 2565603105 SequenceNumber 2572;
BA_ "SAEDocument" SG_ 2565603105 SequenceNumber "J1939-21";
BA_ "Status" SG_ 2565668641 TotalNumberOfPacketsEoMA "Ok";
BA_ "Variable" SG_ 2565668641 TotalNumberOfPacketsEoMA "N/A";
BA_ "SigType" SG_ 2565668641 TotalNumberOfPacketsEoMA "RANGE";
BA_ "SPN" SG_ 2565668641 TotalNumberOfPacketsEoMA 2558;
BA_ "SAEDocument" SG_ 2565668641 TotalNumberOfPacketsEoMA "J1939-21";
BA_ "Status" SG_ 2565668641 TotalMessageSizeEoMA "Ok";
BA_ "Variable" SG_ 2565668641 TotalMessageSizeEoMA "N/A";
BA_ "SigType" SG_ 2565668641 TotalMessageSizeEoMA "RANGE";
BA_ "SPN" SG_ 2565668641 TotalMessageSizeEoMA 2557;
BA_ "SAEDocument" SG_ 2565668641 TotalMessageSizeEoMA "J1939-21";
BA_ "Status" SG_ 2565668641 TotalMessageSizeBAM "Ok";
BA_ "Variable" SG_ 2565668641 TotalMessageSizeBAM "N/A";
BA_ "SigType" SG_ 2565668641 TotalMessageSizeBAM "RANGE";
BA_ "SPN" SG_ 2565668641 TotalMessageSizeBAM 2557;
BA_ "SAEDocument" SG_ 2565668641 TotalMessageSizeBAM "J1939-21";
BA_ "Status" SG_ 2565668641 TotalNumberOfPacketsBAM "Ok";
BA_ "Variable" SG_ 2565668641 TotalNumberOfPacketsBAM "N/A";
BA_ "SigType" SG_ 2565668641 TotalNumberOfPacketsBAM "RANGE";
BA_ "SPN" SG_ 2565668641 TotalNumberOfPacketsBAM 2558;
BA_ "SAEDocument" SG_ 2565668641 TotalNumberOfPacketsBAM "J1939-21";
BA_ "Status" SG_ 2565668641 ConnectionAbortReason "Ok";
BA_ "Variable" SG_ 2565668641 ConnectionAbortReason "N/A";
BA_ "SigType" SG_ 2565668641 ConnectionAbortReason "RANGE";
BA_ "SPN" SG_ 2565668641 ConnectionAbortReason 2570;
BA_ "SAEDocument" SG_ 2565668641 ConnectionAbortReason "J1939-21";
BA_ "Status" SG_ 2565668641 NextPacketNumberToBeSent "Ok";
BA_ "Variable" SG_ 2565668641 NextPacketNumberToBeSent "N/A";
BA_ "SigType" SG_ 2565668641 NextPacketNumberToBeSent "RANGE";
BA_ "SPN" SG_ 2565668641 NextPacketNumberToBeSent 2562;
BA_ "SAEDocument" SG_ 2565668641 NextPacketNumberToBeSent "J1939-21";
BA_ "Status" SG_ 2565668641 NumberOfPacketsThatCanBeSent "Ok";
BA_ "Variable" SG_ 2565668641 NumberOfPacketsThatCanBeSent "N/A";
BA_ "SigType" SG_ 2565668641 NumberOfPacketsThatCanBeSent "RANGE";
BA_ "SPN" SG_ 2565668641 NumberOfPacketsThatCanBeSent 2561;
BA_ "SAEDocument" SG_ 2565668641 NumberOfPacketsThatCanBeSent "J1939-21";
BA_ "Status" SG_ 2565668641 PGNumber "Ok";
BA_ "Variable" SG_ 2565668641 PGNumber "N/A";
BA_ "SPN" SG_ 2565668641 PGNumber 2560;
BA_ "SAEDocument" SG_ 2565668641 PGNumber "J1939-21";
BA_ "Status" SG_ 2565668641 MaximumNumberOfPackets "Ok";
BA_ "Variable" SG_ 2565668641 MaximumNumberOfPackets "N/A";
BA_ "SigType" SG_ 2565668641 MaximumNumberOfPackets "RANGE";
BA_ "SPN" SG_ 2565668641 MaximumNumberOfPackets 2559;
BA_ "SAEDocument" SG_ 2565668641 MaximumNumberOfPackets "J1939-21";
BA_ "Status" SG_ 2565668641 TotalNumberOfPackets "Ok";
BA_ "Variable" SG_ 2565668641 TotalNumberOfPackets "N/A";
BA_ "SigType" SG_ 2565668641 TotalNumberOfPackets "RANGE";
BA_ "SPN" SG_ 2565668641 TotalNumberOfPackets 2558;
BA_ "SAEDocument" SG_ 2565668641 TotalNumberOfPackets "J1939-21";
BA_ "Status" SG_ 2565668641 TotalMessageSize "Ok";
BA_ "Variable" SG_ 2565668641 TotalMessageSize "N/A";
BA_ "SigType" SG_ 2565668641 TotalMessageSize "RANGE";
BA_ "SPN" SG_ 2565668641 TotalMessageSize 2557;
BA_ "SAEDocument" SG_ 2565668641 TotalMessageSize "J1939-21";
BA_ "Status" SG_ 2565668641 ControlByte "Ok";
BA_ "Variable" SG_ 2565668641 ControlByte "N/A";
BA_ "SPN" SG_ 2565668641 ControlByte 2556;
BA_ "SAEDocument" SG_ 2565668641 ControlByte "J1939-21";
BA_ "Status" SG_ 2565611799 TotalNumberOfPacketsEoMA "Ok";
BA_ "Variable" SG_ 2565611799 TotalNumberOfPacketsEoMA "N/A";
BA_ "SigType" SG_ 2565611799 TotalNumberOfPacketsEoMA "RANGE";
BA_ "SPN" SG_ 2565611799 TotalNumberOfPacketsEoMA 2558;
BA_ "SAEDocument" SG_ 2565611799 TotalNumberOfPacketsEoMA "J1939-21";
BA_ "Status" SG_ 2565611799 TotalMessageSizeEoMA "Ok";
BA_ "Variable" SG_ 2565611799 TotalMessageSizeEoMA "N/A";
BA_ "SigType" SG_ 2565611799 TotalMessageSizeEoMA "RANGE";
BA_ "SPN" SG_ 2565611799 TotalMessageSizeEoMA 2557;
BA_ "SAEDocument" SG_ 2565611799 TotalMessageSizeEoMA "J1939-21";
BA_ "Status" SG_ 2565611799 TotalMessageSizeBAM "Ok";
BA_ "Variable" SG_ 2565611799 TotalMessageSizeBAM "N/A";
BA_ "SigType" SG_ 2565611799 TotalMessageSizeBAM "RANGE";
BA_ "SPN" SG_ 2565611799 TotalMessageSizeBAM 2557;
BA_ "SAEDocument" SG_ 2565611799 TotalMessageSizeBAM "J1939-21";
BA_ "Status" SG_ 2565611799 TotalNumberOfPacketsBAM "Ok";
BA_ "Variable" SG_ 2565611799 TotalNumberOfPacketsBAM "N/A";
BA_ "SigType" SG_ 2565611799 TotalNumberOfPacketsBAM "RANGE";
BA_ "SPN" SG_ 2565611799 TotalNumberOfPacketsBAM 2558;
BA_ "SAEDocument" SG_ 2565611799 TotalNumberOfPacketsBAM "J1939-21";
BA_ "Status" SG_ 2565611799 ConnectionAbortReason "Ok";
BA_ "Variable" SG_ 2565611799 ConnectionAbortReason "N/A";
BA_ "SigType" SG_ 2565611799 ConnectionAbortReason "RANGE";
BA_ "SPN" SG_ 2565611799 ConnectionAbortReason 2570;
BA_ "SAEDocument" SG_ 2565611799 ConnectionAbortReason "J1939-21";
BA_ "Status" SG_ 2565611799 NextPacketNumberToBeSent "Ok";
BA_ "Variable" SG_ 2565611799 NextPacketNumberToBeSent "N/A";
BA_ "SigType" SG_ 2565611799 NextPacketNumberToBeSent "RANGE";
BA_ "SPN" SG_ 2565611799 NextPacketNumberToBeSent 2562;
BA_ "SAEDocument" SG_ 2565611799 NextPacketNumberToBeSent "J1939-21";
BA_ "Status" SG_ 2565611799 NumberOfPacketsThatCanBeSent "Ok";
BA_ "Variable" SG_ 2565611799 NumberOfPacketsThatCanBeSent "N/A";
BA_ "SigType" SG_ 2565611799 NumberOfPacketsThatCanBeSent "RANGE";
BA_ "SPN" SG_ 2565611799 NumberOfPacketsThatCanBeSent 2561;
BA_ "SAEDocument" SG_ 2565611799 NumberOfPacketsThatCanBeSent "J1939-21";
BA_ "Status" SG_ 2565611799 PGNumber "Ok";
BA_ "Variable" SG_ 2565611799 PGNumber "N/A";
BA_ "SPN" SG_ 2565611799 PGNumber 2560;
BA_ "SAEDocument" SG_ 2565611799 PGNumber "J1939-21";
BA_ "Status" SG_ 2565611799 MaximumNumberOfPackets "Ok";
BA_ "Variable" SG_ 2565611799 MaximumNumberOfPackets "N/A";
BA_ "SigType" SG_ 2565611799 MaximumNumberOfPackets "RANGE";
BA_ "SPN" SG_ 2565611799 MaximumNumberOfPackets 2559;
BA_ "SAEDocument" SG_ 2565611799 MaximumNumberOfPackets "J1939-21";
BA_ "Status" SG_ 2565611799 TotalNumberOfPackets "Ok";
BA_ "Variable" SG_ 2565611799 TotalNumberOfPackets "N/A";
BA_ "SigType" SG_ 2565611799 TotalNumberOfPackets "RANGE";
BA_ "SPN" SG_ 2565611799 TotalNumberOfPackets 2558;
BA_ "SAEDocument" SG_ 2565611799 TotalNumberOfPackets "J1939-21";
BA_ "Status" SG_ 2565611799 TotalMessageSize "Ok";
BA_ "Variable" SG_ 2565611799 TotalMessageSize "N/A";
BA_ "SigType" SG_ 2565611799 TotalMessageSize "RANGE";
BA_ "SPN" SG_ 2565611799 TotalMessageSize 2557;
BA_ "SAEDocument" SG_ 2565611799 TotalMessageSize "J1939-21";
BA_ "Status" SG_ 2565611799 ControlByte "Ok";
BA_ "Variable" SG_ 2565611799 ControlByte "N/A";
BA_ "SPN" SG_ 2565611799 ControlByte 2556;
BA_ "SAEDocument" SG_ 2565611799 ControlByte "J1939-21";
BA_ "Status" SG_ 2565603351 TotalNumberOfPacketsEoMA "Ok";
BA_ "Variable" SG_ 2565603351 TotalNumberOfPacketsEoMA "N/A";
BA_ "SigType" SG_ 2565603351 TotalNumberOfPacketsEoMA "RANGE";
BA_ "SPN" SG_ 2565603351 TotalNumberOfPacketsEoMA 2558;
BA_ "SAEDocument" SG_ 2565603351 TotalNumberOfPacketsEoMA "J1939-21";
BA_ "Status" SG_ 2565603351 TotalMessageSizeEoMA "Ok";
BA_ "Variable" SG_ 2565603351 TotalMessageSizeEoMA "N/A";
BA_ "SigType" SG_ 2565603351 TotalMessageSizeEoMA "RANGE";
BA_ "SPN" SG_ 2565603351 TotalMessageSizeEoMA 2557;
BA_ "SAEDocument" SG_ 2565603351 TotalMessageSizeEoMA "J1939-21";
BA_ "Status" SG_ 2565603351 TotalMessageSizeBAM "Ok";
BA_ "Variable" SG_ 2565603351 TotalMessageSizeBAM "N/A";
BA_ "SigType" SG_ 2565603351 TotalMessageSizeBAM "RANGE";
BA_ "SPN" SG_ 2565603351 TotalMessageSizeBAM 2557;
BA_ "SAEDocument" SG_ 2565603351 TotalMessageSizeBAM "J1939-21";
BA_ "Status" SG_ 2565603351 TotalNumberOfPacketsBAM "Ok";
BA_ "Variable" SG_ 2565603351 TotalNumberOfPacketsBAM "N/A";
BA_ "SigType" SG_ 2565603351 TotalNumberOfPacketsBAM "RANGE";
BA_ "SPN" SG_ 2565603351 TotalNumberOfPacketsBAM 2558;
BA_ "SAEDocument" SG_ 2565603351 TotalNumberOfPacketsBAM "J1939-21";
BA_ "Status" SG_ 2565603351 ConnectionAbortReason "Ok";
BA_ "Variable" SG_ 2565603351 ConnectionAbortReason "N/A";
BA_ "SigType" SG_ 2565603351 ConnectionAbortReason "RANGE";
BA_ "SPN" SG_ 2565603351 ConnectionAbortReason 2570;
BA_ "SAEDocument" SG_ 2565603351 ConnectionAbortReason "J1939-21";
BA_ "Status" SG_ 2565603351 NextPacketNumberToBeSent "Ok";
BA_ "Variable" SG_ 2565603351 NextPacketNumberToBeSent "N/A";
BA_ "SigType" SG_ 2565603351 NextPacketNumberToBeSent "RANGE";
BA_ "SPN" SG_ 2565603351 NextPacketNumberToBeSent 2562;
BA_ "SAEDocument" SG_ 2565603351 NextPacketNumberToBeSent "J1939-21";
BA_ "Status" SG_ 2565603351 NumberOfPacketsThatCanBeSent "Ok";
BA_ "Variable" SG_ 2565603351 NumberOfPacketsThatCanBeSent "N/A";
BA_ "SigType" SG_ 2565603351 NumberOfPacketsThatCanBeSent "RANGE";
BA_ "SPN" SG_ 2565603351 NumberOfPacketsThatCanBeSent 2561;
BA_ "SAEDocument" SG_ 2565603351 NumberOfPacketsThatCanBeSent "J1939-21";
BA_ "Status" SG_ 2565603351 PGNumber "Ok";
BA_ "Variable" SG_ 2565603351 PGNumber "N/A";
BA_ "SPN" SG_ 2565603351 PGNumber 2560;
BA_ "SAEDocument" SG_ 2565603351 PGNumber "J1939-21";
BA_ "Status" SG_ 2565603351 MaximumNumberOfPackets "Ok";
BA_ "Variable" SG_ 2565603351 MaximumNumberOfPackets "N/A";
BA_ "SigType" SG_ 2565603351 MaximumNumberOfPackets "RANGE";
BA_ "SPN" SG_ 2565603351 MaximumNumberOfPackets 2559;
BA_ "SAEDocument" SG_ 2565603351 MaximumNumberOfPackets "J1939-21";
BA_ "Status" SG_ 2565603351 TotalNumberOfPackets "Ok";
BA_ "Variable" SG_ 2565603351 TotalNumberOfPackets "N/A";
BA_ "SigType" SG_ 2565603351 TotalNumberOfPackets "RANGE";
BA_ "SPN" SG_ 2565603351 TotalNumberOfPackets 2558;
BA_ "SAEDocument" SG_ 2565603351 TotalNumberOfPackets "J1939-21";
BA_ "Status" SG_ 2565603351 TotalMessageSize "Ok";
BA_ "Variable" SG_ 2565603351 TotalMessageSize "N/A";
BA_ "SigType" SG_ 2565603351 TotalMessageSize "RANGE";
BA_ "SPN" SG_ 2565603351 TotalMessageSize 2557;
BA_ "SAEDocument" SG_ 2565603351 TotalMessageSize "J1939-21";
BA_ "Status" SG_ 2565603351 ControlByte "Ok";
BA_ "Variable" SG_ 2565603351 ControlByte "N/A";
BA_ "SPN" SG_ 2565603351 ControlByte 2556;
BA_ "SAEDocument" SG_ 2565603351 ControlByte "J1939-21";
BA_ "Status" SG_ 2565668631 TotalNumberOfPacketsEoMA "Ok";
BA_ "Variable" SG_ 2565668631 TotalNumberOfPacketsEoMA "N/A";
BA_ "SigType" SG_ 2565668631 TotalNumberOfPacketsEoMA "RANGE";
BA_ "SPN" SG_ 2565668631 TotalNumberOfPacketsEoMA 2558;
BA_ "SAEDocument" SG_ 2565668631 TotalNumberOfPacketsEoMA "J1939-21";
BA_ "Status" SG_ 2565668631 TotalMessageSizeEoMA "Ok";
BA_ "Variable" SG_ 2565668631 TotalMessageSizeEoMA "N/A";
BA_ "SigType" SG_ 2565668631 TotalMessageSizeEoMA "RANGE";
BA_ "SPN" SG_ 2565668631 TotalMessageSizeEoMA 2557;
BA_ "SAEDocument" SG_ 2565668631 TotalMessageSizeEoMA "J1939-21";
BA_ "Status" SG_ 2565668631 TotalMessageSizeBAM "Ok";
BA_ "Variable" SG_ 2565668631 TotalMessageSizeBAM "N/A";
BA_ "SigType" SG_ 2565668631 TotalMessageSizeBAM "RANGE";
BA_ "SPN" SG_ 2565668631 TotalMessageSizeBAM 2557;
BA_ "SAEDocument" SG_ 2565668631 TotalMessageSizeBAM "J1939-21";
BA_ "Status" SG_ 2565668631 TotalNumberOfPacketsBAM "Ok";
BA_ "Variable" SG_ 2565668631 TotalNumberOfPacketsBAM "N/A";
BA_ "SigType" SG_ 2565668631 TotalNumberOfPacketsBAM "RANGE";
BA_ "SPN" SG_ 2565668631 TotalNumberOfPacketsBAM 2558;
BA_ "SAEDocument" SG_ 2565668631 TotalNumberOfPacketsBAM "J1939-21";
BA_ "Status" SG_ 2565668631 ConnectionAbortReason "Ok";
BA_ "Variable" SG_ 2565668631 ConnectionAbortReason "N/A";
BA_ "SigType" SG_ 2565668631 ConnectionAbortReason "RANGE";
BA_ "SPN" SG_ 2565668631 ConnectionAbortReason 2570;
BA_ "SAEDocument" SG_ 2565668631 ConnectionAbortReason "J1939-21";
BA_ "Status" SG_ 2565668631 NextPacketNumberToBeSent "Ok";
BA_ "Variable" SG_ 2565668631 NextPacketNumberToBeSent "N/A";
BA_ "SigType" SG_ 2565668631 NextPacketNumberToBeSent "RANGE";
BA_ "SPN" SG_ 2565668631 NextPacketNumberToBeSent 2562;
BA_ "SAEDocument" SG_ 2565668631 NextPacketNumberToBeSent "J1939-21";
BA_ "Status" SG_ 2565668631 NumberOfPacketsThatCanBeSent "Ok";
BA_ "Variable" SG_ 2565668631 NumberOfPacketsThatCanBeSent "N/A";
BA_ "SigType" SG_ 2565668631 NumberOfPacketsThatCanBeSent "RANGE";
BA_ "SPN" SG_ 2565668631 NumberOfPacketsThatCanBeSent 2561;
BA_ "SAEDocument" SG_ 2565668631 NumberOfPacketsThatCanBeSent "J1939-21";
BA_ "Status" SG_ 2565668631 PGNumber "Ok";
BA_ "Variable" SG_ 2565668631 PGNumber "N/A";
BA_ "SPN" SG_ 2565668631 PGNumber 2560;
BA_ "SAEDocument" SG_ 2565668631 PGNumber "J1939-21";
BA_ "Status" SG_ 2565668631 MaximumNumberOfPackets "Ok";
BA_ "Variable" SG_ 2565668631 MaximumNumberOfPackets "N/A";
BA_ "SigType" SG_ 2565668631 MaximumNumberOfPackets "RANGE";
BA_ "SPN" SG_ 2565668631 MaximumNumberOfPackets 2559;
BA_ "SAEDocument" SG_ 2565668631 MaximumNumberOfPackets "J1939-21";
BA_ "Status" SG_ 2565668631 TotalNumberOfPackets "Ok";
BA_ "Variable" SG_ 2565668631 TotalNumberOfPackets "N/A";
BA_ "SigType" SG_ 2565668631 TotalNumberOfPackets "RANGE";
BA_ "SPN" SG_ 2565668631 TotalNumberOfPackets 2558;
BA_ "SAEDocument" SG_ 2565668631 TotalNumberOfPackets "J1939-21";
BA_ "Status" SG_ 2565668631 TotalMessageSize "Ok";
BA_ "Variable" SG_ 2565668631 TotalMessageSize "N/A";
BA_ "SigType" SG_ 2565668631 TotalMessageSize "RANGE";
BA_ "SPN" SG_ 2565668631 TotalMessageSize 2557;
BA_ "SAEDocument" SG_ 2565668631 TotalMessageSize "J1939-21";
BA_ "Status" SG_ 2565668631 ControlByte "Ok";
BA_ "Variable" SG_ 2565668631 ControlByte "N/A";
BA_ "SPN" SG_ 2565668631 ControlByte 2556;
BA_ "SAEDocument" SG_ 2565668631 ControlByte "J1939-21";
BA_ "Status" SG_ 2565479447 ParameterGroupNumber "Ok";
BA_ "Variable" SG_ 2565479447 ParameterGroupNumber "N/A";
BA_ "SigType" SG_ 2565479447 ParameterGroupNumber "RANGE";
BA_ "SPN" SG_ 2565479447 ParameterGroupNumber 2540;
BA_ "SAEDocument" SG_ 2565479447 ParameterGroupNumber "J1939-21";
BA_ "Variable" SG_ 2566841600 EngTotalRevolutions "EngDa_nEngRevTot";
BA_ "SigType" SG_ 2566841600 EngTotalRevolutions "RANGE";
BA_ "SPN" SG_ 2566841600 EngTotalRevolutions 249;
BA_ "SAEDocument" SG_ 2566841600 EngTotalRevolutions "J1939-71";
BA_ "Status" SG_ 2566841600 EngTotalRevolutions "2.1.0";
BA_ "Variable" SG_ 2566841600 EngTotalHoursOfOperation "EngDa_tiEngOn";
BA_ "SigType" SG_ 2566841600 EngTotalHoursOfOperation "RANGE";
BA_ "SPN" SG_ 2566841600 EngTotalHoursOfOperation 247;
BA_ "SAEDocument" SG_ 2566841600 EngTotalHoursOfOperation "J1939-71";
BA_ "Status" SG_ 2566841600 EngTotalHoursOfOperation "2.1.0";
BA_ "SigType" SG_ 2565865761 ABSFullyOperational "DISCRETE";
BA_ "SPN" SG_ 2565865761 ABSFullyOperational 1243;
BA_ "SAEDocument" SG_ 2565865761 ABSFullyOperational "J1939-71";
BA_ "Status" SG_ 2565865761 ABSFullyOperational "Not needed";
BA_ "Variable" SG_ 2565865761 EngRetarderSelection "Com_rRtdrSel";
BA_ "Status" SG_ 2565865761 EngRetarderSelection "3.1.0";
BA_ "SigType" SG_ 2565865761 EngRetarderSelection "RANGE";
BA_ "SPN" SG_ 2565865761 EngRetarderSelection 973;
BA_ "SAEDocument" SG_ 2565865761 EngRetarderSelection "J1939-71";
BA_ "Variable" SG_ 2565865761 EngAuxEngShutdownSwitch "Com_stEngShOffSwt";
BA_ "Status" SG_ 2565865761 EngAuxEngShutdownSwitch "3.1.0";
BA_ "SigType" SG_ 2565865761 EngAuxEngShutdownSwitch "DISCRETE";
BA_ "SPN" SG_ 2565865761 EngAuxEngShutdownSwitch 970;
BA_ "SAEDocument" SG_ 2565865761 EngAuxEngShutdownSwitch "J1939-71";
BA_ "Variable" SG_ 2565865761 EngDerateSwitch "Com_stPrfmLimSwt";
BA_ "Status" SG_ 2565865761 EngDerateSwitch "3.1.0";
BA_ "SigType" SG_ 2565865761 EngDerateSwitch "DISCRETE";
BA_ "SPN" SG_ 2565865761 EngDerateSwitch 971;
BA_ "SAEDocument" SG_ 2565865761 EngDerateSwitch "J1939-71";
BA_ "SigType" SG_ 2565865761 AccelInterlockSwitch "DISCRETE";
BA_ "SPN" SG_ 2565865761 AccelInterlockSwitch 972;
BA_ "SAEDocument" SG_ 2565865761 AccelInterlockSwitch "J1939-71";
BA_ "Status" SG_ 2565865761 AccelInterlockSwitch "3.4.0";
BA_ "Variable" SG_ 2565865761 AccelInterlockSwitch "Com_stAccelIntrlck";
BA_ "SigType" SG_ 2565865761 TractionCtrlOverrideSwitch "DISCRETE";
BA_ "SPN" SG_ 2565865761 TractionCtrlOverrideSwitch 1238;
BA_ "SAEDocument" SG_ 2565865761 TractionCtrlOverrideSwitch "J1939-71";
BA_ "Status" SG_ 2565865761 TractionCtrlOverrideSwitch "Not needed";
BA_ "SigType" SG_ 2565865761 AntiLockBrakingActive "DISCRETE";
BA_ "SPN" SG_ 2565865761 AntiLockBrakingActive 563;
BA_ "SAEDocument" SG_ 2565865761 AntiLockBrakingActive "J1939-71";
BA_ "Status" SG_ 2565865761 AntiLockBrakingActive "Not needed";
BA_ "SAEDocument" SG_ 2566834977 FailureModeIdentifier5 "J1939-73";
BA_ "Variable" SG_ 2566834977 FailureModeIdentifier5 "N/A";
BA_ "Status" SG_ 2566834977 FailureModeIdentifier5 "Ok";
BA_ "SPN" SG_ 2566834977 FailureModeIdentifier5 1215;
BA_ "SAEDocument" SG_ 2566834977 FailureModeIdentifier4 "J1939-73";
BA_ "Variable" SG_ 2566834977 FailureModeIdentifier4 "N/A";
BA_ "Status" SG_ 2566834977 FailureModeIdentifier4 "Ok";
BA_ "SPN" SG_ 2566834977 FailureModeIdentifier4 1215;
BA_ "SAEDocument" SG_ 2566834977 FailureModeIdentifier3 "J1939-73";
BA_ "Variable" SG_ 2566834977 FailureModeIdentifier3 "N/A";
BA_ "Status" SG_ 2566834977 FailureModeIdentifier3 "Ok";
BA_ "SPN" SG_ 2566834977 FailureModeIdentifier3 1215;
BA_ "SAEDocument" SG_ 2566834977 FailureModeIdentifier2 "J1939-73";
BA_ "Variable" SG_ 2566834977 FailureModeIdentifier2 "N/A";
BA_ "Status" SG_ 2566834977 FailureModeIdentifier2 "Ok";
BA_ "SPN" SG_ 2566834977 FailureModeIdentifier2 1215;
BA_ "SPN" SG_ 2566834977 FailureModeIdentifier1 1215;
BA_ "SAEDocument" SG_ 2566834977 FailureModeIdentifier1 "J1939-73";
BA_ "Variable" SG_ 2566834977 FailureModeIdentifier1 "N/A";
BA_ "Status" SG_ 2566834977 FailureModeIdentifier1 "Ok";
BA_ "SPN" SG_ 2566834977 FlashRedStopLamp 3039;
BA_ "SAEDocument" SG_ 2566834977 FlashRedStopLamp "J1939-73";
BA_ "Variable" SG_ 2566834977 FlashRedStopLamp "N/A";
BA_ "Status" SG_ 2566834977 FlashRedStopLamp "Ok";
BA_ "SPN" SG_ 2566834977 FlashProtectLamp 3041;
BA_ "SAEDocument" SG_ 2566834977 FlashProtectLamp "J1939-73";
BA_ "Variable" SG_ 2566834977 FlashProtectLamp "N/A";
BA_ "Status" SG_ 2566834977 FlashProtectLamp "Ok";
BA_ "SigType" SG_ 2566834977 FlashMalfuncIndicatorLamp "DISCRETE";
BA_ "SPN" SG_ 2566834977 FlashMalfuncIndicatorLamp 3038;
BA_ "SAEDocument" SG_ 2566834977 FlashMalfuncIndicatorLamp "J1939-73";
BA_ "Variable" SG_ 2566834977 FlashMalfuncIndicatorLamp "N/A";
BA_ "Status" SG_ 2566834977 FlashMalfuncIndicatorLamp "Ok";
BA_ "SPN" SG_ 2566834977 FlashAmberWarningLamp 3040;
BA_ "SAEDocument" SG_ 2566834977 FlashAmberWarningLamp "J1939-73";
BA_ "Variable" SG_ 2566834977 FlashAmberWarningLamp "N/A";
BA_ "Status" SG_ 2566834977 FlashAmberWarningLamp "Ok";
BA_ "SAEDocument" SG_ 2566834977 SPN5 "J1939-73";
BA_ "Variable" SG_ 2566834977 SPN5 "N/A";
BA_ "Status" SG_ 2566834977 SPN5 "Ok";
BA_ "SPN" SG_ 2566834977 SPN5 1214;
BA_ "SAEDocument" SG_ 2566834977 SPN4 "J1939-73";
BA_ "Variable" SG_ 2566834977 SPN4 "N/A";
BA_ "Status" SG_ 2566834977 SPN4 "Ok";
BA_ "SPN" SG_ 2566834977 SPN4 1214;
BA_ "SAEDocument" SG_ 2566834977 SPN3 "J1939-73";
BA_ "Variable" SG_ 2566834977 SPN3 "N/A";
BA_ "Status" SG_ 2566834977 SPN3 "Ok";
BA_ "SPN" SG_ 2566834977 SPN3 1214;
BA_ "SAEDocument" SG_ 2566834977 SPN2 "J1939-73";
BA_ "Variable" SG_ 2566834977 SPN2 "N/A";
BA_ "Status" SG_ 2566834977 SPN2 "Ok";
BA_ "SPN" SG_ 2566834977 SPN2 1214;
BA_ "SPN" SG_ 2566834977 SPN1 1214;
BA_ "SAEDocument" SG_ 2566834977 SPN1 "J1939-73";
BA_ "Variable" SG_ 2566834977 SPN1 "N/A";
BA_ "Status" SG_ 2566834977 SPN1 "Ok";
BA_ "SigType" SG_ 2566834977 RedStopLampStatus "DISCRETE";
BA_ "SPN" SG_ 2566834977 RedStopLampStatus 623;
BA_ "SAEDocument" SG_ 2566834977 RedStopLampStatus "J1939-73";
BA_ "Variable" SG_ 2566834977 RedStopLampStatus "N/A";
BA_ "Status" SG_ 2566834977 RedStopLampStatus "Ok";
BA_ "SigType" SG_ 2566834977 ProtectLampStatus "DISCRETE";
BA_ "SPN" SG_ 2566834977 ProtectLampStatus 987;
BA_ "SAEDocument" SG_ 2566834977 ProtectLampStatus "J1939-73";
BA_ "Variable" SG_ 2566834977 ProtectLampStatus "N/A";
BA_ "Status" SG_ 2566834977 ProtectLampStatus "Ok";
BA_ "SigType" SG_ 2566834977 AmberWarningLampStatus "DISCRETE";
BA_ "SPN" SG_ 2566834977 AmberWarningLampStatus 624;
BA_ "SAEDocument" SG_ 2566834977 AmberWarningLampStatus "J1939-73";
BA_ "Variable" SG_ 2566834977 AmberWarningLampStatus "N/A";
BA_ "Status" SG_ 2566834977 AmberWarningLampStatus "Ok";
BA_ "SigType" SG_ 2566834977 MalfunctionIndicatorLampStatus "DISCRETE";
BA_ "SPN" SG_ 2566834977 MalfunctionIndicatorLampStatus 1213;
BA_ "SAEDocument" SG_ 2566834977 MalfunctionIndicatorLampStatus "J1939-73";
BA_ "Variable" SG_ 2566834977 MalfunctionIndicatorLampStatus "N/A";
BA_ "Status" SG_ 2566834977 MalfunctionIndicatorLampStatus "Ok";
BA_ "SigType" SG_ 2566834977 OccurenceCount1 "RANGE";
BA_ "SPN" SG_ 2566834977 OccurenceCount1 1216;
BA_ "SAEDocument" SG_ 2566834977 OccurenceCount1 "J1939-73";
BA_ "Variable" SG_ 2566834977 OccurenceCount1 "N/A";
BA_ "Status" SG_ 2566834977 OccurenceCount1 "Ok";
BA_ "SPN" SG_ 2566834977 SPNConversionMethod1 1706;
BA_ "SAEDocument" SG_ 2566834977 SPNConversionMethod1 "J1939-73";
BA_ "Variable" SG_ 2566834977 SPNConversionMethod1 "N/A";
BA_ "Status" SG_ 2566834977 SPNConversionMethod1 "Ok";
BA_ "SAEDocument" SG_ 2566834977 SPNConversionMethod5 "J1939-73";
BA_ "Variable" SG_ 2566834977 SPNConversionMethod5 "N/A";
BA_ "Status" SG_ 2566834977 SPNConversionMethod5 "Ok";
BA_ "SPN" SG_ 2566834977 SPNConversionMethod5 1706;
BA_ "SAEDocument" SG_ 2566834977 SPNConversionMethod4 "J1939-73";
BA_ "Variable" SG_ 2566834977 SPNConversionMethod4 "N/A";
BA_ "Status" SG_ 2566834977 SPNConversionMethod4 "Ok";
BA_ "SPN" SG_ 2566834977 SPNConversionMethod4 1706;
BA_ "SAEDocument" SG_ 2566834977 SPNConversionMethod3 "J1939-73";
BA_ "Variable" SG_ 2566834977 SPNConversionMethod3 "N/A";
BA_ "Status" SG_ 2566834977 SPNConversionMethod3 "Ok";
BA_ "SPN" SG_ 2566834977 SPNConversionMethod3 1706;
BA_ "SAEDocument" SG_ 2566834977 SPNConversionMethod2 "J1939-73";
BA_ "Variable" SG_ 2566834977 SPNConversionMethod2 "N/A";
BA_ "Status" SG_ 2566834977 SPNConversionMethod2 "Ok";
BA_ "SPN" SG_ 2566834977 SPNConversionMethod2 1706;
BA_ "SigType" SG_ 2566834977 OccurenceCount5 "RANGE";
BA_ "SAEDocument" SG_ 2566834977 OccurenceCount5 "J1939-73";
BA_ "Variable" SG_ 2566834977 OccurenceCount5 "N/A";
BA_ "Status" SG_ 2566834977 OccurenceCount5 "Ok";
BA_ "SPN" SG_ 2566834977 OccurenceCount5 1216;
BA_ "SigType" SG_ 2566834977 OccurenceCount4 "RANGE";
BA_ "SAEDocument" SG_ 2566834977 OccurenceCount4 "J1939-73";
BA_ "Variable" SG_ 2566834977 OccurenceCount4 "N/A";
BA_ "Status" SG_ 2566834977 OccurenceCount4 "Ok";
BA_ "SPN" SG_ 2566834977 OccurenceCount4 1216;
BA_ "SigType" SG_ 2566834977 OccurenceCount3 "RANGE";
BA_ "SAEDocument" SG_ 2566834977 OccurenceCount3 "J1939-73";
BA_ "Variable" SG_ 2566834977 OccurenceCount3 "N/A";
BA_ "Status" SG_ 2566834977 OccurenceCount3 "Ok";
BA_ "SPN" SG_ 2566834977 OccurenceCount3 1216;
BA_ "SigType" SG_ 2566834977 OccurenceCount2 "RANGE";
BA_ "SAEDocument" SG_ 2566834977 OccurenceCount2 "J1939-73";
BA_ "Variable" SG_ 2566834977 OccurenceCount2 "N/A";
BA_ "Status" SG_ 2566834977 OccurenceCount2 "Ok";
BA_ "SPN" SG_ 2566834977 OccurenceCount2 1216;
BA_ "SAEDocument" SG_ 2566834977 SPN5High "J1939-73";
BA_ "Variable" SG_ 2566834977 SPN5High "N/A";
BA_ "Status" SG_ 2566834977 SPN5High "Ok";
BA_ "SPN" SG_ 2566834977 SPN5High 1214;
BA_ "SAEDocument" SG_ 2566834977 SPN4High "J1939-73";
BA_ "Variable" SG_ 2566834977 SPN4High "N/A";
BA_ "Status" SG_ 2566834977 SPN4High "Ok";
BA_ "SPN" SG_ 2566834977 SPN4High 1214;
BA_ "SAEDocument" SG_ 2566834977 SPN3High "J1939-73";
BA_ "Variable" SG_ 2566834977 SPN3High "N/A";
BA_ "Status" SG_ 2566834977 SPN3High "Ok";
BA_ "SPN" SG_ 2566834977 SPN3High 1214;
BA_ "SAEDocument" SG_ 2566834977 SPN2High "J1939-73";
BA_ "Variable" SG_ 2566834977 SPN2High "N/A";
BA_ "Status" SG_ 2566834977 SPN2High "Ok";
BA_ "SPN" SG_ 2566834977 SPN2High 1214;
BA_ "SPN" SG_ 2566834977 SPN1High 1214;
BA_ "SAEDocument" SG_ 2566834977 SPN1High "J1939-73";
BA_ "Variable" SG_ 2566834977 SPN1High "N/A";
BA_ "Status" SG_ 2566834977 SPN1High "Ok";
BA_ "SAEDocument" SG_ 2566834967 FailureModeIdentifier5 "J1939-73";
BA_ "Variable" SG_ 2566834967 FailureModeIdentifier5 "N/A";
BA_ "Status" SG_ 2566834967 FailureModeIdentifier5 "Ok";
BA_ "SPN" SG_ 2566834967 FailureModeIdentifier5 1215;
BA_ "SAEDocument" SG_ 2566834967 FailureModeIdentifier4 "J1939-73";
BA_ "Variable" SG_ 2566834967 FailureModeIdentifier4 "N/A";
BA_ "Status" SG_ 2566834967 FailureModeIdentifier4 "Ok";
BA_ "SPN" SG_ 2566834967 FailureModeIdentifier4 1215;
BA_ "SAEDocument" SG_ 2566834967 FailureModeIdentifier3 "J1939-73";
BA_ "Variable" SG_ 2566834967 FailureModeIdentifier3 "N/A";
BA_ "Status" SG_ 2566834967 FailureModeIdentifier3 "Ok";
BA_ "SPN" SG_ 2566834967 FailureModeIdentifier3 1215;
BA_ "Status" SG_ 2566834967 FailureModeIdentifier2 "Ok";
BA_ "SAEDocument" SG_ 2566834967 FailureModeIdentifier2 "J1939-73";
BA_ "Variable" SG_ 2566834967 FailureModeIdentifier2 "N/A";
BA_ "SPN" SG_ 2566834967 FailureModeIdentifier2 1215;
BA_ "SPN" SG_ 2566834967 FailureModeIdentifier1 1215;
BA_ "SAEDocument" SG_ 2566834967 FailureModeIdentifier1 "J1939-73";
BA_ "Variable" SG_ 2566834967 FailureModeIdentifier1 "N/A";
BA_ "Status" SG_ 2566834967 FailureModeIdentifier1 "Ok";
BA_ "SPN" SG_ 2566834967 FlashRedStopLamp 3039;
BA_ "SAEDocument" SG_ 2566834967 FlashRedStopLamp "J1939-73";
BA_ "Variable" SG_ 2566834967 FlashRedStopLamp "N/A";
BA_ "Status" SG_ 2566834967 FlashRedStopLamp "Ok";
BA_ "SPN" SG_ 2566834967 FlashProtectLamp 3041;
BA_ "SAEDocument" SG_ 2566834967 FlashProtectLamp "J1939-73";
BA_ "Variable" SG_ 2566834967 FlashProtectLamp "N/A";
BA_ "Status" SG_ 2566834967 FlashProtectLamp "Ok";
BA_ "SigType" SG_ 2566834967 FlashMalfuncIndicatorLamp "DISCRETE";
BA_ "SPN" SG_ 2566834967 FlashMalfuncIndicatorLamp 3038;
BA_ "SAEDocument" SG_ 2566834967 FlashMalfuncIndicatorLamp "J1939-73";
BA_ "Variable" SG_ 2566834967 FlashMalfuncIndicatorLamp "N/A";
BA_ "Status" SG_ 2566834967 FlashMalfuncIndicatorLamp "Ok";
BA_ "SPN" SG_ 2566834967 FlashAmberWarningLamp 3040;
BA_ "SAEDocument" SG_ 2566834967 FlashAmberWarningLamp "J1939-73";
BA_ "Variable" SG_ 2566834967 FlashAmberWarningLamp "N/A";
BA_ "Status" SG_ 2566834967 FlashAmberWarningLamp "Ok";
BA_ "SAEDocument" SG_ 2566834967 SPN5 "J1939-73";
BA_ "Variable" SG_ 2566834967 SPN5 "N/A";
BA_ "Status" SG_ 2566834967 SPN5 "Ok";
BA_ "SPN" SG_ 2566834967 SPN5 1214;
BA_ "SAEDocument" SG_ 2566834967 SPN4 "J1939-73";
BA_ "Variable" SG_ 2566834967 SPN4 "N/A";
BA_ "Status" SG_ 2566834967 SPN4 "Ok";
BA_ "SPN" SG_ 2566834967 SPN4 1214;
BA_ "SAEDocument" SG_ 2566834967 SPN3 "J1939-73";
BA_ "Variable" SG_ 2566834967 SPN3 "N/A";
BA_ "Status" SG_ 2566834967 SPN3 "Ok";
BA_ "SPN" SG_ 2566834967 SPN3 1214;
BA_ "SAEDocument" SG_ 2566834967 SPN2 "J1939-73";
BA_ "Variable" SG_ 2566834967 SPN2 "N/A";
BA_ "Status" SG_ 2566834967 SPN2 "Ok";
BA_ "SPN" SG_ 2566834967 SPN2 1214;
BA_ "SPN" SG_ 2566834967 SPN1 1214;
BA_ "SAEDocument" SG_ 2566834967 SPN1 "J1939-73";
BA_ "Variable" SG_ 2566834967 SPN1 "N/A";
BA_ "Status" SG_ 2566834967 SPN1 "Ok";
BA_ "SigType" SG_ 2566834967 RedStopLampStatus "DISCRETE";
BA_ "SPN" SG_ 2566834967 RedStopLampStatus 623;
BA_ "SAEDocument" SG_ 2566834967 RedStopLampStatus "J1939-73";
BA_ "Variable" SG_ 2566834967 RedStopLampStatus "N/A";
BA_ "Status" SG_ 2566834967 RedStopLampStatus "Ok";
BA_ "SigType" SG_ 2566834967 ProtectLampStatus "DISCRETE";
BA_ "SPN" SG_ 2566834967 ProtectLampStatus 987;
BA_ "SAEDocument" SG_ 2566834967 ProtectLampStatus "J1939-73";
BA_ "Variable" SG_ 2566834967 ProtectLampStatus "N/A";
BA_ "Status" SG_ 2566834967 ProtectLampStatus "Ok";
BA_ "SigType" SG_ 2566834967 AmberWarningLampStatus "DISCRETE";
BA_ "SPN" SG_ 2566834967 AmberWarningLampStatus 624;
BA_ "SAEDocument" SG_ 2566834967 AmberWarningLampStatus "J1939-73";
BA_ "Variable" SG_ 2566834967 AmberWarningLampStatus "N/A";
BA_ "Status" SG_ 2566834967 AmberWarningLampStatus "Ok";
BA_ "SigType" SG_ 2566834967 MalfunctionIndicatorLampStatus "DISCRETE";
BA_ "SPN" SG_ 2566834967 MalfunctionIndicatorLampStatus 1213;
BA_ "SAEDocument" SG_ 2566834967 MalfunctionIndicatorLampStatus "J1939-73";
BA_ "Variable" SG_ 2566834967 MalfunctionIndicatorLampStatus "N/A";
BA_ "Status" SG_ 2566834967 MalfunctionIndicatorLampStatus "Ok";
BA_ "SigType" SG_ 2566834967 OccurenceCount1 "RANGE";
BA_ "SPN" SG_ 2566834967 OccurenceCount1 1216;
BA_ "SAEDocument" SG_ 2566834967 OccurenceCount1 "J1939-73";
BA_ "Variable" SG_ 2566834967 OccurenceCount1 "N/A";
BA_ "Status" SG_ 2566834967 OccurenceCount1 "Ok";
BA_ "SPN" SG_ 2566834967 SPNConversionMethod1 1706;
BA_ "SAEDocument" SG_ 2566834967 SPNConversionMethod1 "J1939-73";
BA_ "Variable" SG_ 2566834967 SPNConversionMethod1 "N/A";
BA_ "Status" SG_ 2566834967 SPNConversionMethod1 "Ok";
BA_ "SAEDocument" SG_ 2566834967 SPNConversionMethod5 "J1939-73";
BA_ "Variable" SG_ 2566834967 SPNConversionMethod5 "N/A";
BA_ "Status" SG_ 2566834967 SPNConversionMethod5 "Ok";
BA_ "SPN" SG_ 2566834967 SPNConversionMethod5 1706;
BA_ "SAEDocument" SG_ 2566834967 SPNConversionMethod4 "J1939-73";
BA_ "Variable" SG_ 2566834967 SPNConversionMethod4 "N/A";
BA_ "Status" SG_ 2566834967 SPNConversionMethod4 "Ok";
BA_ "SPN" SG_ 2566834967 SPNConversionMethod4 1706;
BA_ "SAEDocument" SG_ 2566834967 SPNConversionMethod3 "J1939-73";
BA_ "Variable" SG_ 2566834967 SPNConversionMethod3 "N/A";
BA_ "Status" SG_ 2566834967 SPNConversionMethod3 "Ok";
BA_ "SPN" SG_ 2566834967 SPNConversionMethod3 1706;
BA_ "SAEDocument" SG_ 2566834967 SPNConversionMethod2 "J1939-73";
BA_ "Variable" SG_ 2566834967 SPNConversionMethod2 "N/A";
BA_ "Status" SG_ 2566834967 SPNConversionMethod2 "Ok";
BA_ "SPN" SG_ 2566834967 SPNConversionMethod2 1706;
BA_ "SigType" SG_ 2566834967 OccurenceCount5 "RANGE";
BA_ "SAEDocument" SG_ 2566834967 OccurenceCount5 "J1939-73";
BA_ "Variable" SG_ 2566834967 OccurenceCount5 "N/A";
BA_ "Status" SG_ 2566834967 OccurenceCount5 "Ok";
BA_ "SPN" SG_ 2566834967 OccurenceCount5 1216;
BA_ "SigType" SG_ 2566834967 OccurenceCount4 "RANGE";
BA_ "SAEDocument" SG_ 2566834967 OccurenceCount4 "J1939-73";
BA_ "Variable" SG_ 2566834967 OccurenceCount4 "N/A";
BA_ "Status" SG_ 2566834967 OccurenceCount4 "Ok";
BA_ "SPN" SG_ 2566834967 OccurenceCount4 1216;
BA_ "SigType" SG_ 2566834967 OccurenceCount3 "RANGE";
BA_ "SAEDocument" SG_ 2566834967 OccurenceCount3 "J1939-73";
BA_ "Variable" SG_ 2566834967 OccurenceCount3 "N/A";
BA_ "Status" SG_ 2566834967 OccurenceCount3 "Ok";
BA_ "SPN" SG_ 2566834967 OccurenceCount3 1216;
BA_ "SigType" SG_ 2566834967 OccurenceCount2 "RANGE";
BA_ "SAEDocument" SG_ 2566834967 OccurenceCount2 "J1939-73";
BA_ "Variable" SG_ 2566834967 OccurenceCount2 "N/A";
BA_ "Status" SG_ 2566834967 OccurenceCount2 "Ok";
BA_ "SPN" SG_ 2566834967 OccurenceCount2 1216;
BA_ "SAEDocument" SG_ 2566834967 SPN5High "J1939-73";
BA_ "Variable" SG_ 2566834967 SPN5High "N/A";
BA_ "Status" SG_ 2566834967 SPN5High "Ok";
BA_ "SPN" SG_ 2566834967 SPN5High 1214;
BA_ "SAEDocument" SG_ 2566834967 SPN4High "J1939-73";
BA_ "Variable" SG_ 2566834967 SPN4High "N/A";
BA_ "Status" SG_ 2566834967 SPN4High "Ok";
BA_ "SPN" SG_ 2566834967 SPN4High 1214;
BA_ "SAEDocument" SG_ 2566834967 SPN3High "J1939-73";
BA_ "Variable" SG_ 2566834967 SPN3High "N/A";
BA_ "Status" SG_ 2566834967 SPN3High "Ok";
BA_ "SPN" SG_ 2566834967 SPN3High 1214;
BA_ "SAEDocument" SG_ 2566834967 SPN2High "J1939-73";
BA_ "Variable" SG_ 2566834967 SPN2High "N/A";
BA_ "Status" SG_ 2566834967 SPN2High "Ok";
BA_ "SPN" SG_ 2566834967 SPN2High 1214;
BA_ "SPN" SG_ 2566834967 SPN1High 1214;
BA_ "SAEDocument" SG_ 2566834967 SPN1High "J1939-73";
BA_ "Variable" SG_ 2566834967 SPN1High "N/A";
BA_ "Status" SG_ 2566834967 SPN1High "Ok";
BA_ "SAEDocument" SG_ 2566834721 FailureModeIdentifier5 "J1939-73";
BA_ "Variable" SG_ 2566834721 FailureModeIdentifier5 "N/A";
BA_ "Status" SG_ 2566834721 FailureModeIdentifier5 "Ok";
BA_ "SPN" SG_ 2566834721 FailureModeIdentifier5 1215;
BA_ "SAEDocument" SG_ 2566834721 FailureModeIdentifier4 "J1939-73";
BA_ "Variable" SG_ 2566834721 FailureModeIdentifier4 "N/A";
BA_ "Status" SG_ 2566834721 FailureModeIdentifier4 "Ok";
BA_ "SPN" SG_ 2566834721 FailureModeIdentifier4 1215;
BA_ "SAEDocument" SG_ 2566834721 FailureModeIdentifier3 "J1939-73";
BA_ "Variable" SG_ 2566834721 FailureModeIdentifier3 "N/A";
BA_ "Status" SG_ 2566834721 FailureModeIdentifier3 "Ok";
BA_ "SPN" SG_ 2566834721 FailureModeIdentifier3 1215;
BA_ "Status" SG_ 2566834721 FailureModeIdentifier2 "Ok";
BA_ "SAEDocument" SG_ 2566834721 FailureModeIdentifier2 "J1939-73";
BA_ "Variable" SG_ 2566834721 FailureModeIdentifier2 "N/A";
BA_ "SPN" SG_ 2566834721 FailureModeIdentifier2 1215;
BA_ "SPN" SG_ 2566834721 FailureModeIdentifier1 1215;
BA_ "SAEDocument" SG_ 2566834721 FailureModeIdentifier1 "J1939-73";
BA_ "Variable" SG_ 2566834721 FailureModeIdentifier1 "N/A";
BA_ "Status" SG_ 2566834721 FailureModeIdentifier1 "Ok";
BA_ "SAEDocument" SG_ 2566834721 SPN5 "J1939-73";
BA_ "Variable" SG_ 2566834721 SPN5 "N/A";
BA_ "Status" SG_ 2566834721 SPN5 "Ok";
BA_ "SPN" SG_ 2566834721 SPN5 1214;
BA_ "SAEDocument" SG_ 2566834721 SPN4 "J1939-73";
BA_ "Variable" SG_ 2566834721 SPN4 "N/A";
BA_ "Status" SG_ 2566834721 SPN4 "Ok";
BA_ "SPN" SG_ 2566834721 SPN4 1214;
BA_ "SAEDocument" SG_ 2566834721 SPN3 "J1939-73";
BA_ "Variable" SG_ 2566834721 SPN3 "N/A";
BA_ "Status" SG_ 2566834721 SPN3 "Ok";
BA_ "SPN" SG_ 2566834721 SPN3 1214;
BA_ "SAEDocument" SG_ 2566834721 SPN2 "J1939-73";
BA_ "Variable" SG_ 2566834721 SPN2 "N/A";
BA_ "Status" SG_ 2566834721 SPN2 "Ok";
BA_ "SPN" SG_ 2566834721 SPN2 1214;
BA_ "SPN" SG_ 2566834721 SPN1 1214;
BA_ "SAEDocument" SG_ 2566834721 SPN1 "J1939-73";
BA_ "Variable" SG_ 2566834721 SPN1 "N/A";
BA_ "Status" SG_ 2566834721 SPN1 "Ok";
BA_ "SigType" SG_ 2566834721 RedStopLampStatus "DISCRETE";
BA_ "SPN" SG_ 2566834721 RedStopLampStatus 623;
BA_ "SAEDocument" SG_ 2566834721 RedStopLampStatus "J1939-73";
BA_ "Variable" SG_ 2566834721 RedStopLampStatus "N/A";
BA_ "Status" SG_ 2566834721 RedStopLampStatus "Ok";
BA_ "SigType" SG_ 2566834721 ProtectLampStatus "DISCRETE";
BA_ "SPN" SG_ 2566834721 ProtectLampStatus 987;
BA_ "SAEDocument" SG_ 2566834721 ProtectLampStatus "J1939-73";
BA_ "Variable" SG_ 2566834721 ProtectLampStatus "N/A";
BA_ "Status" SG_ 2566834721 ProtectLampStatus "Ok";
BA_ "SigType" SG_ 2566834721 AmberWarningLampStatus "DISCRETE";
BA_ "SPN" SG_ 2566834721 AmberWarningLampStatus 624;
BA_ "SAEDocument" SG_ 2566834721 AmberWarningLampStatus "J1939-73";
BA_ "Variable" SG_ 2566834721 AmberWarningLampStatus "N/A";
BA_ "Status" SG_ 2566834721 AmberWarningLampStatus "Ok";
BA_ "SigType" SG_ 2566834721 MalfunctionIndicatorLampStatus "DISCRETE";
BA_ "SPN" SG_ 2566834721 MalfunctionIndicatorLampStatus 1213;
BA_ "SAEDocument" SG_ 2566834721 MalfunctionIndicatorLampStatus "J1939-73";
BA_ "Variable" SG_ 2566834721 MalfunctionIndicatorLampStatus "N/A";
BA_ "Status" SG_ 2566834721 MalfunctionIndicatorLampStatus "Ok";
BA_ "SPN" SG_ 2566834721 FlashRedStopLamp 3039;
BA_ "SAEDocument" SG_ 2566834721 FlashRedStopLamp "J1939-73";
BA_ "Variable" SG_ 2566834721 FlashRedStopLamp "N/A";
BA_ "Status" SG_ 2566834721 FlashRedStopLamp "Ok";
BA_ "SPN" SG_ 2566834721 FlashProtectLamp 3041;
BA_ "SAEDocument" SG_ 2566834721 FlashProtectLamp "J1939-73";
BA_ "Variable" SG_ 2566834721 FlashProtectLamp "N/A";
BA_ "Status" SG_ 2566834721 FlashProtectLamp "Ok";
BA_ "SigType" SG_ 2566834721 FlashMalfuncIndicatorLamp "DISCRETE";
BA_ "SPN" SG_ 2566834721 FlashMalfuncIndicatorLamp 3038;
BA_ "SAEDocument" SG_ 2566834721 FlashMalfuncIndicatorLamp "J1939-73";
BA_ "Variable" SG_ 2566834721 FlashMalfuncIndicatorLamp "N/A";
BA_ "Status" SG_ 2566834721 FlashMalfuncIndicatorLamp "Ok";
BA_ "SPN" SG_ 2566834721 FlashAmberWarningLamp 3040;
BA_ "SAEDocument" SG_ 2566834721 FlashAmberWarningLamp "J1939-73";
BA_ "Variable" SG_ 2566834721 FlashAmberWarningLamp "N/A";
BA_ "Status" SG_ 2566834721 FlashAmberWarningLamp "Ok";
BA_ "SigType" SG_ 2566834721 OccurenceCount1 "RANGE";
BA_ "SPN" SG_ 2566834721 OccurenceCount1 1216;
BA_ "SAEDocument" SG_ 2566834721 OccurenceCount1 "J1939-73";
BA_ "Variable" SG_ 2566834721 OccurenceCount1 "N/A";
BA_ "Status" SG_ 2566834721 OccurenceCount1 "Ok";
BA_ "SPN" SG_ 2566834721 SPNConversionMethod1 1706;
BA_ "SAEDocument" SG_ 2566834721 SPNConversionMethod1 "J1939-73";
BA_ "Variable" SG_ 2566834721 SPNConversionMethod1 "N/A";
BA_ "Status" SG_ 2566834721 SPNConversionMethod1 "Ok";
BA_ "SAEDocument" SG_ 2566834721 SPNConversionMethod5 "J1939-73";
BA_ "Variable" SG_ 2566834721 SPNConversionMethod5 "N/A";
BA_ "Status" SG_ 2566834721 SPNConversionMethod5 "Ok";
BA_ "SPN" SG_ 2566834721 SPNConversionMethod5 1706;
BA_ "SAEDocument" SG_ 2566834721 SPNConversionMethod4 "J1939-73";
BA_ "Variable" SG_ 2566834721 SPNConversionMethod4 "N/A";
BA_ "Status" SG_ 2566834721 SPNConversionMethod4 "Ok";
BA_ "SPN" SG_ 2566834721 SPNConversionMethod4 1706;
BA_ "SAEDocument" SG_ 2566834721 SPNConversionMethod3 "J1939-73";
BA_ "Variable" SG_ 2566834721 SPNConversionMethod3 "N/A";
BA_ "Status" SG_ 2566834721 SPNConversionMethod3 "Ok";
BA_ "SPN" SG_ 2566834721 SPNConversionMethod3 1706;
BA_ "SAEDocument" SG_ 2566834721 SPNConversionMethod2 "J1939-73";
BA_ "Variable" SG_ 2566834721 SPNConversionMethod2 "N/A";
BA_ "Status" SG_ 2566834721 SPNConversionMethod2 "Ok";
BA_ "SPN" SG_ 2566834721 SPNConversionMethod2 1706;
BA_ "SigType" SG_ 2566834721 OccurenceCount5 "RANGE";
BA_ "SAEDocument" SG_ 2566834721 OccurenceCount5 "J1939-73";
BA_ "Variable" SG_ 2566834721 OccurenceCount5 "N/A";
BA_ "Status" SG_ 2566834721 OccurenceCount5 "Ok";
BA_ "SPN" SG_ 2566834721 OccurenceCount5 1216;
BA_ "SigType" SG_ 2566834721 OccurenceCount4 "RANGE";
BA_ "SAEDocument" SG_ 2566834721 OccurenceCount4 "J1939-73";
BA_ "Variable" SG_ 2566834721 OccurenceCount4 "N/A";
BA_ "Status" SG_ 2566834721 OccurenceCount4 "Ok";
BA_ "SPN" SG_ 2566834721 OccurenceCount4 1216;
BA_ "SigType" SG_ 2566834721 OccurenceCount3 "RANGE";
BA_ "SAEDocument" SG_ 2566834721 OccurenceCount3 "J1939-73";
BA_ "Variable" SG_ 2566834721 OccurenceCount3 "N/A";
BA_ "Status" SG_ 2566834721 OccurenceCount3 "Ok";
BA_ "SPN" SG_ 2566834721 OccurenceCount3 1216;
BA_ "SigType" SG_ 2566834721 OccurenceCount2 "RANGE";
BA_ "SAEDocument" SG_ 2566834721 OccurenceCount2 "J1939-73";
BA_ "Variable" SG_ 2566834721 OccurenceCount2 "N/A";
BA_ "Status" SG_ 2566834721 OccurenceCount2 "Ok";
BA_ "SPN" SG_ 2566834721 OccurenceCount2 1216;
BA_ "SAEDocument" SG_ 2566834721 SPN5High "J1939-73";
BA_ "Variable" SG_ 2566834721 SPN5High "N/A";
BA_ "Status" SG_ 2566834721 SPN5High "Ok";
BA_ "SPN" SG_ 2566834721 SPN5High 1214;
BA_ "SAEDocument" SG_ 2566834721 SPN4High "J1939-73";
BA_ "Variable" SG_ 2566834721 SPN4High "N/A";
BA_ "Status" SG_ 2566834721 SPN4High "Ok";
BA_ "SPN" SG_ 2566834721 SPN4High 1214;
BA_ "SAEDocument" SG_ 2566834721 SPN3High "J1939-73";
BA_ "Variable" SG_ 2566834721 SPN3High "N/A";
BA_ "Status" SG_ 2566834721 SPN3High "Ok";
BA_ "SPN" SG_ 2566834721 SPN3High 1214;
BA_ "SAEDocument" SG_ 2566834721 SPN2High "J1939-73";
BA_ "Variable" SG_ 2566834721 SPN2High "N/A";
BA_ "Status" SG_ 2566834721 SPN2High "Ok";
BA_ "SPN" SG_ 2566834721 SPN2High 1214;
BA_ "SPN" SG_ 2566834721 SPN1High 1214;
BA_ "SAEDocument" SG_ 2566834721 SPN1High "J1939-73";
BA_ "Variable" SG_ 2566834721 SPN1High "N/A";
BA_ "Status" SG_ 2566834721 SPN1High "Ok";
VAL_ 2560818944 FailureModeIdentifier1 31 "Not available" 19 "Received network data in error" 18 "Below normal (moderatels severe)" 17 "Below normal (least severe)" 16 "Above normal (moderately severe)" 15 "Above normal (least severe)" 14 "Special intstructions" 13 "Out of calibration" 12 "Bad intelligent device" 11 "Root cause not known" 10 "Abnormal rate of change" 9 "Abnormal update rate" 8 "Abnormal frequency" 7 "Mechanical system not responding" 6 "Current above normal" 5 "Current below normal" 4 "Voltage below normal" 3 "Voltage above normal" 2 "Data erratic" 1 "Below normal (most severe)" 0 "Above normal (most severe)" ;
VAL_ 2560818944 FailureModeIdentifier2 31 "Not available" 19 "Received network data in error" 18 "Below normal (moderatels severe)" 17 "Below normal (least severe)" 16 "Above normal (moderately severe)" 15 "Above normal (least severe)" 14 "Special intstructions" 13 "Out of calibration" 12 "Bad intelligent device" 11 "Root cause not known" 10 "Abnormal rate of change" 9 "Abnormal update rate" 8 "Abnormal frequency" 7 "Mechanical system not responding" 6 "Current above normal" 5 "Current below normal" 4 "Voltage below normal" 3 "Voltage above normal" 2 "Data erratic" 1 "Below normal (most severe)" 0 "Above normal (most severe)" ;
VAL_ 2348814091 EngOverrideCtrlMode 3 "Spd_TrqLmtCtrlLmtSpdAnd_OrTrqBs" 2 "TrqCtrlCntrlTrqTInclddDsrdTrqVl" 1 "SpdCtrlGvrnSpdTInclddDsrdSpdVle" 0 "OvrrdDsbldDsblAnyExstngCtrlCmdd" ;
VAL_ 2348814091 OverrideCtrlModePriority 3 "LowPriority" 2 "MdmPrrtyUsdFrPwrtrnCtrlOprtnsWh" 1 "HighPriority" 0 "HghstPrrtyUsdFrSttnsThtRqrImmdt" ;
VAL_ 2348814083 OverrideCtrlModePriority 3 "LowPriority" 2 "MdmPrrtyUsdFrPwrtrnCtrlOprtnsWh" 1 "HighPriority" 0 "HghstPrrtyUsdFrSttnsThtRqrImmdt" ;
VAL_ 2348814083 EngOverrideCtrlMode 3 "Spd_TrqLmtCtrlLmtSpdAnd_OrTrqBs" 2 "TrqCtrlCntrlTrqTInclddDsrdTrqVl" 1 "SpdCtrlGvrnSpdTInclddDsrdSpdVle" 0 "OvrrdDsbldDsblAnyExstngCtrlCmdd" ;
VAL_ 2566804992 AftSCROperatorInducementSeverity 7 "Not Available / Not Supported" 6 "Reserved" 5 "Inducement Level 5" 4 "Inducement Level 4" 3 "Inducement Level 3" 2 "Inducement Level 2" 1 "Inducement Level 1" 0 "No Inducement Active" ;
VAL_ 2566804992 Aft1DEFtankLowlevelIndicator 7 "not available" 6 "reserved for SAE assignment" 5 "reserved for SAE assignment" 4 "On – fast blink (1 HZ)" 3 "reserved for SAE assignment" 2 "reserved for SAE assignment" 1 "On – solid" 0 "Off" ;
VAL_ 2633974265 PropResetInfo 255 "Not avalable" 254 "Error" 1 "Reset vehicle event data" 0 "No reset" ;
VAL_ 2348814122 EngOverrideCtrlMode 3 "Spd_TrqLmtCtrlLmtSpdAnd_OrTrqBs" 2 "TrqCtrlCntrlTrqTInclddDsrdTrqVl" 1 "SpdCtrlGvrnSpdTInclddDsrdSpdVle" 0 "OvrrdDsbldDsblAnyExstngCtrlCmdd" ;
VAL_ 2348814122 OverrideCtrlModePriority 3 "LowPriority" 2 "MdmPrrtyUsdFrPwrtrnCtrlOprtnsWh" 1 "HighPriority" 0 "HghstPrrtyUsdFrSttnsThtRqrImmdt" ;
VAL_ 2566803754 ReqACCDistMode 7 "Not available" 6 "Error condition" 5 "Not defined" 4 "Req  ACC Dist Mode #5 (shortest)" 3 "Req  ACC Dist Mode #4" 2 "Req  ACC Dist Mode #3" 1 "Req  ACC Dist Mode #2" 0 "Req  ACC Dist Mode #1 (largest)" ;
VAL_ 2631859961 EST_Trip_Reset 2 "Reserved" 3 "NotApplicable" 1 "Reset" 0 "TakeNoAction" ;
VAL_ 2561081377 GovSelSwitch 3 "Not available" 2 "Error" 1 "On" 0 "Off" ;
VAL_ 2561081377 DataLogSwitch 3 "Not available" 2 "Error" 1 "On" 0 "Off" ;
VAL_ 2566844714 CruiseCtrlResumeSwitch 3 "NotAvailable" 2 "Error" 1 "CruiseCtrlActivatorInPosResume" 0 "CrseCtrlActivatorNotInPosResume" ;
VAL_ 2566844714 CruiseCtrlPauseSwitch 3 "TakeNoAction" 2 "ErrorIndicator" 1 "On" 0 "Off" ;
VAL_ 2566868992 AccelInterlockStatus 3 "Not available" 2 "Error" 1 "On" 0 "Off" ;
VAL_ 2566868992 Adj_RSL_Status 3 "Not Supported" 2 "Reserved" 1 "On" 0 "Off" ;
VAL_ 2566868992 Shift_Sync_Status 15 "Not Supported" 14 "Reserved" 13 "Reserved" 12 "Reserved" 11 "Reserved" 10 "Reserved" 9 "Reserved" 8 "Reserved" 7 "Reserved" 6 "Reserved" 5 "Reserved" 4 "Reserved" 3 "Reserved" 2 "Synchronized for Downshift" 1 "Synchronized for Upshift" 0 "Not Synchronized" ;
VAL_ 2566868992 Upshift_Indicator 3 "Not Supported" 2 "Reserved" 1 "Upshift Needed" 0 "Upshift Not Needed" ;
VAL_ 2566868992 RSL_Increase_Status 3 "Not available" 2 "Reserved" 1 "Active" 0 "Not Active" ;
VAL_ 2566868992 RSL_Increase_Expiration 3 "Not available" 2 "Reserved" 1 "About to Expire" 0 "Not About to Expire" ;
VAL_ 2566868992 Driver_Reward_Lvl_Update 255 "Not available" 1 "Update Approaching" 0 "Update Not Approaching" ;
VAL_ 2566868992 Driver_Reward_Lvl 255 "Not available" 4 "Penalty" 3 "Excellent" 2 "Good" 1 "Expected" 0 "Off" ;
VAL_ 2566861857 EngineWarmupEnable 3 "Not Available" 2 "Error" 1 "Warmup enabled" 0 "Warmup disabled" ;
VAL_ 2566848256 WIF 3 "Not Available" 2 "Error" 1 "Yes" 0 "No" ;
VAL_ 2565865728 EngAuxEngShutdownSwitch 3 "NotAvailable" 2 "Error" 1 "On" 0 "Off" ;
VAL_ 2565865728 EngDerateSwitch 3 "NotAvailable" 2 "Error" 1 "On" 0 "Off" ;
VAL_ 2565865728 AntiLockBrakingActive 3 "NotAvailable" 2 "Reserved" 1 "ABSActive" 0 "ABSPassiveButInstalled" ;
VAL_ 2432593664 AdptveCruiseCtrlSetDistanceMode 7 "NotAvailable_NotValid" 6 "ErrorCondition" 5 "ConventionalCruiseCtrlMode" 4 "ACCDistanceMode5" 3 "ACCDistanceMode4" 2 "ACCDistanceMode3" 1 "ACCDistanceMode2" 0 "ACCDistanceMode1" ;
VAL_ 2432593664 AdaptiveCruiseCtrlMode 7 "NotAvailable_NotValid" 6 "DsbldErrrCndtnUsdTIndctThtACCIs" 5 "FinishMode" 4 "HldMdUsdTIndctThtACCHsLstThPrvs" 3 "OvertakeMode" 2 "DstncCtrlActvUsdTIndctThtACCIsO" 1 "SpeedCtrlActive" 0 "OffUsdTIndctACCIsEnbldInClbCnfg" ;
VAL_ 2566844416 EngPTOAccelerateSwitch 3 "NotAvailable" 2 "Error" 1 "On" 0 "Off" ;
VAL_ 2566844416 EngPTOResumeSwitch 3 "NotAvailable" 2 "Error" 1 "On" 0 "Off" ;
VAL_ 2566844416 EngPTOCoast_DecelerateSwitch 3 "NotAvailable" 2 "Error" 1 "On" 0 "Off" ;
VAL_ 2566844416 EngPTOSetSwitch 3 "NotAvailable" 2 "Error" 1 "On" 0 "Off" ;
VAL_ 2566844416 EngRmtPTOVriableSpeedCtrlSwitch 3 "NotAvailable" 2 "Error" 1 "On" 0 "Off" ;
VAL_ 2566844416 EngRmtPTOPrprgrmmdSpdCtrlSwitch 3 "NotAvailable" 2 "Error" 1 "On" 0 "Off" ;
VAL_ 2566844416 EngPTOEnableSwitch 3 "NotAvailable" 2 "Error" 1 "On" 0 "Off" ;
VAL_ 2566844416 RmtPTOPrprgrmmdSpeedCtrlSwitch2 3 "NotAvailable" 2 "Error" 1 "On" 0 "Off" ;
VAL_ 2348810282 EngOverrideCtrlMode 3 "Spd_TrqLmtCtrlLmtSpdAnd_OrTrqBs" 2 "TrqCtrlCntrlTrqTInclddDsrdTrqVl" 1 "SpdCtrlGvrnSpdTInclddDsrdSpdVle" 0 "OvrrdDsbldDsblAnyExstngCtrlCmdd" ;
VAL_ 2348810282 OverrideCtrlModePriority 3 "LowPriority" 2 "MdmPrrtyUsdFrPwrtrnCtrlOprtnsWh" 1 "HighPriority" 0 "HghstPrrtyUsdFrSttnsThtRqrImmdt" ;
VAL_ 2348810251 EngOverrideCtrlMode 3 "Spd_TrqLmtCtrlLmtSpdAnd_OrTrqBs" 2 "TrqCtrlCntrlTrqTInclddDsrdTrqVl" 1 "SpdCtrlGvrnSpdTInclddDsrdSpdVle" 0 "OvrrdDsbldDsblAnyExstngCtrlCmdd" ;
VAL_ 2348810251 OverrideCtrlModePriority 3 "LowPriority" 2 "MdmPrrtyUsdFrPwrtrnCtrlOprtnsWh" 1 "HighPriority" 0 "HghstPrrtyUsdFrSttnsThtRqrImmdt" ;
VAL_ 2565668641 PGNumber 255 "NotAvailable" ;
VAL_ 2565668641 ControlByte 24 "EAbort" 23 "EEoMACK" 22 "EDPO" 21 "ECTS" 20 "ERTS" 3 "CannotRespond" 2 "AccessDenied" 1 "NACK" 0 "ACK" 255 "Abort" 32 "BAM" 19 "EoMA" 17 "CTS" 16 "RTS" ;
VAL_ 2565611799 PGNumber 255 "NotAvailable" ;
VAL_ 2565611799 ControlByte 24 "EAbort" 23 "EEoMACK" 22 "EDPO" 21 "ECTS" 20 "ERTS" 3 "CannotRespond" 2 "AccessDenied" 1 "NACK" 0 "ACK" 255 "Abort" 32 "BAM" 19 "EoMA" 17 "CTS" 16 "RTS" ;
VAL_ 2565603351 PGNumber 255 "NotAvailable" ;
VAL_ 2565603351 ControlByte 24 "EAbort" 23 "EEoMACK" 22 "EDPO" 21 "ECTS" 20 "ERTS" 3 "CannotRespond" 2 "AccessDenied" 1 "NACK" 0 "ACK" 255 "Abort" 32 "BAM" 19 "EoMA" 17 "CTS" 16 "RTS" ;
VAL_ 2565668631 PGNumber 255 "NotAvailable" ;
VAL_ 2565668631 ControlByte 24 "EAbort" 23 "EEoMACK" 22 "EDPO" 21 "ECTS" 20 "ERTS" 3 "CannotRespond" 2 "AccessDenied" 1 "NACK" 0 "ACK" 255 "Abort" 32 "BAM" 19 "EoMA" 17 "CTS" 16 "RTS" ;
VAL_ 2565865761 ABSFullyOperational 3 "NotAvailable" 2 "Reserved" 1 "FullyOperational" 0 "NotFullyOperational" ;
VAL_ 2565865761 EngAuxEngShutdownSwitch 3 "NotAvailable" 2 "Error" 1 "On" 0 "Off" ;
VAL_ 2565865761 EngDerateSwitch 3 "NotAvailable" 2 "Error" 1 "On" 0 "Off" ;
VAL_ 2565865761 AccelInterlockSwitch 3 "NotAvailable" 2 "Error" 1 "On" 0 "Off" ;
VAL_ 2565865761 TractionCtrlOverrideSwitch 3 "NotAvailableNotInstalled" 2 "Error" 1 "On" 0 "Off" ;
VAL_ 2565865761 AntiLockBrakingActive 3 "NotAvailable" 2 "Reserved" 1 "ABSActive" 0 "ABSPassiveButInstalled" ;
VAL_ 2566834977 FailureModeIdentifier5 31 "Not available" 19 "Received network data in error" 18 "Below normal (moderatels severe)" 17 "Below normal (least severe)" 16 "Above normal (moderately severe)" 15 "Above normal (least severe)" 14 "Special intstructions" 13 "Out of calibration" 12 "Bad intelligent device" 11 "Root cause not known" 10 "Abnormal rate of change" 9 "Abnormal update rate" 8 "Abnormal frequency" 7 "Mechanical system not responding" 6 "Current above normal" 5 "Current below normal" 4 "Voltage below normal" 3 "Voltage above normal" 2 "Data erratic" 1 "Below normal (most severe)" 0 "Above normal (most severe)" ;
VAL_ 2566834977 FailureModeIdentifier4 31 "Not available" 19 "Received network data in error" 18 "Below normal (moderatels severe)" 17 "Below normal (least severe)" 16 "Above normal (moderately severe)" 15 "Above normal (least severe)" 14 "Special intstructions" 13 "Out of calibration" 12 "Bad intelligent device" 11 "Root cause not known" 10 "Abnormal rate of change" 9 "Abnormal update rate" 8 "Abnormal frequency" 7 "Mechanical system not responding" 6 "Current above normal" 5 "Current below normal" 4 "Voltage below normal" 3 "Voltage above normal" 2 "Data erratic" 1 "Below normal (most severe)" 0 "Above normal (most severe)" ;
VAL_ 2566834977 FailureModeIdentifier3 31 "Not available" 19 "Received network data in error" 18 "Below normal (moderatels severe)" 17 "Below normal (least severe)" 16 "Above normal (moderately severe)" 15 "Above normal (least severe)" 14 "Special intstructions" 13 "Out of calibration" 12 "Bad intelligent device" 11 "Root cause not known" 10 "Abnormal rate of change" 9 "Abnormal update rate" 8 "Abnormal frequency" 7 "Mechanical system not responding" 6 "Current above normal" 5 "Current below normal" 4 "Voltage below normal" 3 "Voltage above normal" 2 "Data erratic" 1 "Below normal (most severe)" 0 "Above normal (most severe)" ;
VAL_ 2566834977 FailureModeIdentifier2 31 "Not available" 19 "Received network data in error" 18 "Below normal (moderatels severe)" 17 "Below normal (least severe)" 16 "Above normal (moderately severe)" 15 "Above normal (least severe)" 14 "Special intstructions" 13 "Out of calibration" 12 "Bad intelligent device" 11 "Root cause not known" 10 "Abnormal rate of change" 9 "Abnormal update rate" 8 "Abnormal frequency" 7 "Mechanical system not responding" 6 "Current above normal" 5 "Current below normal" 4 "Voltage below normal" 3 "Voltage above normal" 2 "Data erratic" 1 "Below normal (most severe)" 0 "Above normal (most severe)" ;
VAL_ 2566834977 FailureModeIdentifier1 31 "Not available" 19 "Received network data in error" 18 "Below normal (moderatels severe)" 17 "Below normal (least severe)" 16 "Above normal (moderately severe)" 15 "Above normal (least severe)" 14 "Special intstructions" 13 "Out of calibration" 12 "Bad intelligent device" 11 "Root cause not known" 10 "Abnormal rate of change" 9 "Abnormal update rate" 8 "Abnormal frequency" 7 "Mechanical system not responding" 6 "Current above normal" 5 "Current below normal" 4 "Voltage below normal" 3 "Voltage above normal" 2 "Data erratic" 1 "Below normal (most severe)" 0 "Above normal (most severe)" ;
VAL_ 2566834977 FlashRedStopLamp 3 "Unavailable / Do Not Flash" 2 "Reserved" 1 "Fast Flash" 0 "Slow Flash" ;
VAL_ 2566834977 FlashProtectLamp 3 "Unavailable / Do Not Flash" 2 "Reserved" 1 "Fast Flash" 0 "Slow Flash" ;
VAL_ 2566834977 FlashMalfuncIndicatorLamp 3 "Unavailable / Do Not Flash" 2 "Reserved" 1 "Fast Flash" 0 "Slow Flash" ;
VAL_ 2566834977 FlashAmberWarningLamp 3 "Unavailable / Do Not Flash" 2 "Reserved" 1 "Fast Flash" 0 "Slow Flash" ;
VAL_ 2566834977 RedStopLampStatus 3 "Not available" 2 "Reserved" 1 "Lamp on" 0 "Lamp off" ;
VAL_ 2566834977 ProtectLampStatus 3 "Not available" 2 "Reserved" 1 "Lamp on" 0 "Lamp off" ;
VAL_ 2566834977 AmberWarningLampStatus 3 "Not available" 2 "Reserved" 1 "Lamp on" 0 "Lamp off" ;
VAL_ 2566834977 MalfunctionIndicatorLampStatus 3 "Not available" 2 "Reserved" 1 "Lamp on" 0 "Lamp off" ;
VAL_ 2566834967 FailureModeIdentifier5 31 "Not available" 19 "Received network data in error" 18 "Below normal (moderatels severe)" 17 "Below normal (least severe)" 16 "Above normal (moderately severe)" 15 "Above normal (least severe)" 14 "Special intstructions" 13 "Out of calibration" 12 "Bad intelligent device" 11 "Root cause not known" 10 "Abnormal rate of change" 9 "Abnormal update rate" 8 "Abnormal frequency" 7 "Mechanical system not responding" 6 "Current above normal" 5 "Current below normal" 4 "Voltage below normal" 3 "Voltage above normal" 2 "Data erratic" 1 "Below normal (most severe)" 0 "Above normal (most severe)" ;
VAL_ 2566834967 FailureModeIdentifier4 31 "Not available" 19 "Received network data in error" 18 "Below normal (moderatels severe)" 17 "Below normal (least severe)" 16 "Above normal (moderately severe)" 15 "Above normal (least severe)" 14 "Special intstructions" 13 "Out of calibration" 12 "Bad intelligent device" 11 "Root cause not known" 10 "Abnormal rate of change" 9 "Abnormal update rate" 8 "Abnormal frequency" 7 "Mechanical system not responding" 6 "Current above normal" 5 "Current below normal" 4 "Voltage below normal" 3 "Voltage above normal" 2 "Data erratic" 1 "Below normal (most severe)" 0 "Above normal (most severe)" ;
VAL_ 2566834967 FailureModeIdentifier3 31 "Not available" 19 "Received network data in error" 18 "Below normal (moderatels severe)" 17 "Below normal (least severe)" 16 "Above normal (moderately severe)" 15 "Above normal (least severe)" 14 "Special intstructions" 13 "Out of calibration" 12 "Bad intelligent device" 11 "Root cause not known" 10 "Abnormal rate of change" 9 "Abnormal update rate" 8 "Abnormal frequency" 7 "Mechanical system not responding" 6 "Current above normal" 5 "Current below normal" 4 "Voltage below normal" 3 "Voltage above normal" 2 "Data erratic" 1 "Below normal (most severe)" 0 "Above normal (most severe)" ;
VAL_ 2566834967 FailureModeIdentifier2 31 "Not available" 19 "Received network data in error" 18 "Below normal (moderatels severe)" 17 "Below normal (least severe)" 16 "Above normal (moderately severe)" 15 "Above normal (least severe)" 14 "Special intstructions" 13 "Out of calibration" 12 "Bad intelligent device" 11 "Root cause not known" 10 "Abnormal rate of change" 9 "Abnormal update rate" 8 "Abnormal frequency" 7 "Mechanical system not responding" 6 "Current above normal" 5 "Current below normal" 4 "Voltage below normal" 3 "Voltage above normal" 2 "Data erratic" 1 "Below normal (most severe)" 0 "Above normal (most severe)" ;
VAL_ 2566834967 FailureModeIdentifier1 31 "Not available" 19 "Received network data in error" 18 "Below normal (moderatels severe)" 17 "Below normal (least severe)" 16 "Above normal (moderately severe)" 15 "Above normal (least severe)" 14 "Special intstructions" 13 "Out of calibration" 12 "Bad intelligent device" 11 "Root cause not known" 10 "Abnormal rate of change" 9 "Abnormal update rate" 8 "Abnormal frequency" 7 "Mechanical system not responding" 6 "Current above normal" 5 "Current below normal" 4 "Voltage below normal" 3 "Voltage above normal" 2 "Data erratic" 1 "Below normal (most severe)" 0 "Above normal (most severe)" ;
VAL_ 2566834967 FlashRedStopLamp 3 "Unavailable / Do Not Flash" 2 "Reserved" 1 "Fast Flash" 0 "Slow Flash" ;
VAL_ 2566834967 FlashProtectLamp 3 "Unavailable / Do Not Flash" 2 "Reserved" 1 "Fast Flash" 0 "Slow Flash" ;
VAL_ 2566834967 FlashMalfuncIndicatorLamp 3 "Unavailable / Do Not Flash" 2 "Reserved" 1 "Fast Flash" 0 "Slow Flash" ;
VAL_ 2566834967 FlashAmberWarningLamp 3 "Unavailable / Do Not Flash" 2 "Reserved" 1 "Fast Flash" 0 "Slow Flash" ;
VAL_ 2566834967 RedStopLampStatus 3 "Not available" 2 "Reserved" 1 "Lamp on" 0 "Lamp off" ;
VAL_ 2566834967 ProtectLampStatus 3 "Not available" 2 "Reserved" 1 "Lamp on" 0 "Lamp off" ;
VAL_ 2566834967 AmberWarningLampStatus 3 "Not available" 2 "Reserved" 1 "Lamp on" 0 "Lamp off" ;
VAL_ 2566834967 MalfunctionIndicatorLampStatus 3 "Not available" 2 "Reserved" 1 "Lamp on" 0 "Lamp off" ;
VAL_ 2566834721 FailureModeIdentifier5 31 "Not available" 19 "Received network data in error" 18 "Below normal (moderatels severe)" 17 "Below normal (least severe)" 16 "Above normal (moderately severe)" 15 "Above normal (least severe)" 14 "Special intstructions" 13 "Out of calibration" 12 "Bad intelligent device" 11 "Root cause not known" 10 "Abnormal rate of change" 9 "Abnormal update rate" 8 "Abnormal frequency" 7 "Mechanical system not responding" 6 "Current above normal" 5 "Current below normal" 4 "Voltage below normal" 3 "Voltage above normal" 2 "Data erratic" 1 "Below normal (most severe)" 0 "Above normal (most severe)" ;
VAL_ 2566834721 FailureModeIdentifier4 31 "Not available" 19 "Received network data in error" 18 "Below normal (moderatels severe)" 17 "Below normal (least severe)" 16 "Above normal (moderately severe)" 15 "Above normal (least severe)" 14 "Special intstructions" 13 "Out of calibration" 12 "Bad intelligent device" 11 "Root cause not known" 10 "Abnormal rate of change" 9 "Abnormal update rate" 8 "Abnormal frequency" 7 "Mechanical system not responding" 6 "Current above normal" 5 "Current below normal" 4 "Voltage below normal" 3 "Voltage above normal" 2 "Data erratic" 1 "Below normal (most severe)" 0 "Above normal (most severe)" ;
VAL_ 2566834721 FailureModeIdentifier3 31 "Not available" 19 "Received network data in error" 18 "Below normal (moderatels severe)" 17 "Below normal (least severe)" 16 "Above normal (moderately severe)" 15 "Above normal (least severe)" 14 "Special intstructions" 13 "Out of calibration" 12 "Bad intelligent device" 11 "Root cause not known" 10 "Abnormal rate of change" 9 "Abnormal update rate" 8 "Abnormal frequency" 7 "Mechanical system not responding" 6 "Current above normal" 5 "Current below normal" 4 "Voltage below normal" 3 "Voltage above normal" 2 "Data erratic" 1 "Below normal (most severe)" 0 "Above normal (most severe)" ;
VAL_ 2566834721 FailureModeIdentifier2 31 "Not available" 19 "Received network data in error" 18 "Below normal (moderatels severe)" 17 "Below normal (least severe)" 16 "Above normal (moderately severe)" 15 "Above normal (least severe)" 14 "Special intstructions" 13 "Out of calibration" 12 "Bad intelligent device" 11 "Root cause not known" 10 "Abnormal rate of change" 9 "Abnormal update rate" 8 "Abnormal frequency" 7 "Mechanical system not responding" 6 "Current above normal" 5 "Current below normal" 4 "Voltage below normal" 3 "Voltage above normal" 2 "Data erratic" 1 "Below normal (most severe)" 0 "Above normal (most severe)" ;
VAL_ 2566834721 FailureModeIdentifier1 31 "Not available" 19 "Received network data in error" 18 "Below normal (moderatels severe)" 17 "Below normal (least severe)" 16 "Above normal (moderately severe)" 15 "Above normal (least severe)" 14 "Special intstructions" 13 "Out of calibration" 12 "Bad intelligent device" 11 "Root cause not known" 10 "Abnormal rate of change" 9 "Abnormal update rate" 8 "Abnormal frequency" 7 "Mechanical system not responding" 6 "Current above normal" 5 "Current below normal" 4 "Voltage below normal" 3 "Voltage above normal" 2 "Data erratic" 1 "Below normal (most severe)" 0 "Above normal (most severe)" ;
VAL_ 2566834721 RedStopLampStatus 3 "Not available" 2 "Reserved" 1 "Lamp on" 0 "Lamp off" ;
VAL_ 2566834721 ProtectLampStatus 3 "Not available" 2 "Reserved" 1 "Lamp on" 0 "Lamp off" ;
VAL_ 2566834721 AmberWarningLampStatus 3 "Not available" 2 "Reserved" 1 "Lamp on" 0 "Lamp off" ;
VAL_ 2566834721 MalfunctionIndicatorLampStatus 3 "Not available" 2 "Reserved" 1 "Lamp on" 0 "Lamp off" ;
VAL_ 2566834721 FlashRedStopLamp 3 "Unavailable / Do Not Flash" 2 "Reserved" 1 "Fast Flash" 0 "Slow Flash" ;
VAL_ 2566834721 FlashProtectLamp 3 "Unavailable / Do Not Flash" 2 "Reserved" 1 "Fast Flash" 0 "Slow Flash" ;
VAL_ 2566834721 FlashMalfuncIndicatorLamp 3 "Unavailable / Do Not Flash" 2 "Reserved" 1 "Fast Flash" 0 "Slow Flash" ;
VAL_ 2566834721 FlashAmberWarningLamp 3 "Unavailable / Do Not Flash" 2 "Reserved" 1 "Fast Flash" 0 "Slow Flash" ;
BA_ "J1939PGN" 7;
